VERSION ""

NS_ :

BS_:

BU_: Turbocharger OnBoardDataLogger OffBoardDiagnosticTool2 OffBoardDiagnosticTool1 FileServer ParkingBrakeController SeatControl2 FanDriveController SteeringColumnUnit CommunicationUnitRadio CommunicationUnitSatellite CommunicationUnitCellular PropulsionBatteryCharger ChassisController2 ChassisController1 EngineValveControl AuxiliaryHeater2 AuxiliaryHeater1 ClutchUnit RampControl InformationSystem1 SuspensionSystemController2 OilSensor VehicleDynamicStability ExhaustEmissionController TransmissionDisplay2 TransmissionDisplay1 ClimateControl2 WaterPumpController RearAxleSteeringController LightingOperatorControl SeatController1 IgnitionController2 IgnitionController1 TirePressureController CabController2 CabController1 PneumaticSystemController SuspensionSystemController1 HydraulicPumpController EnduranceBrakingSystem RetarderExhaustEngine2 OnBoardDiagnosticUnit HeadwayController RetarderExhaustEngine1 CabDisplay1 ManagementComputer VirtualTerminal OffVehicleGateway PowerTakeOffFront HitchControl AuxiliaryValveControl BodyController TractorTrailerBridge1 StarterSystem ElectricalSystem VehicleSecurity VehicleNavigation AerodynamicControl ElectricalChargingSystem ClimateControl1 TripRecorder InstrumentCluster SuspensionDriveAxle2 SuspensionDriveAxle1 SuspensionSteerAxle SteeringController FuelSystem CruiseControl RetarderDriveline RetarderEngine BrakesDriveAxle2 BrakesDriveAxle1 BrakesSystemController BrakesSteerAxle AxleDrive2 AxleDrive1 AxleSteering PowerTakeOff ShiftConsoleSecondary ShiftConsolePrimary Transmission2 Transmission1 Engine2 Engine1

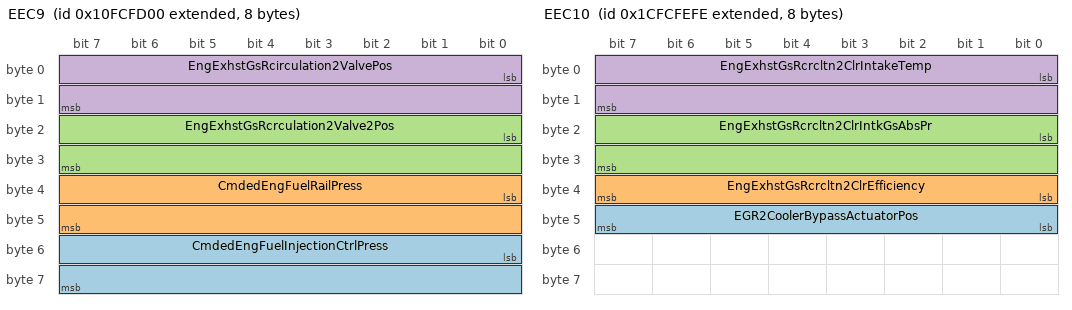
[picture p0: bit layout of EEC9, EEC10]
BO_ 2432498944 EEC9: 8 Vector__XXX
 SG_ CmdedEngFuelInjectionCtrlPress : 48|16@1+ (0.00390625,0) [0|251] "MPa" Vector__XXX
 SG_ CmdedEngFuelRailPress : 32|16@1+ (0.00390625,0) [0|251] "MPa" Vector__XXX
 SG_ EngExhstGsRcrculation2Valve2Pos : 16|16@1+ (0.0025,0) [0|160.6375] "%" Vector__XXX
 SG_ EngExhstGsRcirculation2ValvePos : 0|16@1+ (0.0025,0) [0|160.6375] "%" Vector__XXX

BO_ 2633825022 EEC11: 8 Vector__XXX
 SG_ EngExhstGsRcrclation2Valve2Ctrl : 16|16@1+ (0.0025,0) [0|160.6375] "%" Vector__XXX
 SG_ EngExhstGsRcrculation2ValveCtrl : 0|16@1+ (0.0025,0) [0|160.6375] "%" Vector__XXX

BO_ 2633826046 EEC10: 8 Vector__XXX
 SG_ EGR2CoolerBypassActuatorPos : 40|8@1+ (0.4,0) [0|100] "%" Vector__XXX
 SG_ EngExhstGsRcrcltn2ClrEfficiency : 32|8@1+ (0.4,0) [0|100] "%" Vector__XXX
 SG_ EngExhstGsRcrcltn2ClrIntkGsAbsPr : 16|16@1+ (0.5,0) [0|32127.5] "kPa" Vector__XXX
 SG_ EngExhstGsRcrcltn2ClrIntakeTemp : 0|16@1+ (0.03125,-273) [-273|1734.96875] "deg C" Vector__XXX

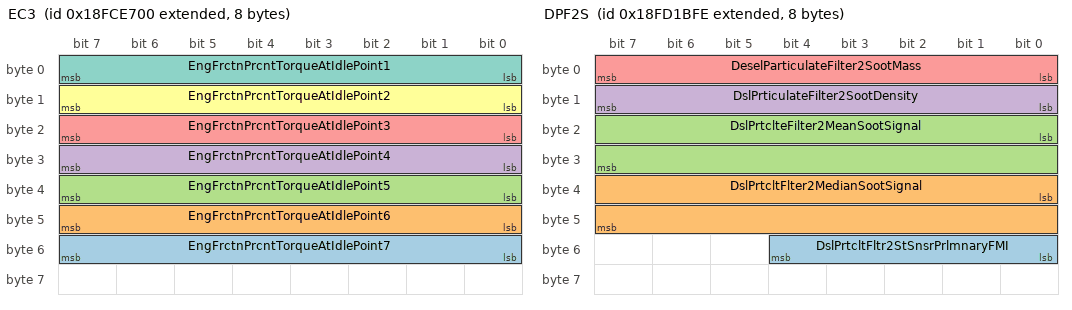
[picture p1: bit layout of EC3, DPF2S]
BO_ 2566711040 EC3: 8 Vector__XXX
 SG_ EngFrctnPrcntTorqueAtIdlePoint7 : 48|8@1+ (1,-125) [-125|125] "%" Vector__XXX
 SG_ EngFrctnPrcntTorqueAtIdlePoint6 : 40|8@1+ (1,-125) [-125|125] "%" Vector__XXX
 SG_ EngFrctnPrcntTorqueAtIdlePoint5 : 32|8@1+ (1,-125) [-125|125] "%" Vector__XXX
 SG_ EngFrctnPrcntTorqueAtIdlePoint4 : 24|8@1+ (1,-125) [-125|125] "%" Vector__XXX
 SG_ EngFrctnPrcntTorqueAtIdlePoint3 : 16|8@1+ (1,-125) [-125|125] "%" Vector__XXX
 SG_ EngFrctnPrcntTorqueAtIdlePoint2 : 8|8@1+ (1,-125) [-125|125] "%" Vector__XXX
 SG_ EngFrctnPrcntTorqueAtIdlePoint1 : 0|8@1+ (1,-125) [-125|125] "%" Vector__XXX

BO_ 2566749184 DPFC1: 8 Vector__XXX
 SG_ DslPrtcltFltrActvRgnrtnFrcdStts : 53|3@1+ (1,0) [0|7] "" Vector__XXX
 SG_ ExhaustSystemHighTempLampCmd : 50|3@1+ (1,0) [0|7] "" Vector__XXX
 SG_ DslPrtcltFltrAtmtcActvRgnrtnIntt : 48|2@1+ (1,0) [0|3] "" Vector__XXX
 SG_ DslPrtcltFltrActvRgnrtnInhbtdDTV : 46|2@1+ (1,0) [0|3] "" Vector__XXX
 SG_ DslPrtcltFltrActvRgnrtnInhbtdDTE : 44|2@1+ (1,0) [0|3] "" Vector__XXX
 SG_ DslPrtcltFltrActvRgnrtnInhbtdDTP : 42|2@1+ (1,0) [0|3] "" Vector__XXX
 SG_ DslPrtcltFltrActvRgnrtnInhbtdDTT : 40|2@1+ (1,0) [0|3] "" Vector__XXX
 SG_ DslPrtcltFltrActvRgnrtnInhbtdDTS : 38|2@1+ (1,0) [0|3] "" Vector__XXX
 SG_ DslPrtcltFltrActvRgnrtnInhb_0000 : 36|2@1+ (1,0) [0|3] "" Vector__XXX
 SG_ DslPrtcltFltrActvRgnrtnInhbtdDTL : 34|2@1+ (1,0) [0|3] "" Vector__XXX
 SG_ DslPrtcltFltrActvRgnrtnInhb_0001 : 32|2@1+ (1,0) [0|3] "" Vector__XXX
 SG_ DslPrtcltFltrActvRgnrtnInhb_0002 : 30|2@1+ (1,0) [0|3] "" Vector__XXX
 SG_ DslPrtcltFltrActvRgnrtnInhbtdDTO : 28|2@1+ (1,0) [0|3] "" Vector__XXX
 SG_ DslPrtcltFltrActvRgnrtnInhbtdDTA : 26|2@1+ (1,0) [0|3] "" Vector__XXX
 SG_ DslPrtcltFltrActvRgnrtnInhb_0003 : 24|2@1+ (1,0) [0|3] "" Vector__XXX
 SG_ DslPrtcltFltrActvRgnrtnInhb_0004 : 22|2@1+ (1,0) [0|3] "" Vector__XXX
 SG_ DslPrtcltFltrActvRgnrtnInhbtdDTC : 20|2@1+ (1,0) [0|3] "" Vector__XXX
 SG_ DslPrtcltFltrActvRgnrtnInhbtdDTI : 18|2@1+ (1,0) [0|3] "" Vector__XXX
 SG_ DslPrtcltFltrActvRgnrtnInhbtdStt : 16|2@1+ (1,0) [0|3] "" Vector__XXX
 SG_ DieselParticulateFilterStatus : 12|3@1+ (1,0) [0|7] "" Vector__XXX
 SG_ DslPrtcltFltrActvRgnrtionStatus : 10|2@1+ (1,0) [0|3] "" Vector__XXX
 SG_ DslPrtcltFltrPssvRgnrtionStatus : 8|2@1+ (1,0) [0|3] "" Vector__XXX
 SG_ DieselParticulateFilterLampCmd : 0|3@1+ (1,0) [0|7] "" Vector__XXX

BO_ 2566715646 DPF2S2: 8 Vector__XXX
 SG_ DslPrtclateFilter2SootSignalMin : 32|16@1+ (0.0025,0) [0|160.6375] "%" Vector__XXX
 SG_ DslPrtclateFilter2SootSignalMax : 16|16@1+ (0.0025,0) [0|160.6375] "%" Vector__XXX
 SG_ DslPrtcltFltr2StSgnlStndrdDvton : 0|16@1+ (0.0025,0) [0|160.6375] "%" Vector__XXX

BO_ 2566724606 DPF2S: 8 Vector__XXX
 SG_ DslPrtcltFltr2StSnsrPrlmnaryFMI : 48|5@1+ (1,0) [0|31] "" Vector__XXX
 SG_ DslPrtcltFlter2MedianSootSignal : 32|16@1+ (0.0025,0) [0|160.6375] "%" Vector__XXX
 SG_ DslPrtclteFilter2MeanSootSignal : 16|16@1+ (0.0025,0) [0|160.6375] "%" Vector__XXX
 SG_ DslPrticulateFilter2SootDensity : 8|8@1+ (0.08,0) [0|20] "g/L" Vector__XXX
 SG_ DeselParticulateFilter2SootMass : 0|8@1+ (4,0) [0|1000] "g" Vector__XXX

BO_ 2566715902 DPF1S2: 8 Vector__XXX
 SG_ DslPrtclateFilter1SootSignalMin : 32|16@1+ (0.0025,0) [0|160.6375] "%" Vector__XXX
 SG_ DslPrtclateFilter1SootSignalMax : 16|16@1+ (0.0025,0) [0|160.6375] "%" Vector__XXX
 SG_ DslPrtcltFltr1StSgnlStndrdDvton : 0|16@1+ (0.0025,0) [0|160.6375] "%" Vector__XXX

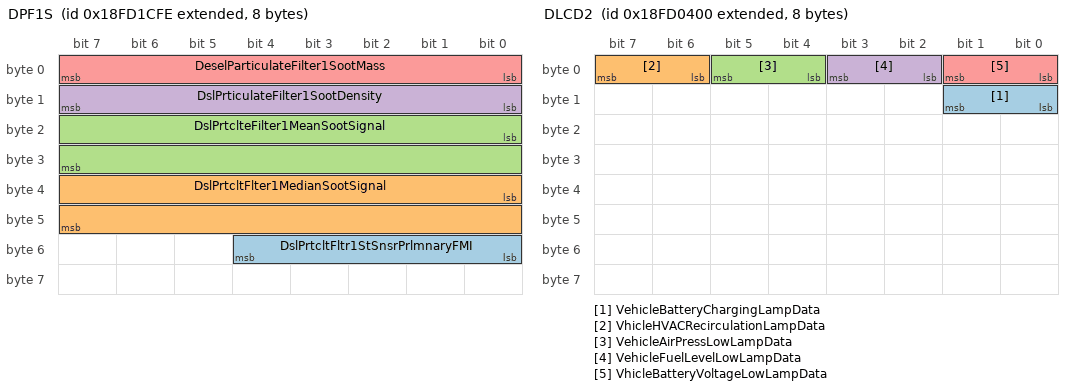
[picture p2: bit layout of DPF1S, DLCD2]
BO_ 2566724862 DPF1S: 8 Vector__XXX
 SG_ DslPrtcltFltr1StSnsrPrlmnaryFMI : 48|5@1+ (1,0) [0|31] "" Vector__XXX
 SG_ DslPrtcltFlter1MedianSootSignal : 32|16@1+ (0.0025,0) [0|160.6375] "%" Vector__XXX
 SG_ DslPrtclteFilter1MeanSootSignal : 16|16@1+ (0.0025,0) [0|160.6375] "%" Vector__XXX
 SG_ DslPrticulateFilter1SootDensity : 8|8@1+ (0.08,0) [0|20] "g/L" Vector__XXX
 SG_ DeselParticulateFilter1SootMass : 0|8@1+ (4,0) [0|1000] "g" Vector__XXX

BO_ 2566718464 DLCD2: 8 Vector__XXX
 SG_ VehicleBatteryChargingLampData : 8|2@1+ (1,0) [0|3] "" Vector__XXX
 SG_ VhicleHVACRecirculationLampData : 6|2@1+ (1,0) [0|3] "" Vector__XXX
 SG_ VehicleAirPressLowLampData : 4|2@1+ (1,0) [0|3] "" Vector__XXX
 SG_ VehicleFuelLevelLowLampData : 2|2@1+ (1,0) [0|3] "" Vector__XXX
 SG_ VhicleBatteryVoltageLowLampData : 0|2@1+ (1,0) [0|3] "" Vector__XXX

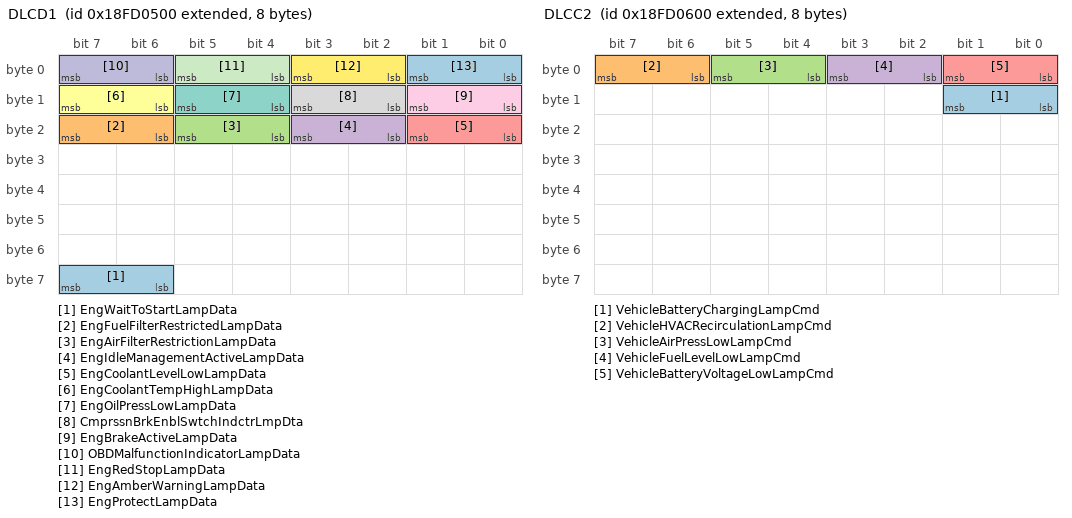
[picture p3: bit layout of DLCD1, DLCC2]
BO_ 2566718720 DLCD1: 8 Vector__XXX
 SG_ EngWaitToStartLampData : 62|2@1+ (1,0) [0|3] "" Vector__XXX
 SG_ EngFuelFilterRestrictedLampData : 22|2@1+ (1,0) [0|3] "" Vector__XXX
 SG_ EngAirFilterRestrictionLampData : 20|2@1+ (1,0) [0|3] "" Vector__XXX
 SG_ EngIdleManagementActiveLampData : 18|2@1+ (1,0) [0|3] "" Vector__XXX
 SG_ EngCoolantLevelLowLampData : 16|2@1+ (1,0) [0|3] "" Vector__XXX
 SG_ EngCoolantTempHighLampData : 14|2@1+ (1,0) [0|3] "" Vector__XXX
 SG_ EngOilPressLowLampData : 12|2@1+ (1,0) [0|3] "" Vector__XXX
 SG_ CmprssnBrkEnblSwtchIndctrLmpDta : 10|2@1+ (1,0) [0|3] "" Vector__XXX
 SG_ EngBrakeActiveLampData : 8|2@1+ (1,0) [0|3] "" Vector__XXX
 SG_ OBDMalfunctionIndicatorLampData : 6|2@1+ (1,0) [0|3] "" Vector__XXX
 SG_ EngRedStopLampData : 4|2@1+ (1,0) [0|3] "" Vector__XXX
 SG_ EngAmberWarningLampData : 2|2@1+ (1,0) [0|3] "" Vector__XXX
 SG_ EngProtectLampData : 0|2@1+ (1,0) [0|3] "" Vector__XXX

BO_ 2566718976 DLCC2: 8 Vector__XXX
 SG_ VehicleBatteryChargingLampCmd : 8|2@1+ (1,0) [0|3] "" Vector__XXX
 SG_ VehicleHVACRecirculationLampCmd : 6|2@1+ (1,0) [0|3] "" Vector__XXX
 SG_ VehicleAirPressLowLampCmd : 4|2@1+ (1,0) [0|3] "" Vector__XXX
 SG_ VehicleFuelLevelLowLampCmd : 2|2@1+ (1,0) [0|3] "" Vector__XXX
 SG_ VehicleBatteryVoltageLowLampCmd : 0|2@1+ (1,0) [0|3] "" Vector__XXX

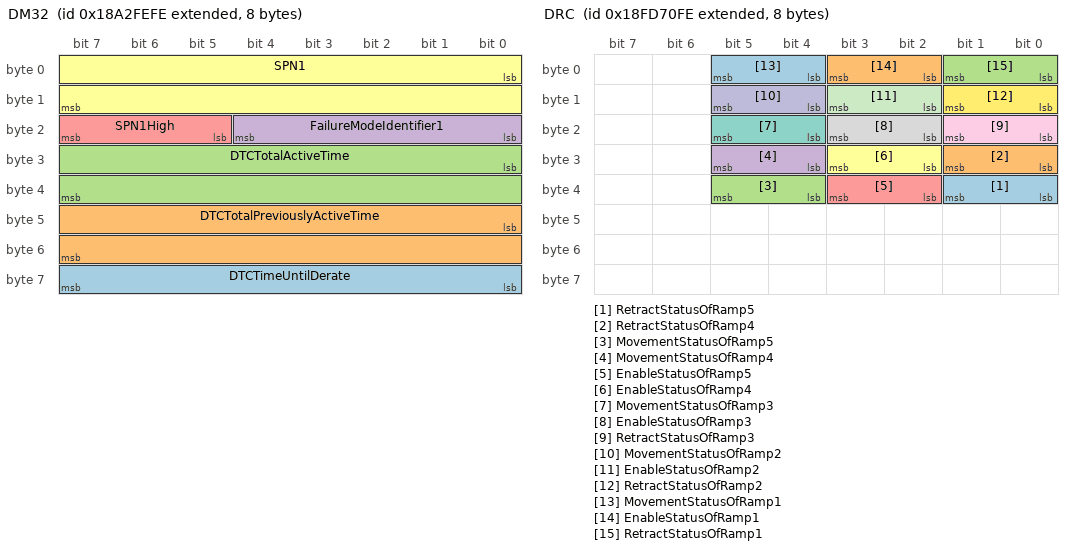
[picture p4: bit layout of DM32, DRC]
BO_ 2560818942 DM32: 8 Vector__XXX
 SG_ DTCTimeUntilDerate : 56|8@1+ (0.25,0) [0|62.5] "hr" Vector__XXX
 SG_ DTCTotalPreviouslyActiveTime : 40|16@1+ (0.2,0) [0|12851] "hr" Vector__XXX
 SG_ DTCTotalActiveTime : 24|16@1+ (0.2,0) [0|12851] "hr" Vector__XXX
 SG_ FailureModeIdentifier1 : 16|5@1+ (1,0) [0|0] "" Vector__XXX
 SG_ SPN1High : 21|3@1+ (1,0) [0|7] "" Vector__XXX
 SG_ SPN1 : 0|16@1+ (1,0) [0|65536] "" Vector__XXX

BO_ 2561212158 DISP1: 8 Vector__XXX
 SG_ TextDisplayIndex : 16|8@1+ (1,0) [0|250] "" Vector__XXX
 SG_ TextDisplayInstructions : 0|4@1+ (1,0) [0|15] "" Vector__XXX

BO_ 2566746366 DRC: 8 Vector__XXX
 SG_ RetractStatusOfRamp5 : 32|2@1+ (1,0) [0|3] "" Vector__XXX
 SG_ RetractStatusOfRamp4 : 24|2@1+ (1,0) [0|3] "" Vector__XXX
 SG_ MovementStatusOfRamp5 : 36|2@1+ (1,0) [0|3] "" Vector__XXX
 SG_ MovementStatusOfRamp4 : 28|2@1+ (1,0) [0|3] "" Vector__XXX
 SG_ EnableStatusOfRamp5 : 34|2@1+ (1,0) [0|3] "" Vector__XXX
 SG_ EnableStatusOfRamp4 : 26|2@1+ (1,0) [0|3] "" Vector__XXX
 SG_ MovementStatusOfRamp3 : 20|2@1+ (1,0) [0|3] "" Vector__XXX
 SG_ EnableStatusOfRamp3 : 18|2@1+ (1,0) [0|3] "" Vector__XXX
 SG_ RetractStatusOfRamp3 : 16|2@1+ (1,0) [0|3] "" Vector__XXX
 SG_ MovementStatusOfRamp2 : 12|2@1+ (1,0) [0|3] "" Vector__XXX
 SG_ EnableStatusOfRamp2 : 10|2@1+ (1,0) [0|3] "" Vector__XXX
 SG_ RetractStatusOfRamp2 : 8|2@1+ (1,0) [0|3] "" Vector__XXX
 SG_ MovementStatusOfRamp1 : 4|2@1+ (1,0) [0|3] "" Vector__XXX
 SG_ EnableStatusOfRamp1 : 2|2@1+ (1,0) [0|3] "" Vector__XXX
 SG_ RetractStatusOfRamp1 : 0|2@1+ (1,0) [0|3] "" Vector__XXX

BO_ 2566749952 EC2: 8 Vector__XXX
 SG_ MaxCrankAttemptsPerStartAttempt : 0|8@1+ (1,0) [0|250] "" Vector__XXX

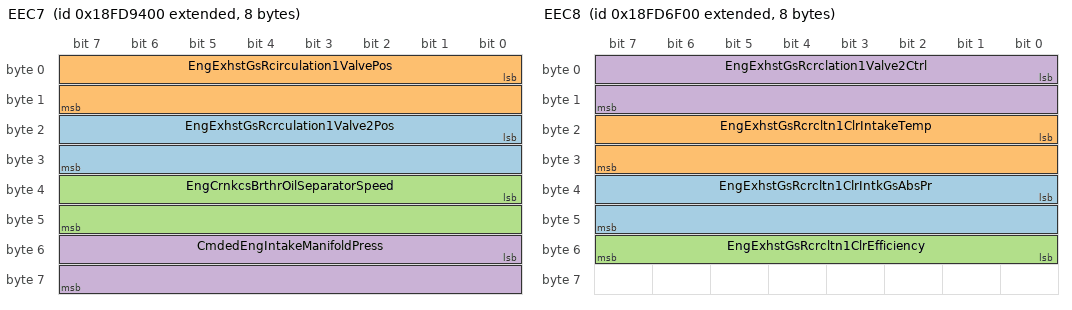
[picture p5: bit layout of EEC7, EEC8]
BO_ 2566755328 EEC7: 8 Vector__XXX
 SG_ EngExhstGsRcrculation1Valve2Pos : 16|16@1+ (0.0025,0) [0|160.6375] "%" Vector__XXX
 SG_ EngExhstGsRcirculation1ValvePos : 0|16@1+ (0.0025,0) [0|160.6375] "%" Vector__XXX
 SG_ EngCrnkcsBrthrOilSeparatorSpeed : 32|16@1+ (1,0) [0|64255] "rpm" Vector__XXX
 SG_ CmdedEngIntakeManifoldPress : 48|16@1+ (0.125,0) [0|8031.875] "kPa" Vector__XXX

BO_ 2566745856 EEC8: 8 Vector__XXX
 SG_ EngExhstGsRcrcltn1ClrIntkGsAbsPr : 32|16@1+ (0.5,0) [0|32127.5] "kPa" Vector__XXX
 SG_ EngExhstGsRcrcltn1ClrIntakeTemp : 16|16@1+ (0.03125,-273) [-273|1734.96875] "deg C" Vector__XXX
 SG_ EngExhstGsRcrcltn1ClrEfficiency : 48|8@1+ (0.4,0) [0|100] "%" Vector__XXX
 SG_ EngExhstGsRcrclation1Valve2Ctrl : 0|16@1+ (0.0025,0) [0|160.6375] "%" Vector__XXX

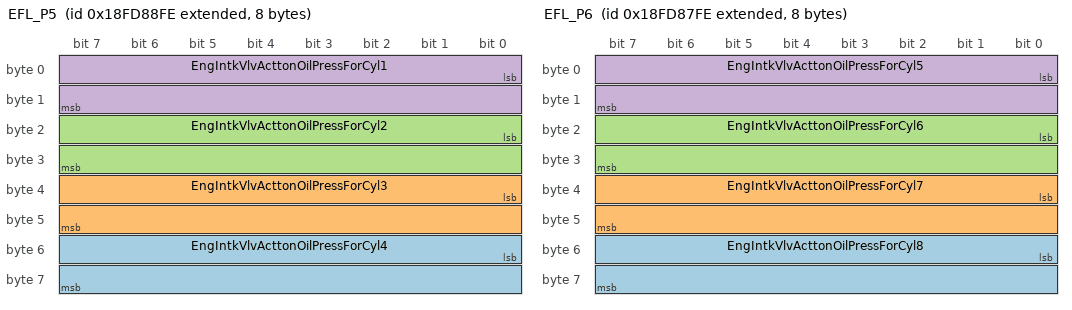
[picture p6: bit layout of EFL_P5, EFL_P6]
BO_ 2566752510 EFL_P5: 8 Vector__XXX
 SG_ EngIntkVlvActtonOilPressForCyl4 : 48|16@1+ (0.1,0) [0|6425.5] "kPa" Vector__XXX
 SG_ EngIntkVlvActtonOilPressForCyl3 : 32|16@1+ (0.1,0) [0|6425.5] "kPa" Vector__XXX
 SG_ EngIntkVlvActtonOilPressForCyl2 : 16|16@1+ (0.1,0) [0|6425.5] "kPa" Vector__XXX
 SG_ EngIntkVlvActtonOilPressForCyl1 : 0|16@1+ (0.1,0) [0|6425.5] "kPa" Vector__XXX

BO_ 2566752254 EFL_P6: 8 Vector__XXX
 SG_ EngIntkVlvActtonOilPressForCyl8 : 48|16@1+ (0.1,0) [0|6425.5] "kPa" Vector__XXX
 SG_ EngIntkVlvActtonOilPressForCyl7 : 32|16@1+ (0.1,0) [0|6425.5] "kPa" Vector__XXX
 SG_ EngIntkVlvActtonOilPressForCyl6 : 16|16@1+ (0.1,0) [0|6425.5] "kPa" Vector__XXX
 SG_ EngIntkVlvActtonOilPressForCyl5 : 0|16@1+ (0.1,0) [0|6425.5] "kPa" Vector__XXX

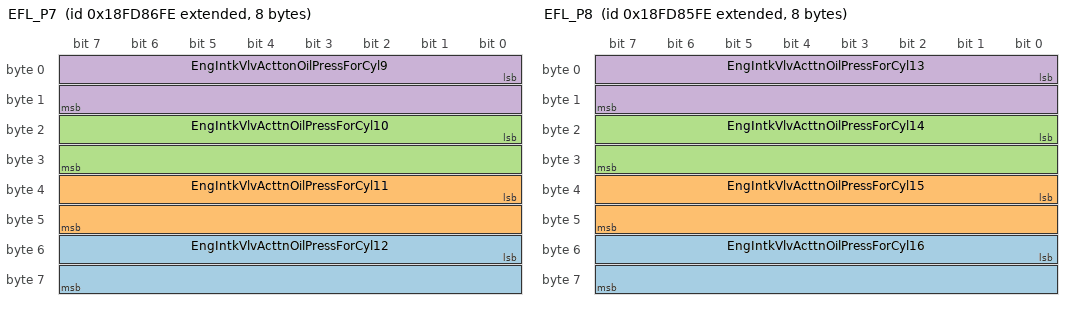
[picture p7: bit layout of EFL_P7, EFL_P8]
BO_ 2566751998 EFL_P7: 8 Vector__XXX
 SG_ EngIntkVlvActtnOilPressForCyl12 : 48|16@1+ (0.1,0) [0|6425.5] "kPa" Vector__XXX
 SG_ EngIntkVlvActtnOilPressForCyl11 : 32|16@1+ (0.1,0) [0|6425.5] "kPa" Vector__XXX
 SG_ EngIntkVlvActtnOilPressForCyl10 : 16|16@1+ (0.1,0) [0|6425.5] "kPa" Vector__XXX
 SG_ EngIntkVlvActtonOilPressForCyl9 : 0|16@1+ (0.1,0) [0|6425.5] "kPa" Vector__XXX

BO_ 2566751742 EFL_P8: 8 Vector__XXX
 SG_ EngIntkVlvActtnOilPressForCyl16 : 48|16@1+ (0.1,0) [0|6425.5] "kPa" Vector__XXX
 SG_ EngIntkVlvActtnOilPressForCyl15 : 32|16@1+ (0.1,0) [0|6425.5] "kPa" Vector__XXX
 SG_ EngIntkVlvActtnOilPressForCyl14 : 16|16@1+ (0.1,0) [0|6425.5] "kPa" Vector__XXX
 SG_ EngIntkVlvActtnOilPressForCyl13 : 0|16@1+ (0.1,0) [0|6425.5] "kPa" Vector__XXX

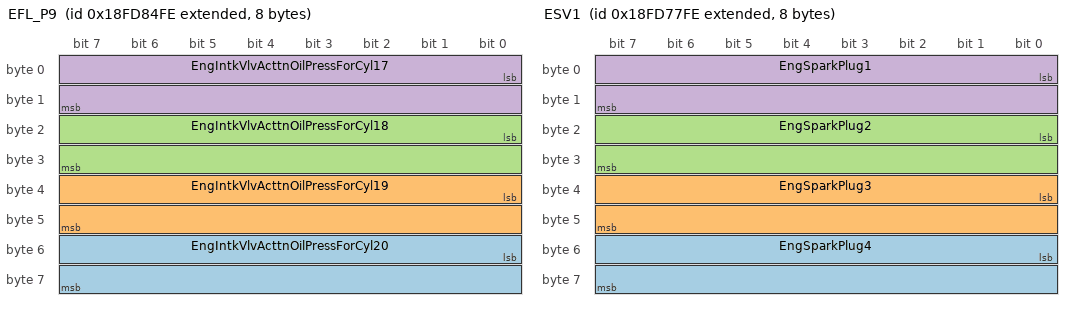
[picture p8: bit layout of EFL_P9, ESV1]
BO_ 2566751486 EFL_P9: 8 Vector__XXX
 SG_ EngIntkVlvActtnOilPressForCyl20 : 48|16@1+ (0.1,0) [0|6425.5] "kPa" Vector__XXX
 SG_ EngIntkVlvActtnOilPressForCyl19 : 32|16@1+ (0.1,0) [0|6425.5] "kPa" Vector__XXX
 SG_ EngIntkVlvActtnOilPressForCyl18 : 16|16@1+ (0.1,0) [0|6425.5] "kPa" Vector__XXX
 SG_ EngIntkVlvActtnOilPressForCyl17 : 0|16@1+ (0.1,0) [0|6425.5] "kPa" Vector__XXX

BO_ 2499641854 EGRBV: 8 Vector__XXX
 SG_ EGR1CoolerBypassActuatorPostion : 0|8@1+ (0.4,0) [0|100] "%" Vector__XXX

BO_ 2566748158 ESV1: 8 Vector__XXX
 SG_ EngSparkPlug4 : 48|16@1+ (1,0) [0|64255] "Volts" Vector__XXX
 SG_ EngSparkPlug3 : 32|16@1+ (1,0) [0|64255] "Volts" Vector__XXX
 SG_ EngSparkPlug2 : 16|16@1+ (1,0) [0|64255] "Volts" Vector__XXX
 SG_ EngSparkPlug1 : 0|16@1+ (1,0) [0|64255] "Volts" Vector__XXX

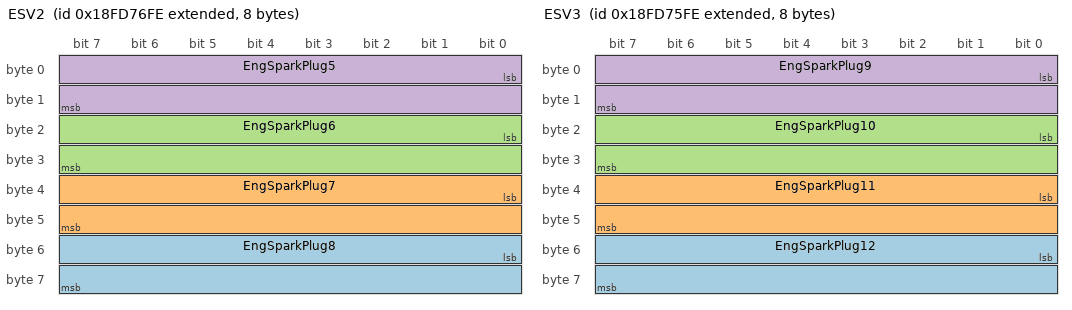
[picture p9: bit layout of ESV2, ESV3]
BO_ 2566747902 ESV2: 8 Vector__XXX
 SG_ EngSparkPlug8 : 48|16@1+ (1,0) [0|64255] "Volts" Vector__XXX
 SG_ EngSparkPlug7 : 32|16@1+ (1,0) [0|64255] "Volts" Vector__XXX
 SG_ EngSparkPlug6 : 16|16@1+ (1,0) [0|64255] "Volts" Vector__XXX
 SG_ EngSparkPlug5 : 0|16@1+ (1,0) [0|64255] "Volts" Vector__XXX

BO_ 2566747646 ESV3: 8 Vector__XXX
 SG_ EngSparkPlug12 : 48|16@1+ (1,0) [0|64255] "Volts" Vector__XXX
 SG_ EngSparkPlug11 : 32|16@1+ (1,0) [0|64255] "Volts" Vector__XXX
 SG_ EngSparkPlug10 : 16|16@1+ (1,0) [0|64255] "Volts" Vector__XXX
 SG_ EngSparkPlug9 : 0|16@1+ (1,0) [0|64255] "Volts" Vector__XXX

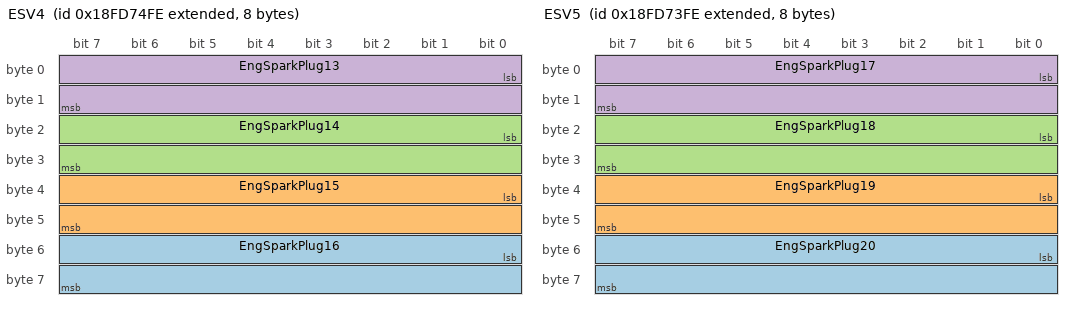
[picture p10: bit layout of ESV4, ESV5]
BO_ 2566747390 ESV4: 8 Vector__XXX
 SG_ EngSparkPlug16 : 48|16@1+ (1,0) [0|64255] "Volts" Vector__XXX
 SG_ EngSparkPlug15 : 32|16@1+ (1,0) [0|64255] "Volts" Vector__XXX
 SG_ EngSparkPlug14 : 16|16@1+ (1,0) [0|64255] "Volts" Vector__XXX
 SG_ EngSparkPlug13 : 0|16@1+ (1,0) [0|64255] "Volts" Vector__XXX

BO_ 2566747134 ESV5: 8 Vector__XXX
 SG_ EngSparkPlug20 : 48|16@1+ (1,0) [0|64255] "Volts" Vector__XXX
 SG_ EngSparkPlug19 : 32|16@1+ (1,0) [0|64255] "Volts" Vector__XXX
 SG_ EngSparkPlug18 : 16|16@1+ (1,0) [0|64255] "Volts" Vector__XXX
 SG_ EngSparkPlug17 : 0|16@1+ (1,0) [0|64255] "Volts" Vector__XXX

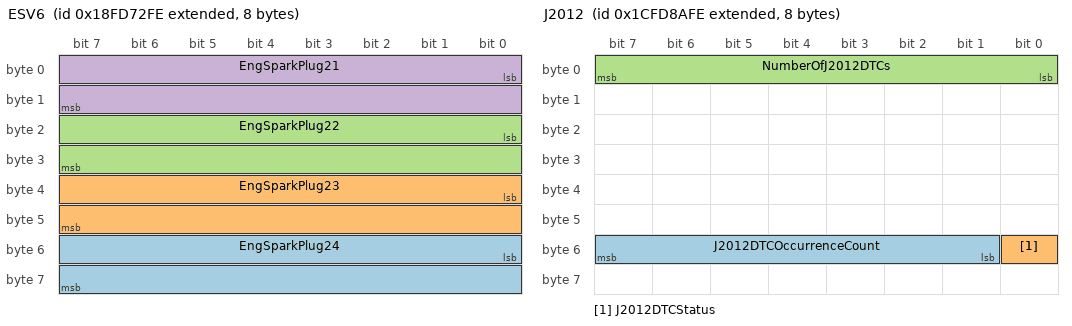
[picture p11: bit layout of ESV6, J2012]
BO_ 2566746878 ESV6: 8 Vector__XXX
 SG_ EngSparkPlug24 : 48|16@1+ (1,0) [0|64255] "Volts" Vector__XXX
 SG_ EngSparkPlug23 : 32|16@1+ (1,0) [0|64255] "Volts" Vector__XXX
 SG_ EngSparkPlug22 : 16|16@1+ (1,0) [0|64255] "Volts" Vector__XXX
 SG_ EngSparkPlug21 : 0|16@1+ (1,0) [0|64255] "Volts" Vector__XXX

BO_ 2561277694 FLIC: 8 Vector__XXX
 SG_ LaneDepartureWarningEnableCmd : 0|2@1+ (1,0) [0|3] "" Vector__XXX

BO_ 2633861886 J2012: 8 Vector__XXX
 SG_ J2012DTCOccurrenceCount : 49|7@1+ (1,0) [0|127] "" Vector__XXX
 SG_ J2012DTCStatus : 48|1@1+ (1,0) [0|1] "" Vector__XXX
 SG_ NumberOfJ2012DTCs : 0|8@1+ (1,0) [0|250] "" Vector__XXX

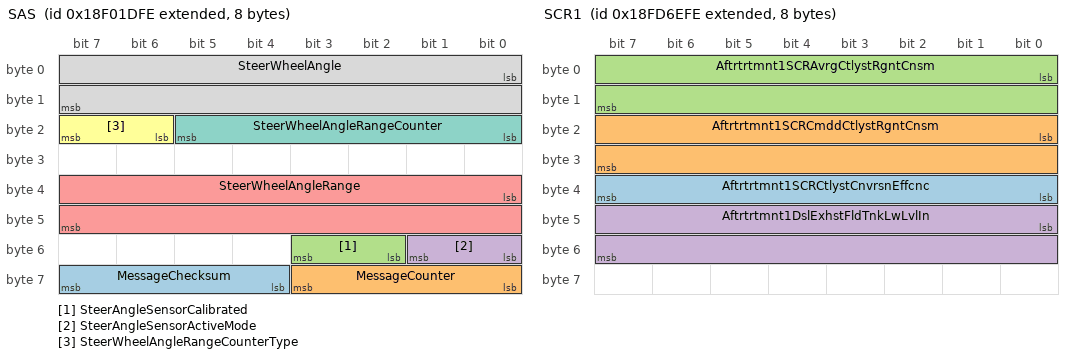
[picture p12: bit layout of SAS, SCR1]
BO_ 2565873150 SAS: 8 Vector__XXX
 SG_ MessageChecksum : 60|4@1+ (1,0) [0|15] "" Vector__XXX
 SG_ MessageCounter : 56|4@1+ (1,0) [0|15] "" Vector__XXX
 SG_ SteerAngleSensorCalibrated : 50|2@1+ (1,0) [0|3] "" Vector__XXX
 SG_ SteerAngleSensorActiveMode : 48|2@1+ (1,0) [0|3] "" Vector__XXX
 SG_ SteerWheelAngleRange : 32|16@1+ (0.0009765625,-31.374) [-31.374|31.374] "rad" Vector__XXX
 SG_ SteerWheelAngleRangeCounterType : 22|2@1+ (1,0) [0|3] "" Vector__XXX
 SG_ SteerWheelAngleRangeCounter : 16|6@1+ (1,-32) [-32|29] "ranges" Vector__XXX
 SG_ SteerWheelAngle : 0|16@1+ (0.0009765625,-31.374) [-31.374|31.374] "rad" Vector__XXX

BO_ 2566745854 SCR1: 8 Vector__XXX
 SG_ Aftrtrtmnt1SCRCtlystCnvrsnEffcnc : 32|8@1+ (0.4,0) [0|100] "%" Vector__XXX
 SG_ Aftrtrtmnt1SCRCmddCtlystRgntCnsm : 16|16@1+ (0.05,0) [0|3212.75] "L/h" Vector__XXX
 SG_ Aftrtrtmnt1SCRAvrgCtlystRgntCnsm : 0|16@1+ (0.05,0) [0|3212.75] "L/h" Vector__XXX
 SG_ Aftrtrtmnt1DslExhstFldTnkLwLvlIn : 40|16@1+ (1,0) [0|64255] "km" Vector__XXX

BO_ 2566751230 TCI: 8 Vector__XXX
 SG_ TransferCaseStatus : 0|3@1+ (1,0) [0|7] "" Vector__XXX

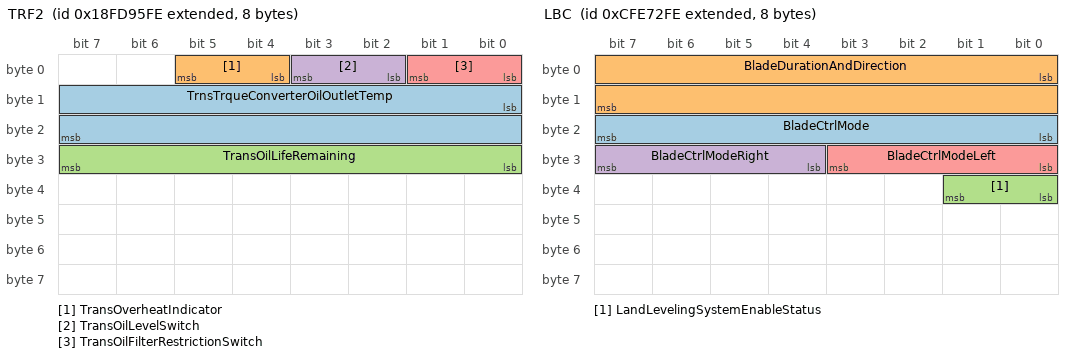
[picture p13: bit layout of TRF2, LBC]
BO_ 2566755838 TRF2: 8 Vector__XXX
 SG_ TrnsTrqueConverterOilOutletTemp : 8|16@1+ (0.03125,-273) [-273|1734.96875] "deg C" Vector__XXX
 SG_ TransOverheatIndicator : 4|2@1+ (1,0) [0|3] "" Vector__XXX
 SG_ TransOilLifeRemaining : 24|8@1+ (0.4,0) [0|100] "%" Vector__XXX
 SG_ TransOilLevelSwitch : 2|2@1+ (1,0) [0|3] "" Vector__XXX
 SG_ TransOilFilterRestrictionSwitch : 0|2@1+ (1,0) [0|3] "" Vector__XXX

BO_ 2566752766 VDS2: 8 Vector__XXX
 SG_ VehicleRoll : 0|16@1+ (0.0078125,-200) [-200|301.99] "deg" Vector__XXX

BO_ 2633938942 LF: 10 Vector__XXX
 SG_ TotalEngCruiseTime : 48|32@1+ (0.05,0) [0|210554060.75] "hr" Vector__XXX
 SG_ TotalDriveAverageLoadFactor : 40|8@1+ (0.4,0) [0|100] "%" Vector__XXX
 SG_ TripDriveAverageLoadFactor : 32|8@1+ (0.4,0) [0|100] "%" Vector__XXX
 SG_ TripAverageEngSpeed : 16|16@1+ (0.125,0) [0|8031.875] "rpm" Vector__XXX
 SG_ TripMaxEngSpeed : 0|16@1+ (0.125,0) [0|8031.875] "rpm" Vector__XXX

BO_ 2566799614 LD: 8 Vector__XXX
 SG_ ImplementRearWorkLight : 62|2@1+ (1,0) [0|3] "" Vector__XXX
 SG_ ImplementLeftForwardWorkLight : 60|2@1+ (1,0) [0|3] "" Vector__XXX
 SG_ ImplementRightForwardWorkLight : 58|2@1+ (1,0) [0|3] "" Vector__XXX
 SG_ ImplementLeftFacingWorkLight : 54|2@1+ (1,0) [0|3] "" Vector__XXX
 SG_ ImplementRightFacingWorkLight : 52|2@1+ (1,0) [0|3] "" Vector__XXX
 SG_ ImplementOEMOption1Light : 50|2@1+ (1,0) [0|3] "" Vector__XXX
 SG_ ImplementOEMOption2Light : 48|2@1+ (1,0) [0|3] "" Vector__XXX
 SG_ TrctrFrontHighMountedWorkLights : 46|2@1+ (1,0) [0|3] "" Vector__XXX
 SG_ TrctorFrontLowMountedWorkLights : 44|2@1+ (1,0) [0|3] "" Vector__XXX
 SG_ TrctorSideHighMountedWorkLights : 42|2@1+ (1,0) [0|3] "" Vector__XXX
 SG_ TractorSideLowMountedWorkLights : 40|2@1+ (1,0) [0|3] "" Vector__XXX
 SG_ TrctorRearHighMountedWorkLights : 38|2@1+ (1,0) [0|3] "" Vector__XXX
 SG_ TractorRearLowMountedWorkLights : 36|2@1+ (1,0) [0|3] "" Vector__XXX
 SG_ TrctrUndersideMountedWorkLights : 34|2@1+ (1,0) [0|3] "" Vector__XXX
 SG_ RearFogLights : 32|2@1+ (1,0) [0|3] "" Vector__XXX
 SG_ TractorMarkerLight : 30|2@1+ (1,0) [0|3] "" Vector__XXX
 SG_ ImplementMarkerLight : 28|2@1+ (1,0) [0|3] "" Vector__XXX
 SG_ TractorClearanceLight : 26|2@1+ (1,0) [0|3] "" Vector__XXX
 SG_ ImplementClearanceLight : 24|2@1+ (1,0) [0|3] "" Vector__XXX
 SG_ LeftStopLight : 22|2@1+ (1,0) [0|3] "" Vector__XXX
 SG_ RightStopLight : 20|2@1+ (1,0) [0|3] "" Vector__XXX
 SG_ CenterStopLight : 18|2@1+ (1,0) [0|3] "" Vector__XXX
 SG_ BackUpLightAndAlarmHorn : 16|2@1+ (1,0) [0|3] "" Vector__XXX
 SG_ LeftTurnSignalLights : 14|2@1+ (1,0) [0|3] "" Vector__XXX
 SG_ RightTurnSignalLights : 12|2@1+ (1,0) [0|3] "" Vector__XXX
 SG_ RotatingBeaconLight : 10|2@1+ (1,0) [0|3] "" Vector__XXX
 SG_ TractorFrontFogLights : 8|2@1+ (1,0) [0|3] "" Vector__XXX
 SG_ HighBeamHeadLightData : 6|2@1+ (1,0) [0|3] "" Vector__XXX
 SG_ LowBeamHeadLightData : 4|2@1+ (1,0) [0|3] "" Vector__XXX
 SG_ AltBeamHeadLightData : 2|2@1+ (1,0) [0|3] "" Vector__XXX
 SG_ RunningLight : 0|2@1+ (1,0) [0|3] "" Vector__XXX

BO_ 2365473278 LC: 8 Vector__XXX
 SG_ ImplementRearWorkLightCmd : 62|2@1+ (1,0) [0|3] "" Vector__XXX
 SG_ ImplmentLeftForwardWorkLightCmd : 60|2@1+ (1,0) [0|3] "" Vector__XXX
 SG_ ImplmntRightForwardWorkLightCmd : 58|2@1+ (1,0) [0|3] "" Vector__XXX
 SG_ LightingDataRqCmd : 56|2@1+ (1,0) [0|3] "" Vector__XXX
 SG_ ImplementLeftFacingWorkLightCmd : 54|2@1+ (1,0) [0|3] "" Vector__XXX
 SG_ ImplmentRightFacingWorkLightCmd : 52|2@1+ (1,0) [0|3] "" Vector__XXX
 SG_ ImplementOEMOption1LightCmd : 50|2@1+ (1,0) [0|3] "" Vector__XXX
 SG_ ImplementOEMOption2LightCmd : 48|2@1+ (1,0) [0|3] "" Vector__XXX
 SG_ TrctrFrntHghMuntedWorkLightsCmd : 46|2@1+ (1,0) [0|3] "" Vector__XXX
 SG_ TrctrFrntLwMountedWorkLightsCmd : 44|2@1+ (1,0) [0|3] "" Vector__XXX
 SG_ TrctrSdHighMountedWorkLightsCmd : 42|2@1+ (1,0) [0|3] "" Vector__XXX
 SG_ TrctrSdeLowMountedWorkLightsCmd : 40|2@1+ (1,0) [0|3] "" Vector__XXX
 SG_ TrctrRrHighMountedWorkLightsCmd : 38|2@1+ (1,0) [0|3] "" Vector__XXX
 SG_ TrctrRarLowMountedWorkLightsCmd : 36|2@1+ (1,0) [0|3] "" Vector__XXX
 SG_ TrctrUndrsdMountedWorkLightsCmd : 34|2@1+ (1,0) [0|3] "" Vector__XXX
 SG_ RearFogLightCmd : 32|2@1+ (1,0) [0|3] "" Vector__XXX
 SG_ TractorMarkerLightCmd : 30|2@1+ (1,0) [0|3] "" Vector__XXX
 SG_ ImplementMarkerLightCmd : 28|2@1+ (1,0) [0|3] "" Vector__XXX
 SG_ TractorClearanceLightCmd : 26|2@1+ (1,0) [0|3] "" Vector__XXX
 SG_ ImplementClearanceLightCmd : 24|2@1+ (1,0) [0|3] "" Vector__XXX
 SG_ LeftStopLightCmd : 22|2@1+ (1,0) [0|3] "" Vector__XXX
 SG_ RightStopLightCmd : 20|2@1+ (1,0) [0|3] "" Vector__XXX
 SG_ CenterStopLightCmd : 18|2@1+ (1,0) [0|3] "" Vector__XXX
 SG_ BackUpLightAndAlarmHornCmd : 16|2@1+ (1,0) [0|3] "" Vector__XXX
 SG_ LeftTurnSignalLightsCmd : 14|2@1+ (1,0) [0|3] "" Vector__XXX
 SG_ RightTurnSignalLightsCmd : 12|2@1+ (1,0) [0|3] "" Vector__XXX
 SG_ RotatingBeaconLightCmd : 10|2@1+ (1,0) [0|3] "" Vector__XXX
 SG_ TractorFrontFogLightsCmd : 8|2@1+ (1,0) [0|3] "" Vector__XXX
 SG_ HighBeamHeadLightCmd : 6|2@1+ (1,0) [0|3] "" Vector__XXX
 SG_ LowBeamHeadLightCmd : 4|2@1+ (1,0) [0|3] "" Vector__XXX
 SG_ AltBeamHeadLightCmd : 2|2@1+ (1,0) [0|3] "" Vector__XXX
 SG_ RunningLightCmd : 0|2@1+ (1,0) [0|3] "" Vector__XXX

BO_ 2365485822 LBC: 8 Vector__XXX
 SG_ BladeCtrlMode : 16|8@1+ (1,0) [0|255] "" Vector__XXX
 SG_ BladeDurationAndDirection : 0|16@1+ (0.1,-3276.8) [-3276.8|3148.7] "sec" Vector__XXX
 SG_ LandLevelingSystemEnableStatus : 32|2@1+ (1,0) [0|3] "" Vector__XXX
 SG_ BladeCtrlModeRight : 28|4@1+ (1,0) [0|15] "" Vector__XXX
 SG_ BladeCtrlModeLeft : 24|4@1+ (1,0) [0|15] "" Vector__XXX

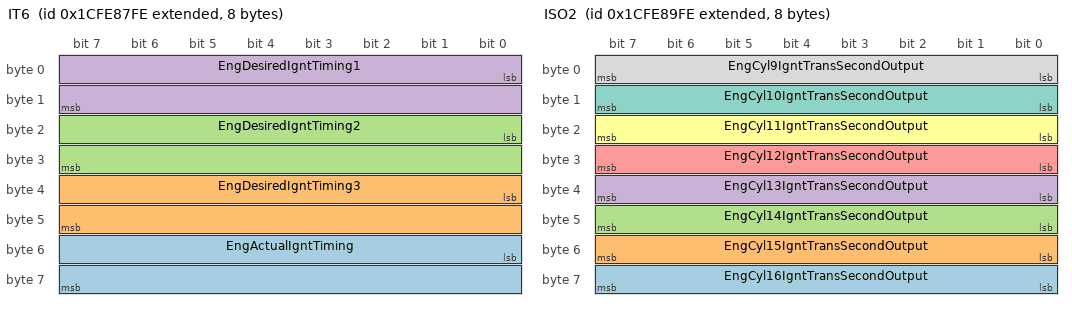
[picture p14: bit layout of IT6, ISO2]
BO_ 2633926654 IT6: 8 Vector__XXX
 SG_ EngActualIgntTiming : 48|16@1+ (0.0078125,-200) [-200|301.99] "deg" Vector__XXX
 SG_ EngDesiredIgntTiming3 : 32|16@1+ (0.0078125,-200) [-200|301.99] "deg" Vector__XXX
 SG_ EngDesiredIgntTiming2 : 16|16@1+ (0.0078125,-200) [-200|301.99] "deg" Vector__XXX
 SG_ EngDesiredIgntTiming1 : 0|16@1+ (0.0078125,-200) [-200|301.99] "deg" Vector__XXX

BO_ 2633926398 IT5: 8 Vector__XXX
 SG_ EngCyl20IgntTiming : 48|16@1+ (0.0078125,-200) [-200|301.99] "deg" Vector__XXX
 SG_ EngCyl19IgntTiming : 32|16@1+ (0.0078125,-200) [-200|301.99] "deg" Vector__XXX
 SG_ EngCyl18IgntTiming : 16|16@1+ (0.0078125,-200) [-200|301.99] "deg" Vector__XXX
 SG_ EngCyl17IgntTiming : 0|16@1+ (0.0078125,-200) [-200|301.99] "deg" Vector__XXX

BO_ 2633926142 IT4: 8 Vector__XXX
 SG_ EngCyl16IgntTiming : 48|16@1+ (0.0078125,-200) [-200|301.99] "deg" Vector__XXX
 SG_ EngCyl15IgntTiming : 32|16@1+ (0.0078125,-200) [-200|301.99] "deg" Vector__XXX
 SG_ EngCyl14IgntTiming : 16|16@1+ (0.0078125,-200) [-200|301.99] "deg" Vector__XXX
 SG_ EngCyl13IgntTiming : 0|16@1+ (0.0078125,-200) [-200|301.99] "deg" Vector__XXX

BO_ 2633925886 IT3: 8 Vector__XXX
 SG_ EngCyl12IgntTiming : 48|16@1+ (0.0078125,-200) [-200|301.99] "deg" Vector__XXX
 SG_ EngCyl11IgntTiming : 32|16@1+ (0.0078125,-200) [-200|301.99] "deg" Vector__XXX
 SG_ EngCyl10IgntTiming : 16|16@1+ (0.0078125,-200) [-200|301.99] "deg" Vector__XXX
 SG_ EngCyl9IgntTiming : 0|16@1+ (0.0078125,-200) [-200|301.99] "deg" Vector__XXX

BO_ 2633925630 IT2: 8 Vector__XXX
 SG_ EngCyl8IgntTiming : 48|16@1+ (0.0078125,-200) [-200|301.99] "deg" Vector__XXX
 SG_ EngCyl7IgntTiming : 32|16@1+ (0.0078125,-200) [-200|301.99] "deg" Vector__XXX
 SG_ EngCyl6IgntTiming : 16|16@1+ (0.0078125,-200) [-200|301.99] "deg" Vector__XXX
 SG_ EngCyl5IgntTiming : 0|16@1+ (0.0078125,-200) [-200|301.99] "deg" Vector__XXX

BO_ 2633925374 IT1: 8 Vector__XXX
 SG_ EngCyl4IgntTiming : 48|16@1+ (0.0078125,-200) [-200|301.99] "deg" Vector__XXX
 SG_ EngCyl3IgntTiming : 32|16@1+ (0.0078125,-200) [-200|301.99] "deg" Vector__XXX
 SG_ EngCyl2IgntTiming : 16|16@1+ (0.0078125,-200) [-200|301.99] "deg" Vector__XXX
 SG_ EngCyl1IgntTiming : 0|16@1+ (0.0078125,-200) [-200|301.99] "deg" Vector__XXX

BO_ 2633927422 ISO3: 8 Vector__XXX
 SG_ EngCyl20IgntTransSecondOutput : 24|8@1+ (1,-125) [-125|125] "%" Vector__XXX
 SG_ EngCyl19IgntTransSecondOutput : 16|8@1+ (1,-125) [-125|125] "%" Vector__XXX
 SG_ EngCyl18IgntTransSecondOutput : 8|8@1+ (1,-125) [-125|125] "%" Vector__XXX
 SG_ EngCyl17IgntTransSecondOutput : 0|8@1+ (1,-125) [-125|125] "%" Vector__XXX

BO_ 2633927166 ISO2: 8 Vector__XXX
 SG_ EngCyl16IgntTransSecondOutput : 56|8@1+ (1,-125) [-125|125] "%" Vector__XXX
 SG_ EngCyl15IgntTransSecondOutput : 48|8@1+ (1,-125) [-125|125] "%" Vector__XXX
 SG_ EngCyl14IgntTransSecondOutput : 40|8@1+ (1,-125) [-125|125] "%" Vector__XXX
 SG_ EngCyl13IgntTransSecondOutput : 32|8@1+ (1,-125) [-125|125] "%" Vector__XXX
 SG_ EngCyl12IgntTransSecondOutput : 24|8@1+ (1,-125) [-125|125] "%" Vector__XXX
 SG_ EngCyl11IgntTransSecondOutput : 16|8@1+ (1,-125) [-125|125] "%" Vector__XXX
 SG_ EngCyl10IgntTransSecondOutput : 8|8@1+ (1,-125) [-125|125] "%" Vector__XXX
 SG_ EngCyl9IgntTransSecondOutput : 0|8@1+ (1,-125) [-125|125] "%" Vector__XXX

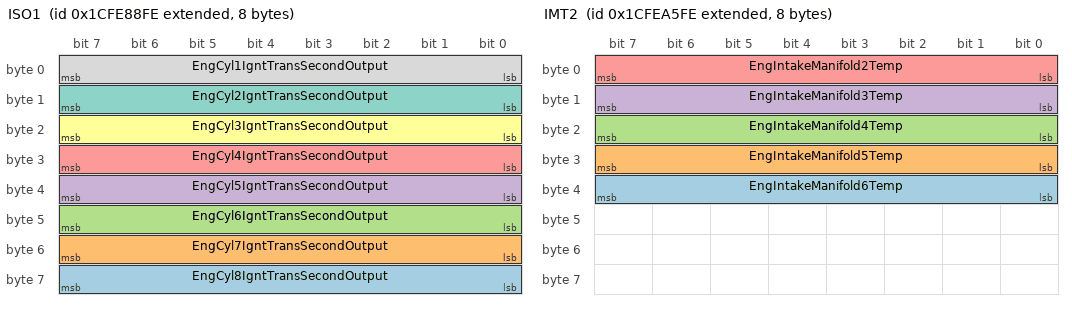
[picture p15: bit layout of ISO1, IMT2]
BO_ 2633926910 ISO1: 8 Vector__XXX
 SG_ EngCyl8IgntTransSecondOutput : 56|8@1+ (1,-125) [-125|125] "%" Vector__XXX
 SG_ EngCyl7IgntTransSecondOutput : 48|8@1+ (1,-125) [-125|125] "%" Vector__XXX
 SG_ EngCyl6IgntTransSecondOutput : 40|8@1+ (1,-125) [-125|125] "%" Vector__XXX
 SG_ EngCyl5IgntTransSecondOutput : 32|8@1+ (1,-125) [-125|125] "%" Vector__XXX
 SG_ EngCyl4IgntTransSecondOutput : 24|8@1+ (1,-125) [-125|125] "%" Vector__XXX
 SG_ EngCyl3IgntTransSecondOutput : 16|8@1+ (1,-125) [-125|125] "%" Vector__XXX
 SG_ EngCyl2IgntTransSecondOutput : 8|8@1+ (1,-125) [-125|125] "%" Vector__XXX
 SG_ EngCyl1IgntTransSecondOutput : 0|8@1+ (1,-125) [-125|125] "%" Vector__XXX

BO_ 2566768894 ISCS: 8 Vector__XXX
 SG_ EngOprtrPrmryIntrmdtSpdSlctStte : 0|4@1+ (1,0) [0|15] "" Vector__XXX

BO_ 2566769406 ISC: 8 Vector__XXX
 SG_ EngOprtrPrmryIntrmdtSpeedSelect : 0|4@1+ (1,0) [0|15] "" Vector__XXX

BO_ 2566839550 IO: 8 Vector__XXX
 SG_ EngTotalIdleHours : 32|32@1+ (0.05,0) [0|210554060.75] "hr" Vector__XXX
 SG_ EngTotalIdleFuelUsed : 0|32@1+ (0.5,0) [0|2105540607.5] "L" Vector__XXX

BO_ 2633934334 IMT2: 8 Vector__XXX
 SG_ EngIntakeManifold6Temp : 32|8@1+ (1,-40) [-40|210] "deg C" Vector__XXX
 SG_ EngIntakeManifold5Temp : 24|8@1+ (1,-40) [-40|210] "deg C" Vector__XXX
 SG_ EngIntakeManifold4Temp : 16|8@1+ (1,-40) [-40|210] "deg C" Vector__XXX
 SG_ EngIntakeManifold3Temp : 8|8@1+ (1,-40) [-40|210] "deg C" Vector__XXX
 SG_ EngIntakeManifold2Temp : 0|8@1+ (1,-40) [-40|210] "deg C" Vector__XXX

BO_ 2566825726 IMT1: 8 Vector__XXX
 SG_ EngTurbo4BoostPress : 48|16@1+ (0.125,0) [0|8031.875] "kPa" Vector__XXX
 SG_ EngTurbo3BoostPress : 32|16@1+ (0.125,0) [0|8031.875] "kPa" Vector__XXX
 SG_ EngTurbo2BoostPress : 16|16@1+ (0.125,0) [0|8031.875] "kPa" Vector__XXX
 SG_ EngTurbo1BoostPress : 0|16@1+ (0.125,0) [0|8031.875] "kPa" Vector__XXX

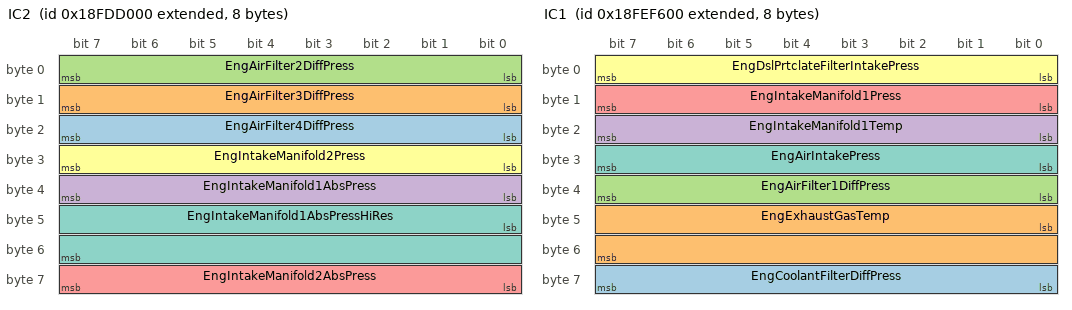
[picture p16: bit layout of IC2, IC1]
BO_ 2566770688 IC2: 8 Vector__XXX
 SG_ EngAirFilter4DiffPress : 16|8@1+ (0.05,0) [0|12.5] "kPa" Vector__XXX
 SG_ EngAirFilter3DiffPress : 8|8@1+ (0.05,0) [0|12.5] "kPa" Vector__XXX
 SG_ EngAirFilter2DiffPress : 0|8@1+ (0.05,0) [0|12.5] "kPa" Vector__XXX
 SG_ EngIntakeManifold1AbsPress : 32|8@1+ (0.1,0) [0|25.5] "kPa" Vector__XXX
 SG_ EngIntakeManifold2AbsPress : 56|8@1+ (2,0) [0|500] "kPa" Vector__XXX
 SG_ EngIntakeManifold2Press : 24|8@1+ (2,0) [0|500] "kPa" Vector__XXX
 SG_ EngIntakeManifold1AbsPressHiRes : 40|16@1+ (0.1,0) [0|6425.5] "kPa" Vector__XXX

BO_ 2566845952 IC1: 8 Vector__XXX
 SG_ EngCoolantFilterDiffPress : 56|8@1+ (0.5,0) [0|125] "kPa" Vector__XXX
 SG_ EngExhaustGasTemp : 40|16@1+ (0.03125,-273) [-273|1734.96875] "deg C" Vector__XXX
 SG_ EngAirFilter1DiffPress : 32|8@1+ (0.05,0) [0|12.5] "kPa" Vector__XXX
 SG_ EngIntakeManifold1Temp : 16|8@1+ (1,-40) [-40|210] "deg C" Vector__XXX
 SG_ EngIntakeManifold1Press : 8|8@1+ (2,0) [0|500] "kPa" Vector__XXX
 SG_ EngDslPrtclateFilterIntakePress : 0|8@1+ (0.5,0) [0|125] "kPa" Vector__XXX
 SG_ EngAirIntakePress : 24|8@1+ (2,0) [0|500] "kPa" Vector__XXX

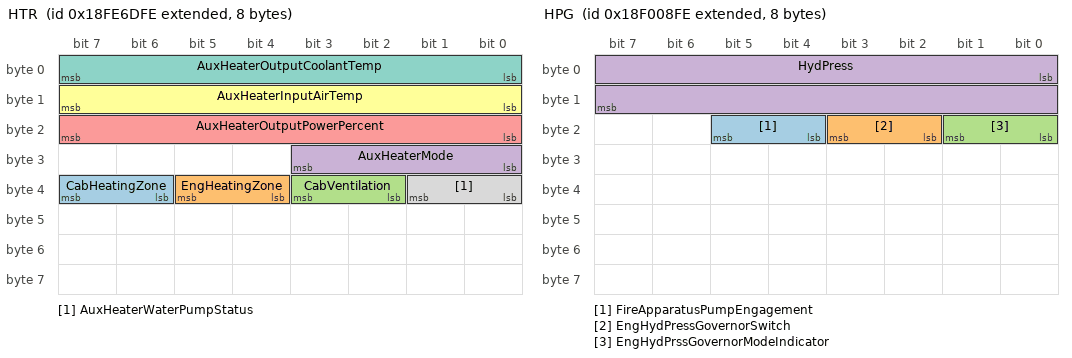
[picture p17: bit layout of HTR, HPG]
BO_ 2566811134 HTR: 8 Vector__XXX
 SG_ CabHeatingZone : 38|2@1+ (1,0) [0|3] "" Vector__XXX
 SG_ EngHeatingZone : 36|2@1+ (1,0) [0|3] "" Vector__XXX
 SG_ CabVentilation : 34|2@1+ (1,0) [0|3] "" Vector__XXX
 SG_ AuxHeaterMode : 24|4@1+ (1,0) [0|15] "" Vector__XXX
 SG_ AuxHeaterOutputPowerPercent : 16|8@1+ (0.4,0) [0|100] "%" Vector__XXX
 SG_ AuxHeaterInputAirTemp : 8|8@1+ (1,-40) [-40|210] "deg C" Vector__XXX
 SG_ AuxHeaterOutputCoolantTemp : 0|8@1+ (1,-40) [-40|210] "deg C" Vector__XXX
 SG_ AuxHeaterWaterPumpStatus : 32|2@1+ (1,0) [0|3] "" Vector__XXX

BO_ 2298375934 HRW: 8 Vector__XXX
 SG_ RearAxleRightWheelSpeed : 48|16@1+ (0.00390625,0) [0|250.996] "km/h" Vector__XXX
 SG_ RearAxleLeftWheelSpeed : 32|16@1+ (0.00390625,0) [0|250.996] "km/h" Vector__XXX
 SG_ FrontAxleRightWheelSpeed : 16|16@1+ (0.00390625,0) [0|250.996] "km/h" Vector__XXX
 SG_ FrontAxleLeftWheelSpeed : 0|16@1+ (0.00390625,0) [0|250.996] "km/h" Vector__XXX

BO_ 2565867774 HPG: 8 Vector__XXX
 SG_ FireApparatusPumpEngagement : 20|2@1+ (1,0) [0|3] "" Vector__XXX
 SG_ EngHydPressGovernorSwitch : 18|2@1+ (1,0) [0|3] "" Vector__XXX
 SG_ EngHydPrssGovernorModeIndicator : 16|2@1+ (1,0) [0|3] "" Vector__XXX
 SG_ HydPress : 0|16@1+ (2,0) [0|128510] "kPa" Vector__XXX

BO_ 2566841854 HOURS: 8 Vector__XXX
 SG_ EngTotalRevolutions : 32|32@1+ (1000,0) [0|2013264920] "r" Vector__XXX
 SG_ EngTotalHoursOfOperation : 0|32@1+ (0.05,0) [0|210554060.75] "hr" Vector__XXX

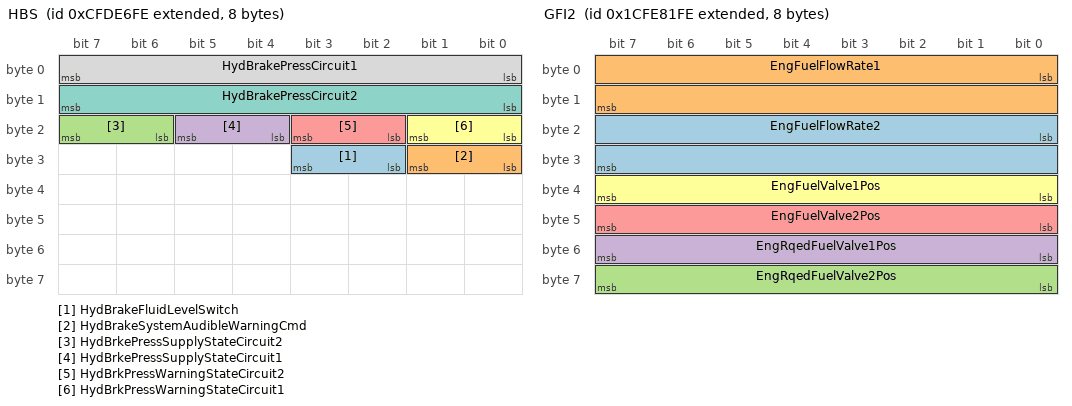
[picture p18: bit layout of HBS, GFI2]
BO_ 2365449982 HBS: 8 Vector__XXX
 SG_ HydBrakeFluidLevelSwitch : 26|2@1+ (1,0) [0|3] "" Vector__XXX
 SG_ HydBrakeSystemAudibleWarningCmd : 24|2@1+ (1,0) [0|3] "" Vector__XXX
 SG_ HydBrkePressSupplyStateCircuit2 : 22|2@1+ (1,0) [0|3] "" Vector__XXX
 SG_ HydBrkePressSupplyStateCircuit1 : 20|2@1+ (1,0) [0|3] "" Vector__XXX
 SG_ HydBrkPressWarningStateCircuit2 : 18|2@1+ (1,0) [0|3] "" Vector__XXX
 SG_ HydBrkPressWarningStateCircuit1 : 16|2@1+ (1,0) [0|3] "" Vector__XXX
 SG_ HydBrakePressCircuit2 : 8|8@1+ (100,0) [0|25] "MPa" Vector__XXX
 SG_ HydBrakePressCircuit1 : 0|8@1+ (100,0) [0|25] "MPa" Vector__XXX

BO_ 2633939198 GTFI: 22 Vector__XXX
 SG_ TripDriveFuelEconomy : 160|16@1+ (0.001953125,0) [0|125.5] "km/kg" Vector__XXX
 SG_ TrpPTOGovernorNonmovingFuelUsed : 64|32@1+ (0.5,0) [0|2105540607.5] "kg" Vector__XXX
 SG_ TripVehicleIdleFuelUsed : 96|32@1+ (0.5,0) [0|2105540607.5] "kg" Vector__XXX
 SG_ TripCruiseFuelUsed : 128|32@1+ (0.5,0) [0|2105540607.5] "kg" Vector__XXX
 SG_ TripDriveFuelUsed : 0|32@1+ (0.5,0) [0|2105540607.5] "kg" Vector__XXX
 SG_ TripPTOGovernorMovingFuelUsed : 32|32@1+ (0.5,0) [0|2105540607.5] "kg" Vector__XXX

BO_ 2633927678 GFP: 8 Vector__XXX
 SG_ EngFuelValve1OutletAbsPress : 48|16@1+ (0.1,0) [0|6425.5] "kPa" Vector__XXX
 SG_ EngAirToFuelDiffPress : 32|16@1+ (0.1,0) [0|6425.5] "kPa" Vector__XXX
 SG_ EngFuelValveDiffPress : 16|16@1+ (0.1,0) [0|6425.5] "kPa" Vector__XXX
 SG_ EngFuelValve1IntakeAbsPress : 0|16@1+ (0.1,0) [0|6425.5] "kPa" Vector__XXX

BO_ 2633925118 GFI2: 8 Vector__XXX
 SG_ EngFuelFlowRate2 : 16|16@1+ (0.1,0) [0|6425.5] "m³/h" Vector__XXX
 SG_ EngFuelFlowRate1 : 0|16@1+ (0.1,0) [0|6425.5] "m³/h" Vector__XXX
 SG_ EngRqedFuelValve2Pos : 56|8@1+ (0.4,0) [0|100] "%" Vector__XXX
 SG_ EngRqedFuelValve1Pos : 48|8@1+ (0.4,0) [0|100] "%" Vector__XXX
 SG_ EngFuelValve2Pos : 40|8@1+ (0.4,0) [0|100] "%" Vector__XXX
 SG_ EngFuelValve1Pos : 32|8@1+ (0.4,0) [0|100] "%" Vector__XXX

BO_ 2633937662 GFI1: 8 Vector__XXX
 SG_ TotalEngPTOGovernorFuelUsed : 0|32@1+ (0.5,0) [0|2105540607.5] "kg" Vector__XXX
 SG_ TripAverageFuelRate : 32|16@1+ (0.05,0) [0|3212.75] "kg/h" Vector__XXX
 SG_ EngFuelSpecificGravity : 48|16@1+ (0.0001,0) [0|6.4255] "" Vector__XXX

BO_ 2566804990 GFD: 8 Vector__XXX
 SG_ SpecificHeatRatio : 0|16@1+ (0.001,0) [0|64.255] "" Vector__XXX

BO_ 2633936894 GFC: 8 Vector__XXX
 SG_ TotalFuelUsed : 32|32@1+ (0.5,0) [0|2105540607.5] "kg" Vector__XXX
 SG_ TripFuel : 0|32@1+ (0.5,0) [0|2105540607.5] "kg" Vector__XXX

BO_ 2566757630 SEP2: 8 Vector__XXX
 SG_ SensorSupplyVoltage6 : 16|16@1+ (0.05,0) [0|3212.75] "V" Vector__XXX
 SG_ SensorSupplyVoltage5 : 0|16@1+ (0.05,0) [0|3212.75] "V" Vector__XXX
 SG_ SensorSupplyVoltage8 : 48|16@1+ (0.05,0) [0|3212.75] "V" Vector__XXX
 SG_ SensorSupplyVoltage7 : 32|16@1+ (0.05,0) [0|3212.75] "V" Vector__XXX

BO_ 2566757886 SEP1: 8 Vector__XXX
 SG_ SensorSupplyVoltage4 : 48|16@1+ (0.05,0) [0|3212.75] "V" Vector__XXX
 SG_ SensorSupplyVoltage3 : 32|16@1+ (0.05,0) [0|3212.75] "V" Vector__XXX
 SG_ SensorSupplyVoltage2 : 16|16@1+ (0.05,0) [0|3212.75] "V" Vector__XXX
 SG_ SensorSupplyVoltage1 : 0|16@1+ (0.05,0) [0|3212.75] "V" Vector__XXX

BO_ 2566759678 PTODE: 8 Vector__XXX
 SG_ EnggmntSttusTransInputShaftPTO1 : 38|2@1+ (1,0) [0|3] "" Vector__XXX
 SG_ EnggmntSttusTransInputShaftPTO2 : 36|2@1+ (1,0) [0|3] "" Vector__XXX
 SG_ EnggmntSttusTransOutputShaftPTO : 34|2@1+ (1,0) [0|3] "" Vector__XXX
 SG_ EnggmntSttsTrnsfrCsOtptShaftPTO : 32|2@1+ (1,0) [0|3] "" Vector__XXX
 SG_ EnggmntCnsntTransInputShaftPTO1 : 22|2@1+ (1,0) [0|3] "" Vector__XXX
 SG_ EnggmntCnsntTransInputShaftPTO2 : 20|2@1+ (1,0) [0|3] "" Vector__XXX
 SG_ EnggmntCnsntTransOutputShaftPTO : 18|2@1+ (1,0) [0|3] "" Vector__XXX
 SG_ EnggmntCnsntTrnsfrCsOtptShftPTO : 16|2@1+ (1,0) [0|3] "" Vector__XXX
 SG_ EnableSwitchTransInputShaftPTO1 : 6|2@1+ (1,0) [0|3] "" Vector__XXX
 SG_ EnableSwitchTransInputShaftPTO2 : 4|2@1+ (1,0) [0|3] "" Vector__XXX
 SG_ EnableSwitchTransOutputShaftPTO : 2|2@1+ (1,0) [0|3] "" Vector__XXX
 SG_ EnblSwtchTrnsfrCsOutputShaftPTO : 0|2@1+ (1,0) [0|3] "" Vector__XXX
 SG_ EnggmntSttsPTOEngAccssoryDrive2 : 44|2@1+ (1,0) [0|3] "" Vector__XXX
 SG_ EnggmntSttsPTOEngAccssoryDrive1 : 42|2@1+ (1,0) [0|3] "" Vector__XXX
 SG_ EnggmntCnsntPTOEngAccssryDrive2 : 28|2@1+ (1,0) [0|3] "" Vector__XXX
 SG_ EnggmntCnsntPTOEngAccssryDrive1 : 26|2@1+ (1,0) [0|3] "" Vector__XXX
 SG_ EngagementStatusPTOEngFlywheel : 40|2@1+ (1,0) [0|3] "" Vector__XXX
 SG_ EngagementConsentPTOEngFlywheel : 24|2@1+ (1,0) [0|3] "" Vector__XXX
 SG_ EnblSwitchPTOEngAccessoryDrive2 : 12|2@1+ (1,0) [0|3] "" Vector__XXX
 SG_ EnblSwitchPTOEngAccessoryDrive1 : 10|2@1+ (1,0) [0|3] "" Vector__XXX
 SG_ EnableSwitchPTOEngFlywheel : 8|2@1+ (1,0) [0|3] "" Vector__XXX
 SG_ AtLeastOnePTOEngaged : 48|2@1+ (1,0) [0|3] "" Vector__XXX

BO_ 2432541438 GFI3: 8 Vector__XXX
 SG_ EngFuelValve2OutletAbsPress : 48|16@1+ (0.1,0) [0|6425.5] "kPa" Vector__XXX
 SG_ EngFuelTemp2 : 32|8@1+ (1,-40) [-40|210] "deg C" Vector__XXX
 SG_ EngGas2MassFlowRate : 16|16@1+ (0.05,0) [0|3212.75] "kg/h" Vector__XXX
 SG_ EngFuelValve2IntakeAbsPress : 0|16@1+ (0.1,0) [0|6425.5] "kPa" Vector__XXX

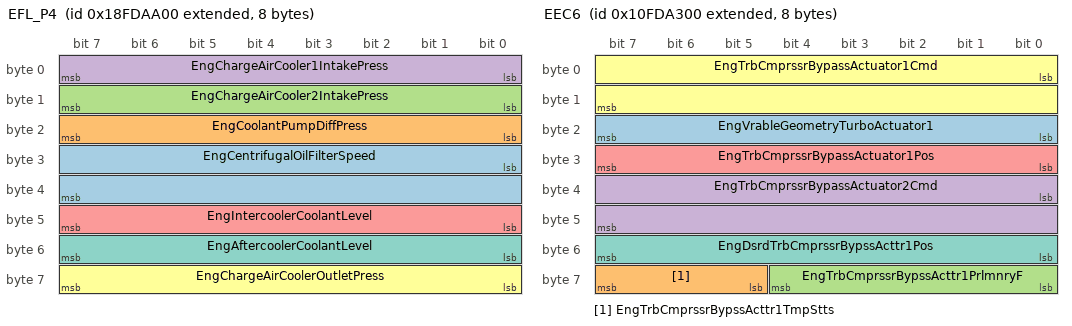
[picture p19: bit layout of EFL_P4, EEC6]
BO_ 2566760960 EFL_P4: 8 Vector__XXX
 SG_ EngCentrifugalOilFilterSpeed : 24|16@1+ (4,0) [0|257020] "rpm" Vector__XXX
 SG_ EngCoolantPumpDiffPress : 16|8@1+ (1.64,-7) [-7|403] "kPa" Vector__XXX
 SG_ EngChargeAirCooler2IntakePress : 8|8@1+ (2,0) [0|500] "kPa" Vector__XXX
 SG_ EngChargeAirCooler1IntakePress : 0|8@1+ (2,0) [0|500] "kPa" Vector__XXX
 SG_ EngIntercoolerCoolantLevel : 40|8@1+ (0.4,0) [0|100] "%" Vector__XXX
 SG_ EngChargeAirCoolerOutletPress : 56|8@1+ (2,0) [0|500] "kPa" Vector__XXX
 SG_ EngAftercoolerCoolantLevel : 48|8@1+ (0.4,0) [0|100] "%" Vector__XXX

BO_ 2432541440 EEC6: 8 Vector__XXX
 SG_ EngVrableGeometryTurboActuator1 : 16|8@1+ (0.4,0) [0|100] "%" Vector__XXX
 SG_ EngTrbCmprssrBypssActtr1TmpStts : 61|3@1+ (1,0) [0|7] "" Vector__XXX
 SG_ EngTrbCmprssrBypssActtr1PrlmnryF : 56|5@1+ (1,0) [0|31] "" Vector__XXX
 SG_ EngTrbCmprssrBypassActuator2Cmd : 32|16@1+ (0.0025,0) [0|160.6375] "%" Vector__XXX
 SG_ EngTrbCmprssrBypassActuator1Pos : 24|8@1+ (0.4,0) [0|100] "%" Vector__XXX
 SG_ EngTrbCmprssrBypassActuator1Cmd : 0|16@1+ (0.0025,0) [0|160.6375] "%" Vector__XXX
 SG_ EngDsrdTrbCmprssrBypssActtr1Pos : 48|8@1+ (0.4,0) [0|100] "%" Vector__XXX

CM_ BO_ 2432498944 "Electronic Engine Controller 9";
CM_ SG_ 2432498944 CmdedEngFuelInjectionCtrlPress "Provides the commanded set point value for the engine fuel injection control pressure.";
CM_ SG_ 2432498944 CmdedEngFuelRailPress "Provides the commanded set point value for the engine fuel rail pressure";
CM_ SG_ 2432498944 EngExhstGsRcrculation2Valve2Pos "The position of the second exhaust gas recirculation valve of EGR 2 expressed as a percentage of full travel.";
CM_ SG_ 2432498944 EngExhstGsRcirculation2ValvePos "Position of EGR2 valve expressed as a percentage of full travel.";
CM_ BO_ 2633825022 "Electronic Engine Controller 11";
CM_ SG_ 2633825022 EngExhstGsRcrclation2Valve2Ctrl "Desired percentage of maximum Exhaust Gas Recirculation 2 (EGR2) valve 2 opening.";
CM_ SG_ 2633825022 EngExhstGsRcrculation2ValveCtrl "Desired percentage of maximum Exhaust Gas Recirculation 2 (EGR2) valve opening.";
CM_ BO_ 2633826046 "Electronic Engine Controller 10";
CM_ SG_ 2633826046 EGR2CoolerBypassActuatorPos "EGR2 Cooler Bypass Actuator position, where 0% = Fully Closed (no gas flowing through the bypass), and 100% = Fully";
CM_ SG_ 2633826046 EngExhstGsRcrcltn2ClrEfficiency "Exhaust Gas Recirculation 2 cooler efficiency is an indication of the cooler’s ability to reduce the temperature of the";
CM_ SG_ 2633826046 EngExhstGsRcrcltn2ClrIntkGsAbsPr "Exhaust Gas Recirculation 2 gas absolute pressure is measured at EGR2 cooler intake.";
CM_ SG_ 2633826046 EngExhstGsRcrcltn2ClrIntakeTemp "Exhaust Gas Recirculation 2 (EGR2) Temperature measured at EGR2 cooler intake.";
CM_ BO_ 2566711040 "Engine Configuration 3";
CM_ SG_ 2566711040 EngFrctnPrcntTorqueAtIdlePoint7 "The static portion of the friction torque at speed point 7 (SPN 533) of the engine torque map in the engine configuration";
CM_ SG_ 2566711040 EngFrctnPrcntTorqueAtIdlePoint6 "For engine configuration map modes 1 and 2, this is the static portion of the friction torque at speed point 6 (SPN 532) of";
CM_ SG_ 2566711040 EngFrctnPrcntTorqueAtIdlePoint5 "The static portion of the friction torque at speed point 5 (SPN 531) of the engine torque map in the engine configuration";
CM_ SG_ 2566711040 EngFrctnPrcntTorqueAtIdlePoint4 "The static portion of the friction torque at speed point 4 (SPN 530) of the engine torque map in the engine configuration";
CM_ SG_ 2566711040 EngFrctnPrcntTorqueAtIdlePoint3 "The static portion of the friction torque at speed point 3 (SPN 529) of the engine torque map in the engine configuration";
CM_ SG_ 2566711040 EngFrctnPrcntTorqueAtIdlePoint2 "The static portion of the friction torque at speed point 2 (SPN 528) of the engine torque map in the engine configuration";
CM_ SG_ 2566711040 EngFrctnPrcntTorqueAtIdlePoint1 "The static portion of the friction torque at speed point 1 (SPN 188) of the engine torque map in the engine configuration";
CM_ BO_ 2566749184 "Diesel Particulate Filter Control 1";
CM_ SG_ 2566749184 DslPrtcltFltrActvRgnrtnFrcdStts "Indicates the forced execution status of diesel particulate filter regeneration.";
CM_ SG_ 2566749184 ExhaustSystemHighTempLampCmd "Command to control the exhaust system high temperature lamp.";
CM_ SG_ 2566749184 DslPrtcltFltrAtmtcActvRgnrtnIntt "Indicates the configuration of diesel particulate filter active regeneration automatic initiation.";
CM_ SG_ 2566749184 DslPrtcltFltrActvRgnrtnInhbtdDTV "Speed";
CM_ SG_ 2566749184 DslPrtcltFltrActvRgnrtnInhbtdDTE "Indicates the state of diesel particulate filter active regeneration inhibition due to the engine not being warmed up.";
CM_ SG_ 2566749184 DslPrtcltFltrActvRgnrtnInhbtdDTP "Indicates the state of diesel particulate filter active regeneration inhibition due to a permanent system lockout.";
CM_ SG_ 2566749184 DslPrtcltFltrActvRgnrtnInhbtdDTT "Indicates the state of diesel particulate filter active regeneration inhibition due to a temporary system lockout.";
CM_ SG_ 2566749184 DslPrtcltFltrActvRgnrtnInhbtdDTS "Indicates the state of diesel particulate filter active regeneration inhibition due to a system timeout.";
CM_ SG_ 2566749184 DslPrtcltFltrActvRgnrtnInhb_0000 "Indicates the state of diesel particulate filter active regeneration inhibition due to a system fault being active.";
CM_ SG_ 2566749184 DslPrtcltFltrActvRgnrtnInhbtdDTL "Indicates the state of diesel particulate filter active regeneration inhibition due to the exhaust gas temperature being too";
CM_ SG_ 2566749184 DslPrtcltFltrActvRgnrtnInhb_0001 "Indicates the state of diesel particulate filter active regeneration inhibition due to the parking brake being not set.";
CM_ SG_ 2566749184 DslPrtcltFltrActvRgnrtnInhb_0002 "Speed";
CM_ SG_ 2566749184 DslPrtcltFltrActvRgnrtnInhbtdDTO "Indicates the state of diesel particulate filter active regeneration inhibition due to the transmission being out of neutral.";
CM_ SG_ 2566749184 DslPrtcltFltrActvRgnrtnInhbtdDTA "Indicates the state of diesel particulate filter active regeneration inhibition due to the accelerator pedal being off idle.";
CM_ SG_ 2566749184 DslPrtcltFltrActvRgnrtnInhb_0003 "Indicates the state of diesel particulate filter active regeneration inhibition due to the PTO being active.";
CM_ SG_ 2566749184 DslPrtcltFltrActvRgnrtnInhb_0004 "Indicates the state of diesel particulate filter active regeneration inhibition due to the service brake being active.";
CM_ SG_ 2566749184 DslPrtcltFltrActvRgnrtnInhbtdDTC "Indicates the state of diesel particulate filter active regeneration inhibition due to the clutch being disengaged.";
CM_ SG_ 2566749184 DslPrtcltFltrActvRgnrtnInhbtdDTI "Indicates the state of diesel particulate filter active regeneration inhibition due to the Diesel Particulate Filter Regeneration";
CM_ SG_ 2566749184 DslPrtcltFltrActvRgnrtnInhbtdStt "Indicates the state of diesel particulate filter active regeneration inhibition.";
CM_ SG_ 2566749184 DieselParticulateFilterStatus "Indicates the state of the diesel particulate filter regeneration need and urgency.";
CM_ SG_ 2566749184 DslPrtcltFltrActvRgnrtionStatus "Indicates the state of diesel particulate filter active regeneration.";
CM_ SG_ 2566749184 DslPrtcltFltrPssvRgnrtionStatus "Indicates the state of diesel particulate filter passive regeneration.";
CM_ SG_ 2566749184 DieselParticulateFilterLampCmd "Command to control the diesel particulate filter lamp.";
CM_ BO_ 2566715646 "Diesel Particulate Filter 2 Soot 2";
CM_ SG_ 2566715646 DslPrtclateFilter2SootSignalMin "Minimum output signal level of the current soot measurement from diesel particulate filter 2 soot sensor.";
CM_ SG_ 2566715646 DslPrtclateFilter2SootSignalMax "Maximum output signal level of the current soot measurement from diesel particulate filter 2 soot sensor.";
CM_ SG_ 2566715646 DslPrtcltFltr2StSgnlStndrdDvton "Standard deviation of the soot measurement from diesel particulate filter 2 soot sensor.";
CM_ BO_ 2566724606 "Diesel Particulate Filter 2 Soot";
CM_ SG_ 2566724606 DslPrtcltFltr2StSnsrPrlmnaryFMI "Used to identify the applicable J1939-73 FMI detected in the soot sensor signal by the manufacturer’s sensor control";
CM_ SG_ 2566724606 DslPrtcltFlter2MedianSootSignal "Median output signal level from diesel particulate filter 2 soot sensor.";
CM_ SG_ 2566724606 DslPrtclteFilter2MeanSootSignal "Mean output signal level from diesel particulate filter 2 soot sensor.";
CM_ SG_ 2566724606 DslPrticulateFilter2SootDensity "Soot density in diesel particulate filter 2.";
CM_ SG_ 2566724606 DeselParticulateFilter2SootMass "Soot mass in diesel particulate filter 2.";
CM_ BO_ 2566715902 "Diesel Particulate Filter 1 Soot 2";
CM_ SG_ 2566715902 DslPrtclateFilter1SootSignalMin "Minimum output signal level of the current soot measurement from diesel particulate filter 1 soot sensor.";
CM_ SG_ 2566715902 DslPrtclateFilter1SootSignalMax "Maximum output signal level of the current soot measurement from diesel particulate filter 1 soot sensor.";
CM_ SG_ 2566715902 DslPrtcltFltr1StSgnlStndrdDvton "Standard deviation of the soot measurement from diesel particulate filter 1 soot sensor.";
CM_ BO_ 2566724862 "Diesel Particulate Filter 1 Soot";
CM_ SG_ 2566724862 DslPrtcltFltr1StSnsrPrlmnaryFMI "Used to identify the applicable J1939-73 FMI detected in the soot sensor signal by the manufacturer’s sensor control";
CM_ SG_ 2566724862 DslPrtcltFlter1MedianSootSignal "Median output signal level from diesel particulate filter 1 soot sensor.";
CM_ SG_ 2566724862 DslPrtclteFilter1MeanSootSignal "Mean output signal level from diesel particulate filter 1 soot sensor.";
CM_ SG_ 2566724862 DslPrticulateFilter1SootDensity "Soot density in diesel particulate filter 1.";
CM_ SG_ 2566724862 DeselParticulateFilter1SootMass "Soot mass in diesel particulate filter 1.";
CM_ BO_ 2566718464 "Direct Lamp Control Data 2";
CM_ SG_ 2566718464 VehicleBatteryChargingLampData "This parameter provides measured data from the Vehicle Battery Charging Lamp.";
CM_ SG_ 2566718464 VhicleHVACRecirculationLampData "This parameter provides measured data from the Vehicle HVAC Recirculation Lamp.";
CM_ SG_ 2566718464 VehicleAirPressLowLampData "This parameter provides measured data from the Vehicle Air Pressure Low Lamp.";
CM_ SG_ 2566718464 VehicleFuelLevelLowLampData "This parameter provides measured data from theVehicle Fuel Level Low Lamp.";
CM_ SG_ 2566718464 VhicleBatteryVoltageLowLampData "This parameter provides measured data from the Vehicle Battery Voltage Low Lamp.";
CM_ BO_ 2566718720 "Direct Lamp Control Data 1";
CM_ SG_ 2566718720 EngWaitToStartLampData "This parameter provides measured data from the Engine Wait To Start Lamp.";
CM_ SG_ 2566718720 EngFuelFilterRestrictedLampData "Command signal directly controlling the Vehicle Fuel Filter Restricted Lamp.";
CM_ SG_ 2566718720 EngAirFilterRestrictionLampData "This parameter provides measured data from the Engine Air Filter Restriction Lamp.";
CM_ SG_ 2566718720 EngIdleManagementActiveLampData "This parameter provides measured data from the Engine Idle Management Active Lamp.";
CM_ SG_ 2566718720 EngCoolantLevelLowLampData "This parameter provides measured data from the Engine Coolant Level Low Lamp.";
CM_ SG_ 2566718720 EngCoolantTempHighLampData "This parameter provides measured data from the Engine Coolant Temperature High Lamp.";
CM_ SG_ 2566718720 EngOilPressLowLampData "This parameter provides measured data from the Engine Oil Pressure Low Lamp.";
CM_ SG_ 2566718720 CmprssnBrkEnblSwtchIndctrLmpDta "This parameter provides measured data from the Compression Brake Enable Switch Indicator Lamp.";
CM_ SG_ 2566718720 EngBrakeActiveLampData "This parameter provides measured data from the Engine Brake Active Lamp.";
CM_ SG_ 2566718720 OBDMalfunctionIndicatorLampData "This parameter provides measured data from the OBD Malfunction Indicator Lamp.";
CM_ SG_ 2566718720 EngRedStopLampData "This parameter provides measured data from the Engine Red Stop Lamp.";
CM_ SG_ 2566718720 EngAmberWarningLampData "This parameter provides measured data from the Engine Amber Warning Lamp.";
CM_ SG_ 2566718720 EngProtectLampData "This parameter provides measured data from the Engine Protect Lamp.";
CM_ BO_ 2566718976 "Direct Lamp Control Command 2";
CM_ SG_ 2566718976 VehicleBatteryChargingLampCmd "Command signal directly controlling the Vehicle Battery Charging Lamp.";
CM_ SG_ 2566718976 VehicleHVACRecirculationLampCmd "Command signal directly controlling the Vehicle HVAC Recirculation Lamp.";
CM_ SG_ 2566718976 VehicleAirPressLowLampCmd "Command signal directly controlling the Vehicle Air Pressure Low Lamp.";
CM_ SG_ 2566718976 VehicleFuelLevelLowLampCmd "Command signal directly controlling the Vehicle Fuel Level Low Lamp.";
CM_ SG_ 2566718976 VehicleBatteryVoltageLowLampCmd "Command signal directly controlling the Vehicle Battery Voltage Low Lamp.";
CM_ BO_ 2560818942 "DM32 provides the DTCs and associated timers";
CM_ SG_ 2560818942 DTCTimeUntilDerate "This timer provides the number of hours the malfunction has until the OBD required derate will occur";
CM_ SG_ 2560818942 DTCTotalPreviouslyActiveTime "This timer provides the number of hours the NOx malfunction has been confirmed and previously active";
CM_ SG_ 2560818942 DTCTotalActiveTime "This timer provides the total number of hours the DTC has been confirmed and active";
CM_ SG_ 2560818942 FailureModeIdentifier1 "The FMI defines the type of failure detected in the subsystem identified by an SPN.";
CM_ SG_ 2560818942 SPN1High "SPN #1 (Conversion Version 4)";
CM_ SG_ 2560818942 SPN1 "SPN #1 (Conversion Version 4)";
CM_ BO_ 2561212158 "Text Display";
CM_ SG_ 2561212158 TextDisplayInstructions "This parameter describes the status for the display how to show the information.";
CM_ BO_ 2566746366 "Door ramp control";
CM_ SG_ 2566746366 RetractStatusOfRamp5 "Retract status of ramp at doorway 5, counting from front to back on the vehicle.";
CM_ SG_ 2566746366 RetractStatusOfRamp4 "Retract status of ramp at doorway 4, counting from front to back on the vehicle.";
CM_ SG_ 2566746366 MovementStatusOfRamp5 "Movement status of ramp at doorway 5, counting from front to back on the vehicle.";
CM_ SG_ 2566746366 MovementStatusOfRamp4 "Movement status of ramp at doorway 4, counting from front to back on the vehicle.";
CM_ SG_ 2566746366 EnableStatusOfRamp5 "Enable status of ramp at doorway 5, counting from front to back on the vehicle.";
CM_ SG_ 2566746366 EnableStatusOfRamp4 "Enable status of ramp at doorway 4, counting from front to back on the vehicle.";
CM_ SG_ 2566746366 MovementStatusOfRamp3 "Movement status of ramp at doorway 3, counting from front to back on the vehicle.";
CM_ SG_ 2566746366 EnableStatusOfRamp3 "Enable status of ramp at doorway 3, counting from front to back on the vehicle.";
CM_ SG_ 2566746366 RetractStatusOfRamp3 "Retract status of ramp at doorway 3, counting from front to back on the vehicle.";
CM_ SG_ 2566746366 MovementStatusOfRamp2 "Movement status of ramp at doorway 2, counting from front to back on the vehicle.";
CM_ SG_ 2566746366 EnableStatusOfRamp2 "Enable status of ramp at doorway 2, counting from front to back on the vehicle.";
CM_ SG_ 2566746366 RetractStatusOfRamp2 "Retract status of ramp at doorway 2, counting from front to back on the vehicle.";
CM_ SG_ 2566746366 MovementStatusOfRamp1 "Movement status of ramp at doorway 1, counting from front to back on the vehicle.";
CM_ SG_ 2566746366 EnableStatusOfRamp1 "Enable status of ramp at doorway 1, counting from front to back on the vehicle.";
CM_ SG_ 2566746366 RetractStatusOfRamp1 "Retract status of ramp at doorway 1, counting from front to back on the vehicle.";
CM_ BO_ 2566749952 "Engine Configuration 2";
CM_ SG_ 2566749952 MaxCrankAttemptsPerStartAttempt "The number of cranking cycles that will be performed before ending the start attempt.";
CM_ BO_ 2566755328 "Electronic Engine Controller 7";
CM_ SG_ 2566755328 EngExhstGsRcrculation1Valve2Pos "The position of the second exhaust gas recirculation valve expressed as a percentage of full travel.";
CM_ SG_ 2566755328 EngExhstGsRcirculation1ValvePos "The position of the exhaust gas recirculation valve expressed as a percentage of full travel.";
CM_ SG_ 2566755328 EngCrnkcsBrthrOilSeparatorSpeed "The speed of a rotating (centrifugal) crankcase oil separator.";
CM_ SG_ 2566755328 CmdedEngIntakeManifoldPress "Provides the commanded set point value for the engine intake manifold pressure.";
CM_ BO_ 2566745856 "Electronic Engine Controller 8";
CM_ SG_ 2566745856 EngExhstGsRcrcltn1ClrIntkGsAbsPr "Exhaust Gas Recirculation gas absolute pressure is measured at the EGR cooler intake.";
CM_ SG_ 2566745856 EngExhstGsRcrcltn1ClrIntakeTemp "Exhaust Gas Recirculation (EGR) Temperature measured at the EGR cooler intake.";
CM_ SG_ 2566745856 EngExhstGsRcrcltn1ClrEfficiency "Exhaust Gas Recirculation cooler efficiency is an indication of the cooler’s ability to reduce the temperature of the exhaust";
CM_ SG_ 2566745856 EngExhstGsRcrclation1Valve2Ctrl "Desired percentage of maximum Exhaust Gas Recirculation (EGR) valve opening for valve 2.";
CM_ BO_ 2566752510 "Engine Fluid Level/Pressure 5";
CM_ SG_ 2566752510 EngIntkVlvActtonOilPressForCyl4 "The gage pressure of the oil in the hydraulic accumulator that powers the engine intake valve for cylinder #4.";
CM_ SG_ 2566752510 EngIntkVlvActtonOilPressForCyl3 "The gage pressure of the oil in the hydraulic accumulator that powers the engine intake valve for cylinder #3.";
CM_ SG_ 2566752510 EngIntkVlvActtonOilPressForCyl2 "The gage pressure of the oil in the hydraulic accumulator that powers the engine intake valve for cylinder #2.";
CM_ SG_ 2566752510 EngIntkVlvActtonOilPressForCyl1 "The gage pressure of the oil in the hydraulic accumulator that powers the engine intake valve for cylinder #1.";
CM_ BO_ 2566752254 "Engine Fluid Level/Pressure 6";
CM_ SG_ 2566752254 EngIntkVlvActtonOilPressForCyl8 "The gage pressure of the oil in the hydraulic accumulator that powers the engine intake valve for cylinder #8.";
CM_ SG_ 2566752254 EngIntkVlvActtonOilPressForCyl7 "The gage pressure of the oil in the hydraulic accumulator that powers the engine intake valve for cylinder #7.";
CM_ SG_ 2566752254 EngIntkVlvActtonOilPressForCyl6 "The gage pressure of the oil in the hydraulic accumulator that powers the engine intake valve for cylinder #6.";
CM_ SG_ 2566752254 EngIntkVlvActtonOilPressForCyl5 "The gage pressure of the oil in the hydraulic accumulator that powers the engine intake valve for cylinder #5.";
CM_ BO_ 2566751998 "Engine Fluid Level/Pressure 7";
CM_ SG_ 2566751998 EngIntkVlvActtnOilPressForCyl12 "The gage pressure of the oil in the hydraulic accumulator that powers the engine intake valve for cylinder #12.";
CM_ SG_ 2566751998 EngIntkVlvActtnOilPressForCyl11 "The gage pressure of the oil in the hydraulic accumulator that powers the engine intake valve for cylinder #11.";
CM_ SG_ 2566751998 EngIntkVlvActtnOilPressForCyl10 "The gage pressure of the oil in the hydraulic accumulator that powers the engine intake valve for cylinder #10.";
CM_ SG_ 2566751998 EngIntkVlvActtonOilPressForCyl9 "The gage pressure of the oil in the hydraulic accumulator that powers the engine intake valve for cylinder #9.";
CM_ BO_ 2566751742 "Engine Fluid Level/Pressure 8";
CM_ SG_ 2566751742 EngIntkVlvActtnOilPressForCyl16 "The gage pressure of the oil in the hydraulic accumulator that powers the engine intake valve for cylinder #16.";
CM_ SG_ 2566751742 EngIntkVlvActtnOilPressForCyl15 "The gage pressure of the oil in the hydraulic accumulator that powers the engine intake valve for cylinder #15.";
CM_ SG_ 2566751742 EngIntkVlvActtnOilPressForCyl14 "The gage pressure of the oil in the hydraulic accumulator that powers the engine intake valve for cylinder #14.";
CM_ SG_ 2566751742 EngIntkVlvActtnOilPressForCyl13 "The gage pressure of the oil in the hydraulic accumulator that powers the engine intake valve for cylinder #13.";
CM_ BO_ 2566751486 "Engine Fluid Level/Pressure 9";
CM_ SG_ 2566751486 EngIntkVlvActtnOilPressForCyl20 "The gage pressure of the oil in the hydraulic accumulator that powers the engine intake valve for cylinder #20.";
CM_ SG_ 2566751486 EngIntkVlvActtnOilPressForCyl19 "The gage pressure of the oil in the hydraulic accumulator that powers the engine intake valve for cylinder #19.";
CM_ SG_ 2566751486 EngIntkVlvActtnOilPressForCyl18 "The gage pressure of the oil in the hydraulic accumulator that powers the engine intake valve for cylinder #18.";
CM_ SG_ 2566751486 EngIntkVlvActtnOilPressForCyl17 "The gage pressure of the oil in the hydraulic accumulator that powers the engine intake valve for cylinder #17.";
CM_ BO_ 2499641854 "EGR Cooler Bypass";
CM_ SG_ 2499641854 EGR1CoolerBypassActuatorPostion "The parameter gives the % open of the EGR Cooler Bypass Actuator, where 0% = Fully Closed (no gas flowing through";
CM_ BO_ 2566748158 "Engine Spark Voltage 1";
CM_ SG_ 2566748158 EngSparkPlug4 "The measured voltage of the spark event on Cylinder #4";
CM_ SG_ 2566748158 EngSparkPlug3 "The measured voltage of the spark event on Cylinder #3";
CM_ SG_ 2566748158 EngSparkPlug2 "The measured voltage of the spark event on Cylinder #2";
CM_ SG_ 2566748158 EngSparkPlug1 "The measured voltage of the spark event on Cylinder #1";
CM_ BO_ 2566747902 "Engine Spark Voltage 2";
CM_ SG_ 2566747902 EngSparkPlug8 "The measured voltage of the spark event on Cylinder #8";
CM_ SG_ 2566747902 EngSparkPlug7 "The measured voltage of the spark event on Cylinder #7";
CM_ SG_ 2566747902 EngSparkPlug6 "The measured voltage of the spark event on Cylinder #6";
CM_ SG_ 2566747902 EngSparkPlug5 "The measured voltage of the spark event on Cylinder #5";
CM_ BO_ 2566747646 "Engine Spark Voltage 3";
CM_ SG_ 2566747646 EngSparkPlug12 "The measured voltage of the spark event on Cylinder #12";
CM_ SG_ 2566747646 EngSparkPlug11 "The measured voltage of the spark event on Cylinder #11";
CM_ SG_ 2566747646 EngSparkPlug10 "The measured voltage of the spark event on Cylinder #10";
CM_ SG_ 2566747646 EngSparkPlug9 "The measured voltage of the spark event on Cylinder #9";
CM_ BO_ 2566747390 "Engine Spark Voltage 4";
CM_ SG_ 2566747390 EngSparkPlug16 "The measured voltage of the spark event on Cylinder #16";
CM_ SG_ 2566747390 EngSparkPlug15 "The measured voltage of the spark event on Cylinder #15";
CM_ SG_ 2566747390 EngSparkPlug14 "The measured voltage of the spark event on Cylinder #14";
CM_ SG_ 2566747390 EngSparkPlug13 "The measured voltage of the spark event on Cylinder #13";
CM_ BO_ 2566747134 "Engine Spark Voltage 5";
CM_ SG_ 2566747134 EngSparkPlug20 "The measured voltage of the spark event on Cylinder #20";
CM_ SG_ 2566747134 EngSparkPlug19 "The measured voltage of the spark event on Cylinder #19";
CM_ SG_ 2566747134 EngSparkPlug18 "The measured voltage of the spark event on Cylinder #18";
CM_ SG_ 2566747134 EngSparkPlug17 "The measured voltage of the spark event on Cylinder #17";
CM_ BO_ 2566746878 "Engine Spark Voltage 6";
CM_ SG_ 2566746878 EngSparkPlug24 "The measured voltage of the spark event on Cylinder #24";
CM_ SG_ 2566746878 EngSparkPlug23 "The measured voltage of the spark event on Cylinder #23";
CM_ SG_ 2566746878 EngSparkPlug22 "The measured voltage of the spark event on Cylinder #22";
CM_ SG_ 2566746878 EngSparkPlug21 "The measured voltage of the spark event on Cylinder #21";
CM_ BO_ 2561277694 "Forward Lane Image Command";
CM_ SG_ 2561277694 LaneDepartureWarningEnableCmd "Command to enable/disable Lane Departure Indication";
CM_ BO_ 2633861886 "SAE J2012 DTC Display";
CM_ SG_ 2633861886 J2012DTCOccurrenceCount "Number of occurrences of the respective SAE J2012 DTC being conveyed.";
CM_ SG_ 2633861886 J2012DTCStatus "Indicates if the respective SAE J2012 DTC is active or previously active.";
CM_ SG_ 2633861886 NumberOfJ2012DTCs "The number J2012 DTCs being conveyed in PGN 64906.";
CM_ BO_ 2565873150 "Steering Angle Sensor Information";
CM_ SG_ 2565873150 MessageChecksum "The message checksum is used to verify the signal path from the demanding device to the steering controller.";
CM_ SG_ 2565873150 MessageCounter "The message counter is to verify the signal path from the demanding device to the steering controller.";
CM_ SG_ 2565873150 SteerAngleSensorCalibrated "This signal indicates the calibration status of the steering angle sensor.";
CM_ SG_ 2565873150 SteerAngleSensorActiveMode "This signal indicates the operational mode of the steering angle sensor.";
CM_ SG_ 2565873150 SteerWheelAngleRange "The signal indicates the range of the steering wheel angle the sensor element is capable to measure.";
CM_ SG_ 2565873150 SteerWheelAngleRangeCounterType "The signal indicates whether the steering wheel angle sensor is capable of absolute measuring of the number of steering";
CM_ SG_ 2565873150 SteerWheelAngleRangeCounter "The signal indicates the number of steering wheel angle range overflows if the operating range of steering wheel is";
CM_ SG_ 2565873150 SteerWheelAngle "The main operator`s steering wheel angle (on the steering column, not the actual wheel angle).";
CM_ BO_ 2566745854 "Aftertreatment 1 SCR Service Information";
CM_ SG_ 2566745854 Aftrtrtmnt1SCRCtlystCnvrsnEffcnc "The SCR catalyst conversion efficiency percentage.";
CM_ SG_ 2566745854 Aftrtrtmnt1SCRCmddCtlystRgntCnsm "This parameter transmits the amount of reagent that the emissions control system has requested to be used, averaged";
CM_ SG_ 2566745854 Aftrtrtmnt1SCRAvrgCtlystRgntCnsm "Measured use of reagent by a Selective Catalytic Reduction system for exhaust emission control, averaged over the";
CM_ SG_ 2566745854 Aftrtrtmnt1DslExhstFldTnkLwLvlIn "The distance traveled while diesel exhaust fluid is low/empty or driver warning/inducement strategy is active.";
CM_ BO_ 2566751230 "Transfer Case Information";
CM_ SG_ 2566751230 TransferCaseStatus "This parameter describes the feedback from the transfer case controller .";
CM_ BO_ 2566755838 "Transmission Fluids 2";
CM_ SG_ 2566755838 TrnsTrqueConverterOilOutletTemp "Temperature of transmission torque converter outlet oil.";
CM_ SG_ 2566755838 TransOverheatIndicator "Signal from transmission indicating that its fluid temperature is above normal acceptable limits, and as a result,";
CM_ SG_ 2566755838 TransOilLifeRemaining "Signal which indicates the actual oil life remaining in percent.";
CM_ SG_ 2566755838 TransOilLevelSwitch "This switch indicates whether transmission oil level is full or empty.";
CM_ SG_ 2566755838 TransOilFilterRestrictionSwitch "This switch indicates whether the transmission oil filter is clogged.";
CM_ BO_ 2566752766 "Vehicle Direction/Speed 2";
CM_ SG_ 2566752766 VehicleRoll "This parameter indicates the roll in degrees from level.";
CM_ BO_ 2633938942 "Engine Speed/Load Factor Information";
CM_ SG_ 2633938942 TotalEngCruiseTime "Total time that the engine has operated in the cruise hold state, excluding time in accelerator override, over the life of the engine.";
CM_ SG_ 2633938942 TotalDriveAverageLoadFactor "Average engine load factor while engine speed is greater than zero, vehicle speed is greater than or equal to 2 km/h, and";
CM_ SG_ 2633938942 TripDriveAverageLoadFactor "Average engine load factor while engine speed is greater than zero, vehicle speed is greater than or equal to 2 km/h, and";
CM_ SG_ 2633938942 TripAverageEngSpeed "Average speed of the engine since the last trip reset.";
CM_ SG_ 2633938942 TripMaxEngSpeed "Maximum engine speed achieved since the last trip reset.";
CM_ BO_ 2566799614 "Lighting Data";
CM_ SG_ 2566799614 ImplementRearWorkLight "This parameter provides measured data from the implement rear work lamps.";
CM_ SG_ 2566799614 ImplementLeftForwardWorkLight "This parameter provides measured data from the forward facing work lights toward the left end of the implement.";
CM_ SG_ 2566799614 ImplementRightForwardWorkLight "This parameter provides measured data from the forward facing work lights toward the right end of the implement.";
CM_ SG_ 2566799614 ImplementLeftFacingWorkLight "This parameter provides measured data from the work lights mounted on an implement to illuminate beyond left end of";
CM_ SG_ 2566799614 ImplementRightFacingWorkLight "This parameter provides measured data from the work lights mounted on an implement to illuminate beyond right end of";
CM_ SG_ 2566799614 ImplementOEMOption1Light "This parameter provides measured data from the implement OEM option 1 light.";
CM_ SG_ 2566799614 ImplementOEMOption2Light "This parameter provides measured data from the implement OEM option 2 light.";
CM_ SG_ 2566799614 TrctrFrontHighMountedWorkLights "This parameter provides measured data from the tractor front high mounted work lights.";
CM_ SG_ 2566799614 TrctorFrontLowMountedWorkLights "This parameter provides measured data from the tractor front low mounted work lights.";
CM_ SG_ 2566799614 TrctorSideHighMountedWorkLights "This parameter provides measured data from the tractor side high mounted work lights.";
CM_ SG_ 2566799614 TractorSideLowMountedWorkLights "This parameter provides measured data from the tractor side low mounted work lights.";
CM_ SG_ 2566799614 TrctorRearHighMountedWorkLights "This parameter provides measured data from the tractor rear high mounted work lights.";
CM_ SG_ 2566799614 TractorRearLowMountedWorkLights "This parameter provides measured data from the tractor rear low mounted work lights.";
CM_ SG_ 2566799614 TrctrUndersideMountedWorkLights "This parameter provides measured data from the tractor underside mounted work lights.";
CM_ SG_ 2566799614 RearFogLights "This parameter provides measured data from the tractor and/or implement rear fog lights.";
CM_ SG_ 2566799614 TractorMarkerLight "This parameter provides measured data from the tractor and attached implement marker lights, including front position";
CM_ SG_ 2566799614 ImplementMarkerLight "This parameter provides measured data from an attached implement marker lights, including front position lights, rear tail";
CM_ SG_ 2566799614 TractorClearanceLight "This parameter provides measured data from the tractor high mounted clearance and center ID lights.";
CM_ SG_ 2566799614 ImplementClearanceLight "This parameter provides measured data from an attached implement high mounted clearance lights.";
CM_ SG_ 2566799614 LeftStopLight "This parameter provides measured data from the tractor and attached implement left stop lights.";
CM_ SG_ 2566799614 RightStopLight "This parameter provides measured data from the tractor and attached implement right stop lights.";
CM_ SG_ 2566799614 CenterStopLight "This parameter provides measured data from the tractor and attached implement center stop lights.";
CM_ SG_ 2566799614 BackUpLightAndAlarmHorn "This parameter provides measured data from the back up lights and/ or associated alarm.";
CM_ SG_ 2566799614 LeftTurnSignalLights "This parameter provides measured data from the tractor and attached implement left turn signal lights.";
CM_ SG_ 2566799614 RightTurnSignalLights "This parameter provides measured data from the tractor and attached implement right turn signal lights.";
CM_ SG_ 2566799614 RotatingBeaconLight "This parameter provides measured data from the beacon light on tractor or attached implements.";
CM_ SG_ 2566799614 TractorFrontFogLights "This parameter provides measured data from the tractor front fog lights.";
CM_ SG_ 2566799614 HighBeamHeadLightData "This parameter provides measured data from the tractor high beam head light lamps.";
CM_ SG_ 2566799614 LowBeamHeadLightData "This parameter provides measured data from the tractor low beam head light lamps.";
CM_ SG_ 2566799614 AltBeamHeadLightData "This parameter provides measured data from the tractor alternate beam head light lamps.";
CM_ SG_ 2566799614 RunningLight "This parameter provides measured data from the vehicle’s running lights.";
CM_ BO_ 2365473278 "Lighting Command";
CM_ SG_ 2365473278 ImplementRearWorkLightCmd "Command to activate or de-activate implement rear work lights.";
CM_ SG_ 2365473278 ImplmentLeftForwardWorkLightCmd "Command to activate or de-activate the forward facing work lights toward the left end of the implement.";
CM_ SG_ 2365473278 ImplmntRightForwardWorkLightCmd "Command to activate or de-activate the forward facing work lights toward the right end of the implement.";
CM_ SG_ 2365473278 LightingDataRqCmd "Command to provide a response of the light state";
CM_ SG_ 2365473278 ImplementLeftFacingWorkLightCmd "Command to activate or de-activate work lights mounted on an implement to illuminate beyond left end of the implement.";
CM_ SG_ 2365473278 ImplmentRightFacingWorkLightCmd "Command to activate or de-activate work lights mounted on an implement to illuminate beyond right end of the implement.";
CM_ SG_ 2365473278 ImplementOEMOption1LightCmd "Command to activate or de-activate an implement OEM option 1 light.";
CM_ SG_ 2365473278 ImplementOEMOption2LightCmd "Command to activate or de-activate an implement OEM option 2 light.";
CM_ SG_ 2365473278 TrctrFrntHghMuntedWorkLightsCmd "Command to activate or de-activate the tractor front high mounted work lights.";
CM_ SG_ 2365473278 TrctrFrntLwMountedWorkLightsCmd "Command to activate or de-activate the tractor front low mounted work lights.";
CM_ SG_ 2365473278 TrctrSdHighMountedWorkLightsCmd "Command to activate or de-activate the tractor side high mounted work lights.";
CM_ SG_ 2365473278 TrctrSdeLowMountedWorkLightsCmd "Command to activate or de-activate the tractor side low mounted work lights.";
CM_ SG_ 2365473278 TrctrRrHighMountedWorkLightsCmd "Command to activate or de-activate the tractor rear high mounted work lights.";
CM_ SG_ 2365473278 TrctrRarLowMountedWorkLightsCmd "Command to activate or de-activate the tractor rear low mounted work lights.";
CM_ SG_ 2365473278 TrctrUndrsdMountedWorkLightsCmd "Command to activate or de-activate the tractor underside mounted work lights.";
CM_ SG_ 2365473278 RearFogLightCmd "Command to activate or de-activate tractor or implement rear fog lights.";
CM_ SG_ 2365473278 TractorMarkerLightCmd "Command to activate or de-activate tractor and implement front position lights, rear red tail lights, side amber running";
CM_ SG_ 2365473278 ImplementMarkerLightCmd "Command to activate or de-activate implement front position lights, rear red tail lights, side amber running lights, license";
CM_ SG_ 2365473278 TractorClearanceLightCmd "Command to activate or de-activate the tractor high mounted clearance and center ID lights";
CM_ SG_ 2365473278 ImplementClearanceLightCmd "Command to activate or de-activate the implement high mounted clearance and lights.";
CM_ SG_ 2365473278 LeftStopLightCmd "Command to activate or de-activate the tractor and implement left stop lights";
CM_ SG_ 2365473278 RightStopLightCmd "Command to activate or de-activate the tractor and implement right stop light";
CM_ SG_ 2365473278 CenterStopLightCmd "Command to activate or de-activate the tractor and implement center stop light";
CM_ SG_ 2365473278 BackUpLightAndAlarmHornCmd "Command to activate or de-activate the back up lights and/ or associated alarm if required";
CM_ SG_ 2365473278 LeftTurnSignalLightsCmd "Command to activate or de-activate left turn signal lights on the tractor and all connected implements";
CM_ SG_ 2365473278 RightTurnSignalLightsCmd "Command to activate or de-activate right turn signal lights on the tractor and all connected implements";
CM_ SG_ 2365473278 RotatingBeaconLightCmd "Command to activate or de-activate slow moving vehicle indicator lights on tractor and/or implements.";
CM_ SG_ 2365473278 TractorFrontFogLightsCmd "Command to activate or de-activate tractor front fog lights.";
CM_ SG_ 2365473278 HighBeamHeadLightCmd "Command to activate or de-activate the tractor high beam head light lamps.";
CM_ SG_ 2365473278 LowBeamHeadLightCmd "Command to activate or de-activate the tractor low beam head light lamps.";
CM_ SG_ 2365473278 AltBeamHeadLightCmd "Command to activate or de-activate the tractor alternate head lights (only low beam is available on alternate head lights).";
CM_ SG_ 2365473278 RunningLightCmd "Command to activate or de-activate the tractor or powered vehicle running lights.";
CM_ BO_ 2365485822 "Laser Leveling System Blade Control";
CM_ SG_ 2365485822 BladeCtrlMode "Allows the user to select the type of blade control for the land leveling system.";
CM_ SG_ 2365485822 BladeDurationAndDirection "Used to indicate the duration and direction that the land leveling system blade moves.";
CM_ SG_ 2365485822 LandLevelingSystemEnableStatus "Communicate the enable/disable status of the Land Leveling System.";
CM_ SG_ 2365485822 BladeCtrlModeRight "Indicate if the land leveling system's automatic control is active or inactive for the elevation sensor on the right side of the";
CM_ SG_ 2365485822 BladeCtrlModeLeft "Indicate if the land leveling system's automatic control is active or inactive for the elevation sensor on the left side of the";
CM_ BO_ 2633926654 "Ignition Timing 6";
CM_ SG_ 2633926654 EngActualIgntTiming "The actual ignition timing at the current engine conditions.";
CM_ SG_ 2633926654 EngDesiredIgntTiming3 "A programmable timing value specific to the engine’s application.";
CM_ SG_ 2633926654 EngDesiredIgntTiming2 "A programmable timing value specific to the engine’s application.";
CM_ SG_ 2633926654 EngDesiredIgntTiming1 "A programmable timing value specific to the engine’s application.";
CM_ BO_ 2633926398 "Ignition Timing 5";
CM_ SG_ 2633926398 EngCyl20IgntTiming "The ignition timing of the cylinder.";
CM_ SG_ 2633926398 EngCyl19IgntTiming "The ignition timing of the cylinder.";
CM_ SG_ 2633926398 EngCyl18IgntTiming "The ignition timing of the cylinder.";
CM_ SG_ 2633926398 EngCyl17IgntTiming "The ignition timing of the cylinder.";
CM_ BO_ 2633926142 "Ignition Timing 4";
CM_ SG_ 2633926142 EngCyl16IgntTiming "The ignition timing of the cylinder.";
CM_ SG_ 2633926142 EngCyl15IgntTiming "The ignition timing of the cylinder.";
CM_ SG_ 2633926142 EngCyl14IgntTiming "The ignition timing of the cylinder.";
CM_ SG_ 2633926142 EngCyl13IgntTiming "The ignition timing of the cylinder.";
CM_ BO_ 2633925886 "Ignition Timing 3";
CM_ SG_ 2633925886 EngCyl12IgntTiming "The ignition timing of the cylinder.";
CM_ SG_ 2633925886 EngCyl11IgntTiming "The ignition timing of the cylinder.";
CM_ SG_ 2633925886 EngCyl10IgntTiming "The ignition timing of the cylinder.";
CM_ SG_ 2633925886 EngCyl9IgntTiming "The ignition timing of the cylinder.";
CM_ BO_ 2633925630 "Ignition Timing 2";
CM_ SG_ 2633925630 EngCyl8IgntTiming "The ignition timing of the cylinder.";
CM_ SG_ 2633925630 EngCyl7IgntTiming "The ignition timing of the cylinder.";
CM_ SG_ 2633925630 EngCyl6IgntTiming "The ignition timing of the cylinder.";
CM_ SG_ 2633925630 EngCyl5IgntTiming "The ignition timing of the cylinder.";
CM_ BO_ 2633925374 "Ignition Timing 1";
CM_ SG_ 2633925374 EngCyl4IgntTiming "The ignition timing of the cylinder.";
CM_ SG_ 2633925374 EngCyl3IgntTiming "The ignition timing of the cylinder.";
CM_ SG_ 2633925374 EngCyl2IgntTiming "The ignition timing of the cylinder.";
CM_ SG_ 2633925374 EngCyl1IgntTiming "The ignition timing of the cylinder.";
CM_ BO_ 2633927422 "Ignition Transformer Secondary Output 3";
CM_ SG_ 2633927422 EngCyl20IgntTransSecondOutput "This parameter indicates the relative intensity of the secondary output voltage of the ignition transformer.";
CM_ SG_ 2633927422 EngCyl19IgntTransSecondOutput "This parameter indicates the relative intensity of the secondary output voltage of the ignition transformer.";
CM_ SG_ 2633927422 EngCyl18IgntTransSecondOutput "This parameter indicates the relative intensity of the secondary output voltage of the ignition transformer.";
CM_ SG_ 2633927422 EngCyl17IgntTransSecondOutput "This parameter indicates the relative intensity of the secondary output voltage of the ignition transformer.";
CM_ BO_ 2633927166 "Ignition Transformer Secondary Output 2";
CM_ SG_ 2633927166 EngCyl16IgntTransSecondOutput "This parameter indicates the relative intensity of the secondary output voltage of the ignition transformer.";
CM_ SG_ 2633927166 EngCyl15IgntTransSecondOutput "This parameter indicates the relative intensity of the secondary output voltage of the ignition transformer.";
CM_ SG_ 2633927166 EngCyl14IgntTransSecondOutput "This parameter indicates the relative intensity of the secondary output voltage of the ignition transformer.";
CM_ SG_ 2633927166 EngCyl13IgntTransSecondOutput "This parameter indicates the relative intensity of the secondary output voltage of the ignition transformer.";
CM_ SG_ 2633927166 EngCyl12IgntTransSecondOutput "This parameter indicates the relative intensity of the secondary output voltage of the ignition transformer.";
CM_ SG_ 2633927166 EngCyl11IgntTransSecondOutput "This parameter indicates the relative intensity of the secondary output voltage of the ignition transformer.";
CM_ SG_ 2633927166 EngCyl10IgntTransSecondOutput "This parameter indicates the relative intensity of the secondary output voltage of the ignition transformer.";
CM_ SG_ 2633927166 EngCyl9IgntTransSecondOutput "This parameter indicates the relative intensity of the secondary output voltage of the ignition transformer.";
CM_ BO_ 2633926910 "Ignition Transformer Secondary Output 1";
CM_ SG_ 2633926910 EngCyl8IgntTransSecondOutput "This parameter indicates the relative intensity of the secondary output voltage of the ignition transformer.";
CM_ SG_ 2633926910 EngCyl7IgntTransSecondOutput "This parameter indicates the relative intensity of the secondary output voltage of the ignition transformer.";
CM_ SG_ 2633926910 EngCyl6IgntTransSecondOutput "This parameter indicates the relative intensity of the secondary output voltage of the ignition transformer.";
CM_ SG_ 2633926910 EngCyl5IgntTransSecondOutput "This parameter indicates the relative intensity of the secondary output voltage of the ignition transformer.";
CM_ SG_ 2633926910 EngCyl4IgntTransSecondOutput "This parameter indicates the relative intensity of the secondary output voltage of the ignition transformer.";
CM_ SG_ 2633926910 EngCyl3IgntTransSecondOutput "This parameter indicates the relative intensity of the secondary output voltage of the ignition transformer.";
CM_ SG_ 2633926910 EngCyl2IgntTransSecondOutput "This parameter indicates the relative intensity of the secondary output voltage of the ignition transformer.";
CM_ SG_ 2633926910 EngCyl1IgntTransSecondOutput "This parameter indicates the relative intensity of the secondary output voltage of the ignition transformer.";
CM_ BO_ 2566768894 "Operator Primary Intermediate Speed Control state";
CM_ SG_ 2566768894 EngOprtrPrmryIntrmdtSpdSlctStte "13 preprogrammed intermediate speed control settings are available for the controlling ECM to select.";
CM_ BO_ 2566769406 "Intermediate Speed Control";
CM_ SG_ 2566769406 EngOprtrPrmryIntrmdtSpeedSelect "Allows the operator to select one of 13 preprogrammed Intermediate Speed Control settings.";
CM_ BO_ 2566839550 "Idle Operation";
CM_ SG_ 2566839550 EngTotalIdleHours "Accumulated time of operation of the engine while under idle conditions.";
CM_ SG_ 2566839550 EngTotalIdleFuelUsed "Accumulated amount of fuel used during vehicle operation while under idle conditions.";
CM_ BO_ 2633934334 "Intake Manifold Information 2";
CM_ SG_ 2633934334 EngIntakeManifold6Temp "Temperature of pre-combustion air found in intake manifold number 6 of engine air supply system.";
CM_ SG_ 2633934334 EngIntakeManifold5Temp "Temperature of pre-combustion air found in intake manifold number 5 of engine air supply system.";
CM_ SG_ 2633934334 EngIntakeManifold4Temp "Temperature of pre-combustion air found in intake manifold of engine air supply system.";
CM_ SG_ 2633934334 EngIntakeManifold3Temp "Temperature of pre-combustion air found in intake manifold of engine air supply system.";
CM_ SG_ 2633934334 EngIntakeManifold2Temp "Temperature of pre-combustion air found in intake manifold of engine air supply system.";
CM_ BO_ 2566825726 "Intake Manifold Information 1";
CM_ SG_ 2566825726 EngTurbo4BoostPress "Gage pressure of air measured downstream of the compressor discharge side of the turbocharger.";
CM_ SG_ 2566825726 EngTurbo3BoostPress "Gage pressure of air measured downstream of the compressor discharge side of the turbocharger.";
CM_ SG_ 2566825726 EngTurbo2BoostPress "Gage pressure of air measured downstream of the compressor discharge side of the turbocharger.";
CM_ SG_ 2566825726 EngTurbo1BoostPress "Gage pressure of air measured downstream of the compressor discharge side of the turbocharger.";
CM_ BO_ 2566770688 "Intake/Exhaust Conditions 2";
CM_ SG_ 2566770688 EngAirFilter4DiffPress "Change in engine air system pressure, measured across the fourth air filter, due to the filter and any accumulation of solid";
CM_ SG_ 2566770688 EngAirFilter3DiffPress "Change in engine air system pressure, measured across the third air filter, due to the filter and any accumulation of solid";
CM_ SG_ 2566770688 EngAirFilter2DiffPress "Change in engine air system pressure, measured across the second air filter, due to the filter and any accumulation of";
CM_ SG_ 2566770688 EngIntakeManifold1AbsPress "The absolute pressure measurement of the air intake manifold.The absolute pressure measurement of the air intake manifold.";
CM_ SG_ 2566770688 EngIntakeManifold2AbsPress "The absolute pressure measurement of the air intake manifold for bank 2 or the second air intake manifold.";
CM_ SG_ 2566770688 EngIntakeManifold2Press "The gage pressure measurement of the air intake manifold for bank #2 or the second air intake manifold.";
CM_ SG_ 2566770688 EngIntakeManifold1AbsPressHiRes "The absolute pressure measurement of the air intake manifold.The absolute pressure measurement of the air intake manifold.";
CM_ BO_ 2566845952 "Intake/Exhaust Conditions 1";
CM_ SG_ 2566845952 EngCoolantFilterDiffPress "Change in coolant pressure, measured across the filter, due to the filter and any accumulation of solid or semisolid matter";
CM_ SG_ 2566845952 EngExhaustGasTemp "Temperature of combustion byproducts leaving the engine.";
CM_ SG_ 2566845952 EngAirFilter1DiffPress "Change in engine air system pressure, measured across the filter, due to the filter and any accumulation of solid foreign";
CM_ SG_ 2566845952 EngIntakeManifold1Temp "Temperature of pre-combustion air found in intake manifold of engine air supply system.";
CM_ SG_ 2566845952 EngIntakeManifold1Press "The gage pressure measurement of the air intake manifold.";
CM_ SG_ 2566845952 EngDslPrtclateFilterIntakePress "Exhaust back pressure as a result of particle accumulation on filter media placed in the exhaust stream.";
CM_ SG_ 2566845952 EngAirIntakePress "Absolute air pressure at input port to intake manifold or air box.";
CM_ BO_ 2566811134 "Heater Information";
CM_ SG_ 2566811134 CabHeatingZone "Parameter indicating whether the cab zone is being heated.";
CM_ SG_ 2566811134 EngHeatingZone "Parameter indicating whether the engine zone is being heated.";
CM_ SG_ 2566811134 CabVentilation "Indicates whether the cab is being ventilated or not.";
CM_ SG_ 2566811134 AuxHeaterMode "State of the auxiliary heater";
CM_ SG_ 2566811134 AuxHeaterOutputPowerPercent "Current auxiliary heater output power, relative to the auxiliary heater maximum output power.";
CM_ SG_ 2566811134 AuxHeaterInputAirTemp "Temperature of the input air in an auxiliary heater system.";
CM_ SG_ 2566811134 AuxHeaterOutputCoolantTemp "Temperature of the auxiliary heater output coolant (I.";
CM_ SG_ 2566811134 AuxHeaterWaterPumpStatus "Parameter indicating whether the auxiliary heater water pump is running";
CM_ BO_ 2298375934 "High Resolution Wheel Speed";
CM_ SG_ 2298375934 RearAxleRightWheelSpeed "High resolution measurement of the speed of the right wheel on the rear axle.";
CM_ SG_ 2298375934 RearAxleLeftWheelSpeed "High resolution measurement of the speed of the left wheel on the rear axle.";
CM_ SG_ 2298375934 FrontAxleRightWheelSpeed "High resolution measurement of the speed of the right wheel on the front axle.";
CM_ SG_ 2298375934 FrontAxleLeftWheelSpeed "High resolution measurement of the speed of the left wheel on the front axle.";
CM_ BO_ 2565867774 "Hydraulic Pressure Governor Info";
CM_ SG_ 2565867774 FireApparatusPumpEngagement "The measured status of the pump used to provide water in fire fighting apparatus for distribution of water through water";
CM_ SG_ 2565867774 EngHydPressGovernorSwitch "Switch that sets the mode of hydraulic governor";
CM_ SG_ 2565867774 EngHydPrssGovernorModeIndicator "Mode for governor operation is hydraulic pressure control.";
CM_ SG_ 2565867774 HydPress "Hydraulic pressure measured at the output of the hydraulic pump.";
CM_ BO_ 2566841854 "Engine Hours, Revolutions";
CM_ SG_ 2566841854 EngTotalRevolutions "Accumulated number of revolutions of engine crankshaft during its operation.";
CM_ SG_ 2566841854 EngTotalHoursOfOperation "Accumulated time of operation of engine.";
CM_ BO_ 2365449982 "Hydraulic Braking System";
CM_ SG_ 2365449982 HydBrakeFluidLevelSwitch "Signal which indicates whether the hydraulic fluid level in the reservoir(s) is sufficient.";
CM_ SG_ 2365449982 HydBrakeSystemAudibleWarningCmd "Signal which commands an audible warning by the hydraulic braking system.";
CM_ SG_ 2365449982 HydBrkePressSupplyStateCircuit2 "Signal which indicates whether the hydraulic brake pressure supply of circuit 2 is reliable; that is, able to support";
CM_ SG_ 2365449982 HydBrkePressSupplyStateCircuit1 "Signal which indicates whether the hydraulic brake pressure supply of circuit 1 is reliable; that is, able to support";
CM_ SG_ 2365449982 HydBrkPressWarningStateCircuit2 "Signal which indicates whether the hydraulic brake pressure of circuit 2 is below the warning level";
CM_ SG_ 2365449982 HydBrkPressWarningStateCircuit1 "Signal which indicates whether the hydraulic brake pressure of circuit 1 is below the warning level";
CM_ SG_ 2365449982 HydBrakePressCircuit2 "Gage hydraulic pressure in circuit 2 of the hydraulic brake system";
CM_ SG_ 2365449982 HydBrakePressCircuit1 "Gage hydraulic pressure in circuit 1 of the hydraulic brake system";
CM_ BO_ 2633939198 "Trip Fuel Information (Gaseous)";
CM_ SG_ 2633939198 TripDriveFuelEconomy "Trip drive fuel economy is equal to the distance traveled by vehicle in the drive state (engine speed greater than zero,";
CM_ SG_ 2633939198 TrpPTOGovernorNonmovingFuelUsed "Total fuel consumed while the PTO or remote PTO governors are in the hold state, the engine speed is greater than zero,";
CM_ SG_ 2633939198 TripVehicleIdleFuelUsed "Total fuel consumed while neither the PTO or remote PTO governors are active, the engine speed is greater than zero,";
CM_ SG_ 2633939198 TripCruiseFuelUsed "Total fuel consumed while the engine is in the cruise hold state since the last trip reset.";
CM_ SG_ 2633939198 TripDriveFuelUsed "Total fuel consumed while the engine speed is greater than zero, vehicle speed is greater than or equal to 2 km/h, and";
CM_ SG_ 2633939198 TripPTOGovernorMovingFuelUsed "Total fuel consumed while either the PTO or remote PTO governors are in the hold state, the engine speed is greater";
CM_ BO_ 2633927678 "Gaseous Fuel Pressure";
CM_ SG_ 2633927678 EngFuelValve1OutletAbsPress "Absolute Pressure of gas on outlet side of the first or only fuel system control valve.";
CM_ SG_ 2633927678 EngAirToFuelDiffPress "The differential pressure between the gaseous fuel and the air intake manifold.";
CM_ SG_ 2633927678 EngFuelValveDiffPress "The differential pressure between the intake and the outlet of a gaseous fuel valve.";
CM_ SG_ 2633927678 EngFuelValve1IntakeAbsPress "The absolute pressure of gas on the intake side of the first system control valve.";
CM_ BO_ 2633925118 "Fuel Information 2 (Gaseous)";
CM_ SG_ 2633925118 EngFuelFlowRate2 "The rate at which the fuel is flowing through a fuel valve.";
CM_ SG_ 2633925118 EngFuelFlowRate1 "The rate at which the fuel is flowing through a fuel valve.";
CM_ SG_ 2633925118 EngRqedFuelValve2Pos "The requested position of a gaseous fuel valve 2 that is metering the fuel flow to the engine, as requested by the Engine";
CM_ SG_ 2633925118 EngRqedFuelValve1Pos "The requested position of a gaseous fuel valve 1 that is metering the fuel flow to the engine.";
CM_ SG_ 2633925118 EngFuelValve2Pos "The position of a gaseous fuel valve that is metering the fuel flow to the engine.";
CM_ SG_ 2633925118 EngFuelValve1Pos "The position of a gaseous fuel valve that is metering the fuel flow to the engine.";
CM_ BO_ 2633937662 "Fuel Information 1 (Gaseous)";
CM_ SG_ 2633937662 TotalEngPTOGovernorFuelUsed "Total fuel used while the PTO or remote PTO governors are in the hold state and engine speed is above zero, over the";
CM_ SG_ 2633937662 TripAverageFuelRate "Average fuel rate, equal to trip fuel divided by trip time while the engine speed is above zero, since the last trip reset.";
CM_ SG_ 2633937662 EngFuelSpecificGravity "This parameter conveys the specific gravity of the gaseous fuel being used by the engine.";
CM_ BO_ 2566804990 "Gaseous Fuel Properties";
CM_ SG_ 2566804990 SpecificHeatRatio "The specific heat ratio of the fuel.";
CM_ BO_ 2633936894 "Fuel Consumption (Gaseous)";
CM_ SG_ 2633936894 TotalFuelUsed "Total fuel consumed (trip drive fuel + trip PTO moving fuel + trip PTO non-moving fuel + trip idle fuel) over the life of the engine.";
CM_ SG_ 2633936894 TripFuel "Total fuel consumed (trip drive fuel + trip PTO moving fuel + trip PTO non-moving fuel + trip idle fuel) since the last trip reset.";
CM_ BO_ 2566757630 "Sensor Electrical Power #2";
CM_ SG_ 2566757630 SensorSupplyVoltage6 "Sensor ECU supply voltage 6";
CM_ SG_ 2566757630 SensorSupplyVoltage5 "Sensor ECU supply voltage 5";
CM_ SG_ 2566757630 SensorSupplyVoltage8 "Sensor ECU supply voltage 8";
CM_ SG_ 2566757630 SensorSupplyVoltage7 "Sensor ECU supply voltage 7";
CM_ BO_ 2566757886 "Sensor Electrical Power #1";
CM_ SG_ 2566757886 SensorSupplyVoltage4 "Sensor ECU supply voltage 4";
CM_ SG_ 2566757886 SensorSupplyVoltage3 "Sensor ECU supply voltage 3";
CM_ SG_ 2566757886 SensorSupplyVoltage2 "Sensor ECU supply voltage 2";
CM_ SG_ 2566757886 SensorSupplyVoltage1 "Sensor ECU supply voltage 1";
CM_ BO_ 2566759678 "PTO Drive Engagement";
CM_ SG_ 2566759678 EnggmntSttusTransInputShaftPTO1 "Reports if this specific PTO drive is engaged.";
CM_ SG_ 2566759678 EnggmntSttusTransInputShaftPTO2 "Reports if this specific PTO drive is engaged.";
CM_ SG_ 2566759678 EnggmntSttusTransOutputShaftPTO "Reports if this specific PTO drive is engaged.";
CM_ SG_ 2566759678 EnggmntSttsTrnsfrCsOtptShaftPTO "Reports if this specific PTO drive is engaged.";
CM_ SG_ 2566759678 EnggmntCnsntTransInputShaftPTO1 "Status of the transmission controller’s consent to engage the first or sole PTO drive mounted on the transmission case.";
CM_ SG_ 2566759678 EnggmntCnsntTransInputShaftPTO2 "Status of the transmission controller’s consent to engage the second PTO drive mounted on the transmission case.";
CM_ SG_ 2566759678 EnggmntCnsntTransOutputShaftPTO "Status of the transmission controller’s consent to engage the PTO drive connected to the transmission output shaft.";
CM_ SG_ 2566759678 EnggmntCnsntTrnsfrCsOtptShftPTO "Status of the transmission controller’s consent to engage the PTO drive connected to the transfer case output shaft.";
CM_ SG_ 2566759678 EnableSwitchTransInputShaftPTO1 "Status of the operator’s switch or other input which indicates the desire for engaging the first PTO drive mounted on the";
CM_ SG_ 2566759678 EnableSwitchTransInputShaftPTO2 "Status of the operator’s switch or other input which indicates the desire for engaging the second PTO drive mounted on";
CM_ SG_ 2566759678 EnableSwitchTransOutputShaftPTO "Status of the operator’s switch or other input which indicates the desire for engaging the PTO drive mounted on the";
CM_ SG_ 2566759678 EnblSwtchTrnsfrCsOutputShaftPTO "Status of the operator’s switch or other input which indicates the desire for engaging the PTO drive mounted on the output";
CM_ SG_ 2566759678 EnggmntSttsPTOEngAccssoryDrive2 "Engagement status of the PTO engine accessory drive 2";
CM_ SG_ 2566759678 EnggmntSttsPTOEngAccssoryDrive1 "Engagement status of the PTO engine accessory drive 1";
CM_ SG_ 2566759678 EnggmntCnsntPTOEngAccssryDrive2 "Engagement Consent status for the PTO engine accessory drive 2";
CM_ SG_ 2566759678 EnggmntCnsntPTOEngAccssryDrive1 "Engagement consent status for the PTO engine accessory drive 1";
CM_ SG_ 2566759678 EngagementStatusPTOEngFlywheel "Engagement status of the PTO Engine Flywheel";
CM_ SG_ 2566759678 EngagementConsentPTOEngFlywheel "Engagement Consent status for the PTO Engine Flywheel";
CM_ SG_ 2566759678 EnblSwitchPTOEngAccessoryDrive2 "Status of the PTO engine accessory drive 2 enable switch";
CM_ SG_ 2566759678 EnblSwitchPTOEngAccessoryDrive1 "Status of the PTO engine accessory drive 1 enable switch";
CM_ SG_ 2566759678 EnableSwitchPTOEngFlywheel "Status of the PTO Engine Flywheel enable switch";
CM_ SG_ 2566759678 AtLeastOnePTOEngaged "Indicates that at least one PTO is engaged";
CM_ BO_ 2432541438 "Fuel Information 3 (Gaseous)";
CM_ SG_ 2432541438 EngFuelValve2OutletAbsPress "Absolute pressure of gas on outlet side of the second fuel system control valve.";
CM_ SG_ 2432541438 EngFuelTemp2 "Temperature 2 of fuel (or gas).";
CM_ SG_ 2432541438 EngGas2MassFlowRate "Gas mass flow rate delivered to an engine through its second fuel control system, using standard convention for";
CM_ SG_ 2432541438 EngFuelValve2IntakeAbsPress "Absolute pressure of gas on intake side of the second fuel system control valve, using standard convention for";
CM_ BO_ 2566760960 "Engine Fluid Level/Pressure 4";
CM_ SG_ 2566760960 EngCentrifugalOilFilterSpeed "The speed of a rotating (centrifugal) engine oil filter.";
CM_ SG_ 2566760960 EngCoolantPumpDiffPress "The differential pressure measured across the input and output of the engine coolant pump.";
CM_ SG_ 2566760960 EngChargeAirCooler2IntakePress "Pressure of air at intake to 2nd charge air cooler, from multiple first stage turbochargers being cooled and feeding multiple";
CM_ SG_ 2566760960 EngChargeAirCooler1IntakePress "Pressure of air at intake to 1st or only charge air cooler, from multiple first stage turbochargers being cooled and feeding";
CM_ SG_ 2566760960 EngIntercoolerCoolantLevel "Ratio of volume of liquid found in an engine intercooler cooling system to total engine intercooler cooling system volume.";
CM_ SG_ 2566760960 EngChargeAirCoolerOutletPress "Measures pressure of air at outlet from charge air cooler";
CM_ SG_ 2566760960 EngAftercoolerCoolantLevel "Ratio of aftercooler coolant system volume of liquid to total cooling system volume.";
CM_ BO_ 2432541440 "Electronic Engine Controller 6";
CM_ SG_ 2432541440 EngVrableGeometryTurboActuator1 "Actuator that controls the variable geometry turbocharger geometry.";
CM_ SG_ 2432541440 EngTrbCmprssrBypssActtr1TmpStts "Used to identify the status of the Engine Turbocharger Compresssor Bypass Actuator 1 drive circuitry temperature.";
CM_ SG_ 2432541440 EngTrbCmprssrBypssActtr1PrlmnryF "Used to identify the appplicable J1939-73 FMI detected in the Engine Turbocharger Compressor Bypass Actuator 1 by";
CM_ SG_ 2432541440 EngTrbCmprssrBypassActuator2Cmd "The command to a compressor bypass actuator 2, normalized to percent, where 0% nominally represents fully closed and";
CM_ SG_ 2432541440 EngTrbCmprssrBypassActuator1Pos "Measures the position of the turbocharger compressor bypass actuator, where 0% represents bypass fully closed and";
CM_ SG_ 2432541440 EngTrbCmprssrBypassActuator1Cmd "The command to a compressor bypass actuator, normalized to percent, where 0% nominally represents fully closed and";
CM_ SG_ 2432541440 EngDsrdTrbCmprssrBypssActtr1Pos "The requested position of the Engine Turbocharger Compressor Bypass actuator by the engine ECM, where 0%";
BA_DEF_ SG_  "SigType" ENUM  "Default","Range","RangeSigned","ASCII","Discrete","Control","ReferencePGN","DTC","StringDelimiter","StringLength","StringLengthControl";
BA_DEF_ SG_  "GenSigStartValue" INT 0 10000;
BA_DEF_ SG_  "GenSigSendType" ENUM  "Cyclic","OnWrite","reserved","OnChange","reserved","reserved","reserved","NoSigSendType";
BA_DEF_ SG_  "GenSigILSupport" ENUM  "Yes","No";
BA_DEF_ SG_  "GenSigEVName" STRING ;
BA_DEF_ SG_  "SPN" INT 0 524287;
BA_DEF_ BO_  "GenMsgStartDelayTime" INT 0 100000;
BA_DEF_ BO_  "GenMsgILSupport" ENUM  "Yes","No";
BA_DEF_ BO_  "GenMsgRequestable" INT 0 1;
BA_DEF_ BO_  "GenMsgSendType" ENUM  "cyclic","reserved","cyclicIfActive","reserved","reserved","reserved","reserved","reserved","noMsgSendType";
BA_DEF_ BO_  "VFrameFormat" ENUM  "StandardCAN","ExtendedCAN","reserved";
BA_DEF_ BO_  "GenMsgCycleTime" INT 0 3600000;
BA_DEF_ SG_  "SystemSignalLongSymbol" STRING ;
BA_DEF_DEF_  "SigType" "Default";
BA_DEF_DEF_  "GenSigStartValue" 0;
BA_DEF_DEF_  "GenSigSendType" "NoSigSendType";
BA_DEF_DEF_  "GenSigILSupport" "Yes";
BA_DEF_DEF_  "GenSigEVName" "Env@Nodename_@Signame";
BA_DEF_DEF_  "SPN" 0;
BA_DEF_DEF_  "GenMsgStartDelayTime" 0;
BA_DEF_DEF_  "GenMsgILSupport" "Yes";
BA_DEF_DEF_  "GenMsgRequestable" 1;
BA_DEF_DEF_  "GenMsgSendType" "noMsgSendType";
BA_DEF_DEF_  "VFrameFormat" "";
BA_DEF_DEF_  "GenMsgCycleTime" 0;
BA_DEF_DEF_  "SystemSignalLongSymbol" "";
BA_ "GenMsgSendType" BO_ 2432498944 0;
BA_ "GenMsgCycleTime" BO_ 2432498944 100;
BA_ "VFrameFormat" BO_ 2432498944 3;
BA_ "VFrameFormat" BO_ 2633825022 3;
BA_ "VFrameFormat" BO_ 2633826046 3;
BA_ "VFrameFormat" BO_ 2566711040 3;
BA_ "VFrameFormat" BO_ 2566749184 3;
BA_ "GenMsgSendType" BO_ 2566715646 0;
BA_ "GenMsgCycleTime" BO_ 2566715646 1000;
BA_ "VFrameFormat" BO_ 2566715646 3;
BA_ "GenMsgSendType" BO_ 2566724606 0;
BA_ "GenMsgCycleTime" BO_ 2566724606 1000;
BA_ "VFrameFormat" BO_ 2566724606 3;
BA_ "GenMsgSendType" BO_ 2566715902 0;
BA_ "GenMsgCycleTime" BO_ 2566715902 1000;
BA_ "VFrameFormat" BO_ 2566715902 3;
BA_ "GenMsgSendType" BO_ 2566724862 0;
BA_ "GenMsgCycleTime" BO_ 2566724862 1000;
BA_ "VFrameFormat" BO_ 2566724862 3;
BA_ "GenMsgSendType" BO_ 2566718464 0;
BA_ "GenMsgCycleTime" BO_ 2566718464 1000;
BA_ "VFrameFormat" BO_ 2566718464 3;
BA_ "GenMsgSendType" BO_ 2566718720 0;
BA_ "GenMsgCycleTime" BO_ 2566718720 1000;
BA_ "VFrameFormat" BO_ 2566718720 3;
BA_ "VFrameFormat" BO_ 2566718976 3;
BA_ "VFrameFormat" BO_ 2560818942 3;
BA_ "VFrameFormat" BO_ 2561212158 3;
BA_ "GenMsgCycleTime" BO_ 2566746366 1000;
BA_ "VFrameFormat" BO_ 2566746366 3;
BA_ "VFrameFormat" BO_ 2566749952 3;
BA_ "GenMsgSendType" BO_ 2566755328 0;
BA_ "GenMsgCycleTime" BO_ 2566755328 100;
BA_ "VFrameFormat" BO_ 2566755328 3;
BA_ "VFrameFormat" BO_ 2566745856 3;
BA_ "GenMsgSendType" BO_ 2566752510 0;
BA_ "GenMsgCycleTime" BO_ 2566752510 500;
BA_ "VFrameFormat" BO_ 2566752510 3;
BA_ "GenMsgSendType" BO_ 2566752254 0;
BA_ "GenMsgCycleTime" BO_ 2566752254 500;
BA_ "VFrameFormat" BO_ 2566752254 3;
BA_ "GenMsgSendType" BO_ 2566751998 0;
BA_ "GenMsgCycleTime" BO_ 2566751998 500;
BA_ "VFrameFormat" BO_ 2566751998 3;
BA_ "GenMsgSendType" BO_ 2566751742 0;
BA_ "GenMsgCycleTime" BO_ 2566751742 500;
BA_ "VFrameFormat" BO_ 2566751742 3;
BA_ "GenMsgSendType" BO_ 2566751486 0;
BA_ "GenMsgCycleTime" BO_ 2566751486 500;
BA_ "VFrameFormat" BO_ 2566751486 3;
BA_ "GenMsgSendType" BO_ 2499641854 0;
BA_ "GenMsgCycleTime" BO_ 2499641854 500;
BA_ "VFrameFormat" BO_ 2499641854 3;
BA_ "VFrameFormat" BO_ 2566748158 3;
BA_ "VFrameFormat" BO_ 2566747902 3;
BA_ "VFrameFormat" BO_ 2566747646 3;
BA_ "VFrameFormat" BO_ 2566747390 3;
BA_ "VFrameFormat" BO_ 2566747134 3;
BA_ "VFrameFormat" BO_ 2566746878 3;
BA_ "VFrameFormat" BO_ 2561277694 3;
BA_ "VFrameFormat" BO_ 2633861886 3;
BA_ "GenMsgSendType" BO_ 2565873150 0;
BA_ "GenMsgCycleTime" BO_ 2565873150 10;
BA_ "VFrameFormat" BO_ 2565873150 3;
BA_ "VFrameFormat" BO_ 2566745854 3;
BA_ "GenMsgSendType" BO_ 2566751230 0;
BA_ "GenMsgCycleTime" BO_ 2566751230 1000;
BA_ "VFrameFormat" BO_ 2566751230 3;
BA_ "GenMsgSendType" BO_ 2566755838 0;
BA_ "GenMsgCycleTime" BO_ 2566755838 1000;
BA_ "VFrameFormat" BO_ 2566755838 3;
BA_ "VFrameFormat" BO_ 2566752766 3;
BA_ "VFrameFormat" BO_ 2633938942 3;
BA_ "VFrameFormat" BO_ 2566799614 3;
BA_ "VFrameFormat" BO_ 2365473278 3;
BA_ "GenMsgSendType" BO_ 2365485822 0;
BA_ "GenMsgCycleTime" BO_ 2365485822 50;
BA_ "VFrameFormat" BO_ 2365485822 3;
BA_ "VFrameFormat" BO_ 2633926654 3;
BA_ "VFrameFormat" BO_ 2633926398 3;
BA_ "VFrameFormat" BO_ 2633926142 3;
BA_ "VFrameFormat" BO_ 2633925886 3;
BA_ "VFrameFormat" BO_ 2633925630 3;
BA_ "VFrameFormat" BO_ 2633925374 3;
BA_ "VFrameFormat" BO_ 2633927422 3;
BA_ "VFrameFormat" BO_ 2633927166 3;
BA_ "VFrameFormat" BO_ 2633926910 3;
BA_ "GenMsgSendType" BO_ 2566768894 0;
BA_ "GenMsgCycleTime" BO_ 2566768894 1000;
BA_ "VFrameFormat" BO_ 2566768894 3;
BA_ "GenMsgSendType" BO_ 2566769406 0;
BA_ "GenMsgCycleTime" BO_ 2566769406 1000;
BA_ "VFrameFormat" BO_ 2566769406 3;
BA_ "VFrameFormat" BO_ 2566839550 3;
BA_ "GenMsgSendType" BO_ 2633934334 0;
BA_ "GenMsgCycleTime" BO_ 2633934334 1000;
BA_ "VFrameFormat" BO_ 2633934334 3;
BA_ "GenMsgSendType" BO_ 2566825726 0;
BA_ "GenMsgCycleTime" BO_ 2566825726 500;
BA_ "VFrameFormat" BO_ 2566825726 3;
BA_ "GenMsgSendType" BO_ 2566770688 0;
BA_ "GenMsgCycleTime" BO_ 2566770688 500;
BA_ "VFrameFormat" BO_ 2566770688 3;
BA_ "GenMsgSendType" BO_ 2566845952 0;
BA_ "GenMsgCycleTime" BO_ 2566845952 500;
BA_ "VFrameFormat" BO_ 2566845952 3;
BA_ "GenMsgSendType" BO_ 2566811134 0;
BA_ "GenMsgCycleTime" BO_ 2566811134 1000;
BA_ "VFrameFormat" BO_ 2566811134 3;
BA_ "GenMsgSendType" BO_ 2298375934 0;
BA_ "GenMsgCycleTime" BO_ 2298375934 20;
BA_ "VFrameFormat" BO_ 2298375934 3;
BA_ "GenMsgSendType" BO_ 2565867774 0;
BA_ "GenMsgCycleTime" BO_ 2565867774 50;
BA_ "VFrameFormat" BO_ 2565867774 3;
BA_ "VFrameFormat" BO_ 2566841854 3;
BA_ "GenMsgSendType" BO_ 2365449982 0;
BA_ "GenMsgCycleTime" BO_ 2365449982 100;
BA_ "VFrameFormat" BO_ 2365449982 3;
BA_ "VFrameFormat" BO_ 2633939198 3;
BA_ "VFrameFormat" BO_ 2633927678 3;
BA_ "VFrameFormat" BO_ 2633925118 3;
BA_ "VFrameFormat" BO_ 2633937662 3;
BA_ "VFrameFormat" BO_ 2566804990 3;
BA_ "VFrameFormat" BO_ 2633936894 3;
BA_ "GenMsgSendType" BO_ 2566757630 0;
BA_ "GenMsgCycleTime" BO_ 2566757630 1000;
BA_ "VFrameFormat" BO_ 2566757630 3;
BA_ "GenMsgSendType" BO_ 2566757886 0;
BA_ "GenMsgCycleTime" BO_ 2566757886 1000;
BA_ "VFrameFormat" BO_ 2566757886 3;
BA_ "GenMsgSendType" BO_ 2566759678 0;
BA_ "GenMsgCycleTime" BO_ 2566759678 100;
BA_ "VFrameFormat" BO_ 2566759678 3;
BA_ "GenMsgSendType" BO_ 2432541438 0;
BA_ "GenMsgCycleTime" BO_ 2432541438 500;
BA_ "VFrameFormat" BO_ 2432541438 3;
BA_ "GenMsgSendType" BO_ 2566760960 0;
BA_ "GenMsgCycleTime" BO_ 2566760960 500;
BA_ "VFrameFormat" BO_ 2566760960 3;
BA_ "GenMsgSendType" BO_ 2432541440 0;
BA_ "GenMsgCycleTime" BO_ 2432541440 100;
BA_ "VFrameFormat" BO_ 2432541440 3;
BA_ "SigType" SG_ 2432498944 CmdedEngFuelInjectionCtrlPress 1;
BA_ "SPN" SG_ 2432498944 CmdedEngFuelInjectionCtrlPress 5314;
BA_ "SigType" SG_ 2432498944 CmdedEngFuelRailPress 1;
BA_ "SPN" SG_ 2432498944 CmdedEngFuelRailPress 5313;
BA_ "SigType" SG_ 2432498944 EngExhstGsRcrculation2Valve2Pos 1;
BA_ "SPN" SG_ 2432498944 EngExhstGsRcrculation2Valve2Pos 5263;
BA_ "SigType" SG_ 2432498944 EngExhstGsRcirculation2ValvePos 1;
BA_ "SPN" SG_ 2432498944 EngExhstGsRcirculation2ValvePos 5262;
BA_ "SigType" SG_ 2633825022 EngExhstGsRcrclation2Valve2Ctrl 1;
BA_ "SPN" SG_ 2633825022 EngExhstGsRcrclation2Valve2Ctrl 5265;
BA_ "SigType" SG_ 2633825022 EngExhstGsRcrculation2ValveCtrl 1;
BA_ "SPN" SG_ 2633825022 EngExhstGsRcrculation2ValveCtrl 5264;
BA_ "SigType" SG_ 2633826046 EGR2CoolerBypassActuatorPos 1;
BA_ "SPN" SG_ 2633826046 EGR2CoolerBypassActuatorPos 5261;
BA_ "SigType" SG_ 2633826046 EngExhstGsRcrcltn2ClrEfficiency 1;
BA_ "SPN" SG_ 2633826046 EngExhstGsRcrcltn2ClrEfficiency 5260;
BA_ "SigType" SG_ 2633826046 EngExhstGsRcrcltn2ClrIntkGsAbsPr 1;
BA_ "SPN" SG_ 2633826046 EngExhstGsRcrcltn2ClrIntkGsAbsPr 5259;
BA_ "SystemSignalLongSymbol" SG_ 2633826046 EngExhstGsRcrcltn2ClrIntkGsAbsPr "EngExhstGsRcrcltn2ClrIntkGsAbsPrss";
BA_ "SigType" SG_ 2633826046 EngExhstGsRcrcltn2ClrIntakeTemp 1;
BA_ "SPN" SG_ 2633826046 EngExhstGsRcrcltn2ClrIntakeTemp 5258;
BA_ "SigType" SG_ 2566711040 EngFrctnPrcntTorqueAtIdlePoint7 1;
BA_ "SPN" SG_ 2566711040 EngFrctnPrcntTorqueAtIdlePoint7 5477;
BA_ "SigType" SG_ 2566711040 EngFrctnPrcntTorqueAtIdlePoint6 1;
BA_ "SPN" SG_ 2566711040 EngFrctnPrcntTorqueAtIdlePoint6 5476;
BA_ "SigType" SG_ 2566711040 EngFrctnPrcntTorqueAtIdlePoint5 1;
BA_ "SPN" SG_ 2566711040 EngFrctnPrcntTorqueAtIdlePoint5 5475;
BA_ "SigType" SG_ 2566711040 EngFrctnPrcntTorqueAtIdlePoint4 1;
BA_ "SPN" SG_ 2566711040 EngFrctnPrcntTorqueAtIdlePoint4 5474;
BA_ "SigType" SG_ 2566711040 EngFrctnPrcntTorqueAtIdlePoint3 1;
BA_ "SPN" SG_ 2566711040 EngFrctnPrcntTorqueAtIdlePoint3 5473;
BA_ "SigType" SG_ 2566711040 EngFrctnPrcntTorqueAtIdlePoint2 1;
BA_ "SPN" SG_ 2566711040 EngFrctnPrcntTorqueAtIdlePoint2 5472;
BA_ "SigType" SG_ 2566711040 EngFrctnPrcntTorqueAtIdlePoint1 1;
BA_ "SPN" SG_ 2566711040 EngFrctnPrcntTorqueAtIdlePoint1 5471;
BA_ "SigType" SG_ 2566749184 DslPrtcltFltrActvRgnrtnFrcdStts 4;
BA_ "SPN" SG_ 2566749184 DslPrtcltFltrActvRgnrtnFrcdStts 4175;
BA_ "SigType" SG_ 2566749184 ExhaustSystemHighTempLampCmd 4;
BA_ "SPN" SG_ 2566749184 ExhaustSystemHighTempLampCmd 3698;
BA_ "SigType" SG_ 2566749184 DslPrtcltFltrAtmtcActvRgnrtnIntt 4;
BA_ "SPN" SG_ 2566749184 DslPrtcltFltrAtmtcActvRgnrtnIntt 3718;
BA_ "SystemSignalLongSymbol" SG_ 2566749184 DslPrtcltFltrAtmtcActvRgnrtnIntt "DslPrtcltFltrAtmtcActvRgnrtnInttnCnfg";
BA_ "SigType" SG_ 2566749184 DslPrtcltFltrActvRgnrtnInhbtdDTV 4;
BA_ "SPN" SG_ 2566749184 DslPrtcltFltrActvRgnrtnInhbtdDTV 3717;
BA_ "SystemSignalLongSymbol" SG_ 2566749184 DslPrtcltFltrActvRgnrtnInhbtdDTV "DslPrtcltFltrActvRgnrtnInhbtdDTVhclSpdBlwAllwd";
BA_ "SigType" SG_ 2566749184 DslPrtcltFltrActvRgnrtnInhbtdDTE 4;
BA_ "SPN" SG_ 2566749184 DslPrtcltFltrActvRgnrtnInhbtdDTE 3716;
BA_ "SystemSignalLongSymbol" SG_ 2566749184 DslPrtcltFltrActvRgnrtnInhbtdDTE "DslPrtcltFltrActvRgnrtnInhbtdDTEngNtWrmdUp";
BA_ "SigType" SG_ 2566749184 DslPrtcltFltrActvRgnrtnInhbtdDTP 4;
BA_ "SPN" SG_ 2566749184 DslPrtcltFltrActvRgnrtnInhbtdDTP 3715;
BA_ "SystemSignalLongSymbol" SG_ 2566749184 DslPrtcltFltrActvRgnrtnInhbtdDTP "DslPrtcltFltrActvRgnrtnInhbtdDTPrmnntSystmLckt";
BA_ "SigType" SG_ 2566749184 DslPrtcltFltrActvRgnrtnInhbtdDTT 4;
BA_ "SPN" SG_ 2566749184 DslPrtcltFltrActvRgnrtnInhbtdDTT 3714;
BA_ "SystemSignalLongSymbol" SG_ 2566749184 DslPrtcltFltrActvRgnrtnInhbtdDTT "DslPrtcltFltrActvRgnrtnInhbtdDTTmprrySystmLckt";
BA_ "SigType" SG_ 2566749184 DslPrtcltFltrActvRgnrtnInhbtdDTS 4;
BA_ "SPN" SG_ 2566749184 DslPrtcltFltrActvRgnrtnInhbtdDTS 3713;
BA_ "SystemSignalLongSymbol" SG_ 2566749184 DslPrtcltFltrActvRgnrtnInhbtdDTS "DslPrtcltFltrActvRgnrtnInhbtdDTSystmTmt";
BA_ "SigType" SG_ 2566749184 DslPrtcltFltrActvRgnrtnInhb_0000 4;
BA_ "SPN" SG_ 2566749184 DslPrtcltFltrActvRgnrtnInhb_0000 3712;
BA_ "SystemSignalLongSymbol" SG_ 2566749184 DslPrtcltFltrActvRgnrtnInhb_0000 "DslPrtcltFltrActvRgnrtnInhbtdDTSystmFltActv";
BA_ "SigType" SG_ 2566749184 DslPrtcltFltrActvRgnrtnInhbtdDTL 4;
BA_ "SPN" SG_ 2566749184 DslPrtcltFltrActvRgnrtnInhbtdDTL 3711;
BA_ "SystemSignalLongSymbol" SG_ 2566749184 DslPrtcltFltrActvRgnrtnInhbtdDTL "DslPrtcltFltrActvRgnrtnInhbtdDTLwExhstGsTmp";
BA_ "SigType" SG_ 2566749184 DslPrtcltFltrActvRgnrtnInhb_0001 4;
BA_ "SPN" SG_ 2566749184 DslPrtcltFltrActvRgnrtnInhb_0001 3710;
BA_ "SystemSignalLongSymbol" SG_ 2566749184 DslPrtcltFltrActvRgnrtnInhb_0001 "DslPrtcltFltrActvRgnrtnInhbtdDTPrkngBrkNtSt";
BA_ "SigType" SG_ 2566749184 DslPrtcltFltrActvRgnrtnInhb_0002 4;
BA_ "SPN" SG_ 2566749184 DslPrtcltFltrActvRgnrtnInhb_0002 3709;
BA_ "SystemSignalLongSymbol" SG_ 2566749184 DslPrtcltFltrActvRgnrtnInhb_0002 "DslPrtcltFltrActvRgnrtnInhbtdDTVhclSpdAbvAllwd";
BA_ "SigType" SG_ 2566749184 DslPrtcltFltrActvRgnrtnInhbtdDTO 4;
BA_ "SPN" SG_ 2566749184 DslPrtcltFltrActvRgnrtnInhbtdDTO 3708;
BA_ "SystemSignalLongSymbol" SG_ 2566749184 DslPrtcltFltrActvRgnrtnInhbtdDTO "DslPrtcltFltrActvRgnrtnInhbtdDTOtOfNtrl";
BA_ "SigType" SG_ 2566749184 DslPrtcltFltrActvRgnrtnInhbtdDTA 4;
BA_ "SPN" SG_ 2566749184 DslPrtcltFltrActvRgnrtnInhbtdDTA 3707;
BA_ "SystemSignalLongSymbol" SG_ 2566749184 DslPrtcltFltrActvRgnrtnInhbtdDTA "DslPrtcltFltrActvRgnrtnInhbtdDTAcclPdlOffIdl";
BA_ "SigType" SG_ 2566749184 DslPrtcltFltrActvRgnrtnInhb_0003 4;
BA_ "SPN" SG_ 2566749184 DslPrtcltFltrActvRgnrtnInhb_0003 3706;
BA_ "SystemSignalLongSymbol" SG_ 2566749184 DslPrtcltFltrActvRgnrtnInhb_0003 "DslPrtcltFltrActvRgnrtnInhbtdDTPTOActv";
BA_ "SigType" SG_ 2566749184 DslPrtcltFltrActvRgnrtnInhb_0004 4;
BA_ "SPN" SG_ 2566749184 DslPrtcltFltrActvRgnrtnInhb_0004 3705;
BA_ "SystemSignalLongSymbol" SG_ 2566749184 DslPrtcltFltrActvRgnrtnInhb_0004 "DslPrtcltFltrActvRgnrtnInhbtdDTSrvcBrkActv";
BA_ "SigType" SG_ 2566749184 DslPrtcltFltrActvRgnrtnInhbtdDTC 4;
BA_ "SPN" SG_ 2566749184 DslPrtcltFltrActvRgnrtnInhbtdDTC 3704;
BA_ "SystemSignalLongSymbol" SG_ 2566749184 DslPrtcltFltrActvRgnrtnInhbtdDTC "DslPrtcltFltrActvRgnrtnInhbtdDTCltchDsnggd";
BA_ "SigType" SG_ 2566749184 DslPrtcltFltrActvRgnrtnInhbtdDTI 4;
BA_ "SPN" SG_ 2566749184 DslPrtcltFltrActvRgnrtnInhbtdDTI 3703;
BA_ "SystemSignalLongSymbol" SG_ 2566749184 DslPrtcltFltrActvRgnrtnInhbtdDTI "DslPrtcltFltrActvRgnrtnInhbtdDTInhbtSwtch";
BA_ "SigType" SG_ 2566749184 DslPrtcltFltrActvRgnrtnInhbtdStt 4;
BA_ "SPN" SG_ 2566749184 DslPrtcltFltrActvRgnrtnInhbtdStt 3702;
BA_ "SystemSignalLongSymbol" SG_ 2566749184 DslPrtcltFltrActvRgnrtnInhbtdStt "DslPrtcltFltrActvRgnrtnInhbtdStts";
BA_ "SigType" SG_ 2566749184 DieselParticulateFilterStatus 4;
BA_ "SPN" SG_ 2566749184 DieselParticulateFilterStatus 3701;
BA_ "SigType" SG_ 2566749184 DslPrtcltFltrActvRgnrtionStatus 4;
BA_ "SPN" SG_ 2566749184 DslPrtcltFltrActvRgnrtionStatus 3700;
BA_ "SigType" SG_ 2566749184 DslPrtcltFltrPssvRgnrtionStatus 4;
BA_ "SPN" SG_ 2566749184 DslPrtcltFltrPssvRgnrtionStatus 3699;
BA_ "SigType" SG_ 2566749184 DieselParticulateFilterLampCmd 4;
BA_ "SPN" SG_ 2566749184 DieselParticulateFilterLampCmd 3697;
BA_ "SigType" SG_ 2566715646 DslPrtclateFilter2SootSignalMin 1;
BA_ "SPN" SG_ 2566715646 DslPrtclateFilter2SootSignalMin 5271;
BA_ "SigType" SG_ 2566715646 DslPrtclateFilter2SootSignalMax 1;
BA_ "SPN" SG_ 2566715646 DslPrtclateFilter2SootSignalMax 5270;
BA_ "SigType" SG_ 2566715646 DslPrtcltFltr2StSgnlStndrdDvton 1;
BA_ "SPN" SG_ 2566715646 DslPrtcltFltr2StSgnlStndrdDvton 5269;
BA_ "SigType" SG_ 2566724606 DslPrtcltFltr2StSnsrPrlmnaryFMI 1;
BA_ "SPN" SG_ 2566724606 DslPrtcltFltr2StSnsrPrlmnaryFMI 4790;
BA_ "SigType" SG_ 2566724606 DslPrtcltFlter2MedianSootSignal 1;
BA_ "SPN" SG_ 2566724606 DslPrtcltFlter2MedianSootSignal 4789;
BA_ "SigType" SG_ 2566724606 DslPrtclteFilter2MeanSootSignal 1;
BA_ "SPN" SG_ 2566724606 DslPrtclteFilter2MeanSootSignal 4788;
BA_ "SigType" SG_ 2566724606 DslPrticulateFilter2SootDensity 1;
BA_ "SPN" SG_ 2566724606 DslPrticulateFilter2SootDensity 4787;
BA_ "SigType" SG_ 2566724606 DeselParticulateFilter2SootMass 1;
BA_ "SPN" SG_ 2566724606 DeselParticulateFilter2SootMass 4786;
BA_ "SigType" SG_ 2566715902 DslPrtclateFilter1SootSignalMin 1;
BA_ "SPN" SG_ 2566715902 DslPrtclateFilter1SootSignalMin 5268;
BA_ "SigType" SG_ 2566715902 DslPrtclateFilter1SootSignalMax 1;
BA_ "SPN" SG_ 2566715902 DslPrtclateFilter1SootSignalMax 5267;
BA_ "SigType" SG_ 2566715902 DslPrtcltFltr1StSgnlStndrdDvton 1;
BA_ "SPN" SG_ 2566715902 DslPrtcltFltr1StSgnlStndrdDvton 5266;
BA_ "SigType" SG_ 2566724862 DslPrtcltFltr1StSnsrPrlmnaryFMI 1;
BA_ "SPN" SG_ 2566724862 DslPrtcltFltr1StSnsrPrlmnaryFMI 4785;
BA_ "SigType" SG_ 2566724862 DslPrtcltFlter1MedianSootSignal 1;
BA_ "SPN" SG_ 2566724862 DslPrtcltFlter1MedianSootSignal 4784;
BA_ "SigType" SG_ 2566724862 DslPrtclteFilter1MeanSootSignal 1;
BA_ "SPN" SG_ 2566724862 DslPrtclteFilter1MeanSootSignal 4783;
BA_ "SigType" SG_ 2566724862 DslPrticulateFilter1SootDensity 1;
BA_ "SPN" SG_ 2566724862 DslPrticulateFilter1SootDensity 4782;
BA_ "SigType" SG_ 2566724862 DeselParticulateFilter1SootMass 1;
BA_ "SPN" SG_ 2566724862 DeselParticulateFilter1SootMass 4781;
BA_ "SigType" SG_ 2566718464 VehicleBatteryChargingLampData 4;
BA_ "SPN" SG_ 2566718464 VehicleBatteryChargingLampData 5108;
BA_ "SigType" SG_ 2566718464 VhicleHVACRecirculationLampData 4;
BA_ "SPN" SG_ 2566718464 VhicleHVACRecirculationLampData 5107;
BA_ "SigType" SG_ 2566718464 VehicleAirPressLowLampData 4;
BA_ "SPN" SG_ 2566718464 VehicleAirPressLowLampData 5106;
BA_ "SigType" SG_ 2566718464 VehicleFuelLevelLowLampData 4;
BA_ "SPN" SG_ 2566718464 VehicleFuelLevelLowLampData 5105;
BA_ "SigType" SG_ 2566718464 VhicleBatteryVoltageLowLampData 4;
BA_ "SPN" SG_ 2566718464 VhicleBatteryVoltageLowLampData 5104;
BA_ "SigType" SG_ 2566718720 EngWaitToStartLampData 4;
BA_ "SPN" SG_ 2566718720 EngWaitToStartLampData 5416;
BA_ "SigType" SG_ 2566718720 EngFuelFilterRestrictedLampData 4;
BA_ "SPN" SG_ 2566718720 EngFuelFilterRestrictedLampData 5470;
BA_ "SigType" SG_ 2566718720 EngAirFilterRestrictionLampData 4;
BA_ "SPN" SG_ 2566718720 EngAirFilterRestrictionLampData 5103;
BA_ "SigType" SG_ 2566718720 EngIdleManagementActiveLampData 4;
BA_ "SPN" SG_ 2566718720 EngIdleManagementActiveLampData 5102;
BA_ "SigType" SG_ 2566718720 EngCoolantLevelLowLampData 4;
BA_ "SPN" SG_ 2566718720 EngCoolantLevelLowLampData 5101;
BA_ "SigType" SG_ 2566718720 EngCoolantTempHighLampData 4;
BA_ "SPN" SG_ 2566718720 EngCoolantTempHighLampData 5100;
BA_ "SigType" SG_ 2566718720 EngOilPressLowLampData 4;
BA_ "SPN" SG_ 2566718720 EngOilPressLowLampData 5099;
BA_ "SigType" SG_ 2566718720 CmprssnBrkEnblSwtchIndctrLmpDta 4;
BA_ "SPN" SG_ 2566718720 CmprssnBrkEnblSwtchIndctrLmpDta 5098;
BA_ "SigType" SG_ 2566718720 EngBrakeActiveLampData 4;
BA_ "SPN" SG_ 2566718720 EngBrakeActiveLampData 5097;
BA_ "SigType" SG_ 2566718720 OBDMalfunctionIndicatorLampData 4;
BA_ "SPN" SG_ 2566718720 OBDMalfunctionIndicatorLampData 5096;
BA_ "SigType" SG_ 2566718720 EngRedStopLampData 4;
BA_ "SPN" SG_ 2566718720 EngRedStopLampData 5095;
BA_ "SigType" SG_ 2566718720 EngAmberWarningLampData 4;
BA_ "SPN" SG_ 2566718720 EngAmberWarningLampData 5094;
BA_ "SigType" SG_ 2566718720 EngProtectLampData 4;
BA_ "SPN" SG_ 2566718720 EngProtectLampData 5093;
BA_ "SigType" SG_ 2566718976 VehicleBatteryChargingLampCmd 4;
BA_ "SPN" SG_ 2566718976 VehicleBatteryChargingLampCmd 5091;
BA_ "SigType" SG_ 2566718976 VehicleHVACRecirculationLampCmd 4;
BA_ "SPN" SG_ 2566718976 VehicleHVACRecirculationLampCmd 5090;
BA_ "SigType" SG_ 2566718976 VehicleAirPressLowLampCmd 4;
BA_ "SPN" SG_ 2566718976 VehicleAirPressLowLampCmd 5089;
BA_ "SigType" SG_ 2566718976 VehicleFuelLevelLowLampCmd 4;
BA_ "SPN" SG_ 2566718976 VehicleFuelLevelLowLampCmd 5088;
BA_ "SigType" SG_ 2566718976 VehicleBatteryVoltageLowLampCmd 4;
BA_ "SPN" SG_ 2566718976 VehicleBatteryVoltageLowLampCmd 5087;
BA_ "SigType" SG_ 2560818942 DTCTimeUntilDerate 1;
BA_ "SPN" SG_ 2560818942 DTCTimeUntilDerate 4123;
BA_ "SigType" SG_ 2560818942 DTCTotalPreviouslyActiveTime 1;
BA_ "SPN" SG_ 2560818942 DTCTotalPreviouslyActiveTime 4122;
BA_ "SigType" SG_ 2560818942 DTCTotalActiveTime 1;
BA_ "SPN" SG_ 2560818942 DTCTotalActiveTime 4121;
BA_ "SPN" SG_ 2560818942 FailureModeIdentifier1 1215;
BA_ "SPN" SG_ 2560818942 SPN1High 1214;
BA_ "SPN" SG_ 2560818942 SPN1 1214;
BA_ "SigType" SG_ 2561212158 TextDisplayIndex 1;
BA_ "SPN" SG_ 2561212158 TextDisplayIndex 3614;
BA_ "SigType" SG_ 2561212158 TextDisplayInstructions 4;
BA_ "SPN" SG_ 2561212158 TextDisplayInstructions 3613;
BA_ "SigType" SG_ 2566746366 RetractStatusOfRamp5 4;
BA_ "SPN" SG_ 2566746366 RetractStatusOfRamp5 4457;
BA_ "SigType" SG_ 2566746366 RetractStatusOfRamp4 4;
BA_ "SPN" SG_ 2566746366 RetractStatusOfRamp4 4454;
BA_ "SigType" SG_ 2566746366 MovementStatusOfRamp5 4;
BA_ "SPN" SG_ 2566746366 MovementStatusOfRamp5 4459;
BA_ "SigType" SG_ 2566746366 MovementStatusOfRamp4 4;
BA_ "SPN" SG_ 2566746366 MovementStatusOfRamp4 4456;
BA_ "SigType" SG_ 2566746366 EnableStatusOfRamp5 4;
BA_ "SPN" SG_ 2566746366 EnableStatusOfRamp5 4458;
BA_ "SigType" SG_ 2566746366 EnableStatusOfRamp4 4;
BA_ "SPN" SG_ 2566746366 EnableStatusOfRamp4 4455;
BA_ "SigType" SG_ 2566746366 MovementStatusOfRamp3 4;
BA_ "SPN" SG_ 2566746366 MovementStatusOfRamp3 3818;
BA_ "SigType" SG_ 2566746366 EnableStatusOfRamp3 4;
BA_ "SPN" SG_ 2566746366 EnableStatusOfRamp3 3817;
BA_ "SigType" SG_ 2566746366 RetractStatusOfRamp3 4;
BA_ "SPN" SG_ 2566746366 RetractStatusOfRamp3 3816;
BA_ "SigType" SG_ 2566746366 MovementStatusOfRamp2 4;
BA_ "SPN" SG_ 2566746366 MovementStatusOfRamp2 3815;
BA_ "SigType" SG_ 2566746366 EnableStatusOfRamp2 4;
BA_ "SPN" SG_ 2566746366 EnableStatusOfRamp2 3814;
BA_ "SigType" SG_ 2566746366 RetractStatusOfRamp2 4;
BA_ "SPN" SG_ 2566746366 RetractStatusOfRamp2 3813;
BA_ "SigType" SG_ 2566746366 MovementStatusOfRamp1 4;
BA_ "SPN" SG_ 2566746366 MovementStatusOfRamp1 3812;
BA_ "SigType" SG_ 2566746366 EnableStatusOfRamp1 4;
BA_ "SPN" SG_ 2566746366 EnableStatusOfRamp1 3811;
BA_ "SigType" SG_ 2566746366 RetractStatusOfRamp1 4;
BA_ "SPN" SG_ 2566746366 RetractStatusOfRamp1 3810;
BA_ "SigType" SG_ 2566749952 MaxCrankAttemptsPerStartAttempt 1;
BA_ "SPN" SG_ 2566749952 MaxCrankAttemptsPerStartAttempt 3670;
BA_ "SigType" SG_ 2566755328 EngExhstGsRcrculation1Valve2Pos 1;
BA_ "SPN" SG_ 2566755328 EngExhstGsRcrculation1Valve2Pos 3822;
BA_ "SigType" SG_ 2566755328 EngExhstGsRcirculation1ValvePos 1;
BA_ "SPN" SG_ 2566755328 EngExhstGsRcirculation1ValvePos 27;
BA_ "SigType" SG_ 2566755328 EngCrnkcsBrthrOilSeparatorSpeed 1;
BA_ "SPN" SG_ 2566755328 EngCrnkcsBrthrOilSeparatorSpeed 5444;
BA_ "SigType" SG_ 2566755328 CmdedEngIntakeManifoldPress 1;
BA_ "SPN" SG_ 2566755328 CmdedEngIntakeManifoldPress 5312;
BA_ "SigType" SG_ 2566745856 EngExhstGsRcrcltn1ClrIntkGsAbsPr 1;
BA_ "SPN" SG_ 2566745856 EngExhstGsRcrcltn1ClrIntkGsAbsPr 4751;
BA_ "SystemSignalLongSymbol" SG_ 2566745856 EngExhstGsRcrcltn1ClrIntkGsAbsPr "EngExhstGsRcrcltn1ClrIntkGsAbsPrss";
BA_ "SigType" SG_ 2566745856 EngExhstGsRcrcltn1ClrIntakeTemp 1;
BA_ "SPN" SG_ 2566745856 EngExhstGsRcrcltn1ClrIntakeTemp 4750;
BA_ "SigType" SG_ 2566745856 EngExhstGsRcrcltn1ClrEfficiency 1;
BA_ "SPN" SG_ 2566745856 EngExhstGsRcrcltn1ClrEfficiency 4752;
BA_ "SigType" SG_ 2566745856 EngExhstGsRcrclation1Valve2Ctrl 1;
BA_ "SPN" SG_ 2566745856 EngExhstGsRcrclation1Valve2Ctrl 3821;
BA_ "SigType" SG_ 2566752510 EngIntkVlvActtonOilPressForCyl4 1;
BA_ "SPN" SG_ 2566752510 EngIntkVlvActtonOilPressForCyl4 3627;
BA_ "SigType" SG_ 2566752510 EngIntkVlvActtonOilPressForCyl3 1;
BA_ "SPN" SG_ 2566752510 EngIntkVlvActtonOilPressForCyl3 3626;
BA_ "SigType" SG_ 2566752510 EngIntkVlvActtonOilPressForCyl2 1;
BA_ "SPN" SG_ 2566752510 EngIntkVlvActtonOilPressForCyl2 3625;
BA_ "SigType" SG_ 2566752510 EngIntkVlvActtonOilPressForCyl1 1;
BA_ "SPN" SG_ 2566752510 EngIntkVlvActtonOilPressForCyl1 3624;
BA_ "SigType" SG_ 2566752254 EngIntkVlvActtonOilPressForCyl8 1;
BA_ "SPN" SG_ 2566752254 EngIntkVlvActtonOilPressForCyl8 3631;
BA_ "SigType" SG_ 2566752254 EngIntkVlvActtonOilPressForCyl7 1;
BA_ "SPN" SG_ 2566752254 EngIntkVlvActtonOilPressForCyl7 3630;
BA_ "SigType" SG_ 2566752254 EngIntkVlvActtonOilPressForCyl6 1;
BA_ "SPN" SG_ 2566752254 EngIntkVlvActtonOilPressForCyl6 3629;
BA_ "SigType" SG_ 2566752254 EngIntkVlvActtonOilPressForCyl5 1;
BA_ "SPN" SG_ 2566752254 EngIntkVlvActtonOilPressForCyl5 3628;
BA_ "SigType" SG_ 2566751998 EngIntkVlvActtnOilPressForCyl12 1;
BA_ "SPN" SG_ 2566751998 EngIntkVlvActtnOilPressForCyl12 3635;
BA_ "SigType" SG_ 2566751998 EngIntkVlvActtnOilPressForCyl11 1;
BA_ "SPN" SG_ 2566751998 EngIntkVlvActtnOilPressForCyl11 3634;
BA_ "SigType" SG_ 2566751998 EngIntkVlvActtnOilPressForCyl10 1;
BA_ "SPN" SG_ 2566751998 EngIntkVlvActtnOilPressForCyl10 3633;
BA_ "SigType" SG_ 2566751998 EngIntkVlvActtonOilPressForCyl9 1;
BA_ "SPN" SG_ 2566751998 EngIntkVlvActtonOilPressForCyl9 3632;
BA_ "SigType" SG_ 2566751742 EngIntkVlvActtnOilPressForCyl16 1;
BA_ "SPN" SG_ 2566751742 EngIntkVlvActtnOilPressForCyl16 3639;
BA_ "SigType" SG_ 2566751742 EngIntkVlvActtnOilPressForCyl15 1;
BA_ "SPN" SG_ 2566751742 EngIntkVlvActtnOilPressForCyl15 3638;
BA_ "SigType" SG_ 2566751742 EngIntkVlvActtnOilPressForCyl14 1;
BA_ "SPN" SG_ 2566751742 EngIntkVlvActtnOilPressForCyl14 3637;
BA_ "SigType" SG_ 2566751742 EngIntkVlvActtnOilPressForCyl13 1;
BA_ "SPN" SG_ 2566751742 EngIntkVlvActtnOilPressForCyl13 3636;
BA_ "SigType" SG_ 2566751486 EngIntkVlvActtnOilPressForCyl20 1;
BA_ "SPN" SG_ 2566751486 EngIntkVlvActtnOilPressForCyl20 3643;
BA_ "SigType" SG_ 2566751486 EngIntkVlvActtnOilPressForCyl19 1;
BA_ "SPN" SG_ 2566751486 EngIntkVlvActtnOilPressForCyl19 3642;
BA_ "SigType" SG_ 2566751486 EngIntkVlvActtnOilPressForCyl18 1;
BA_ "SPN" SG_ 2566751486 EngIntkVlvActtnOilPressForCyl18 3641;
BA_ "SigType" SG_ 2566751486 EngIntkVlvActtnOilPressForCyl17 1;
BA_ "SPN" SG_ 2566751486 EngIntkVlvActtnOilPressForCyl17 3640;
BA_ "SigType" SG_ 2499641854 EGR1CoolerBypassActuatorPostion 1;
BA_ "SPN" SG_ 2499641854 EGR1CoolerBypassActuatorPostion 3672;
BA_ "SigType" SG_ 2566748158 EngSparkPlug4 1;
BA_ "SPN" SG_ 2566748158 EngSparkPlug4 1297;
BA_ "SigType" SG_ 2566748158 EngSparkPlug3 1;
BA_ "SPN" SG_ 2566748158 EngSparkPlug3 1296;
BA_ "SigType" SG_ 2566748158 EngSparkPlug2 1;
BA_ "SPN" SG_ 2566748158 EngSparkPlug2 1295;
BA_ "SigType" SG_ 2566748158 EngSparkPlug1 1;
BA_ "SPN" SG_ 2566748158 EngSparkPlug1 1294;
BA_ "SigType" SG_ 2566747902 EngSparkPlug8 1;
BA_ "SPN" SG_ 2566747902 EngSparkPlug8 1301;
BA_ "SigType" SG_ 2566747902 EngSparkPlug7 1;
BA_ "SPN" SG_ 2566747902 EngSparkPlug7 1300;
BA_ "SigType" SG_ 2566747902 EngSparkPlug6 1;
BA_ "SPN" SG_ 2566747902 EngSparkPlug6 1299;
BA_ "SigType" SG_ 2566747902 EngSparkPlug5 1;
BA_ "SPN" SG_ 2566747902 EngSparkPlug5 1298;
BA_ "SigType" SG_ 2566747646 EngSparkPlug12 1;
BA_ "SPN" SG_ 2566747646 EngSparkPlug12 1305;
BA_ "SigType" SG_ 2566747646 EngSparkPlug11 1;
BA_ "SPN" SG_ 2566747646 EngSparkPlug11 1304;
BA_ "SigType" SG_ 2566747646 EngSparkPlug10 1;
BA_ "SPN" SG_ 2566747646 EngSparkPlug10 1303;
BA_ "SigType" SG_ 2566747646 EngSparkPlug9 1;
BA_ "SPN" SG_ 2566747646 EngSparkPlug9 1302;
BA_ "SigType" SG_ 2566747390 EngSparkPlug16 1;
BA_ "SPN" SG_ 2566747390 EngSparkPlug16 1309;
BA_ "SigType" SG_ 2566747390 EngSparkPlug15 1;
BA_ "SPN" SG_ 2566747390 EngSparkPlug15 1308;
BA_ "SigType" SG_ 2566747390 EngSparkPlug14 1;
BA_ "SPN" SG_ 2566747390 EngSparkPlug14 1307;
BA_ "SigType" SG_ 2566747390 EngSparkPlug13 1;
BA_ "SPN" SG_ 2566747390 EngSparkPlug13 1306;
BA_ "SigType" SG_ 2566747134 EngSparkPlug20 1;
BA_ "SPN" SG_ 2566747134 EngSparkPlug20 1313;
BA_ "SigType" SG_ 2566747134 EngSparkPlug19 1;
BA_ "SPN" SG_ 2566747134 EngSparkPlug19 1312;
BA_ "SigType" SG_ 2566747134 EngSparkPlug18 1;
BA_ "SPN" SG_ 2566747134 EngSparkPlug18 1311;
BA_ "SigType" SG_ 2566747134 EngSparkPlug17 1;
BA_ "SPN" SG_ 2566747134 EngSparkPlug17 1310;
BA_ "SigType" SG_ 2566746878 EngSparkPlug24 1;
BA_ "SPN" SG_ 2566746878 EngSparkPlug24 1317;
BA_ "SigType" SG_ 2566746878 EngSparkPlug23 1;
BA_ "SPN" SG_ 2566746878 EngSparkPlug23 1316;
BA_ "SigType" SG_ 2566746878 EngSparkPlug22 1;
BA_ "SPN" SG_ 2566746878 EngSparkPlug22 1315;
BA_ "SigType" SG_ 2566746878 EngSparkPlug21 1;
BA_ "SPN" SG_ 2566746878 EngSparkPlug21 1314;
BA_ "SigType" SG_ 2561277694 LaneDepartureWarningEnableCmd 4;
BA_ "SPN" SG_ 2561277694 LaneDepartureWarningEnableCmd 3564;
BA_ "SPN" SG_ 2633861886 J2012DTCOccurrenceCount 3622;
BA_ "SPN" SG_ 2633861886 J2012DTCStatus 3621;
BA_ "SigType" SG_ 2633861886 NumberOfJ2012DTCs 1;
BA_ "SPN" SG_ 2633861886 NumberOfJ2012DTCs 3619;
BA_ "SigType" SG_ 2565873150 MessageChecksum 4;
BA_ "SPN" SG_ 2565873150 MessageChecksum 3690;
BA_ "SigType" SG_ 2565873150 MessageCounter 4;
BA_ "SPN" SG_ 2565873150 MessageCounter 3689;
BA_ "SigType" SG_ 2565873150 SteerAngleSensorCalibrated 4;
BA_ "SPN" SG_ 2565873150 SteerAngleSensorCalibrated 3688;
BA_ "SigType" SG_ 2565873150 SteerAngleSensorActiveMode 4;
BA_ "SPN" SG_ 2565873150 SteerAngleSensorActiveMode 3687;
BA_ "SigType" SG_ 2565873150 SteerWheelAngleRange 1;
BA_ "SPN" SG_ 2565873150 SteerWheelAngleRange 3686;
BA_ "SigType" SG_ 2565873150 SteerWheelAngleRangeCounterType 4;
BA_ "SPN" SG_ 2565873150 SteerWheelAngleRangeCounterType 3685;
BA_ "SPN" SG_ 2565873150 SteerWheelAngleRangeCounter 3684;
BA_ "SigType" SG_ 2565873150 SteerWheelAngle 1;
BA_ "SPN" SG_ 2565873150 SteerWheelAngle 3683;
BA_ "SigType" SG_ 2566745854 Aftrtrtmnt1SCRCtlystCnvrsnEffcnc 1;
BA_ "SPN" SG_ 2566745854 Aftrtrtmnt1SCRCtlystCnvrsnEffcnc 4364;
BA_ "SystemSignalLongSymbol" SG_ 2566745854 Aftrtrtmnt1SCRCtlystCnvrsnEffcnc "Aftrtrtmnt1SCRCtlystCnvrsnEffcncy";
BA_ "SigType" SG_ 2566745854 Aftrtrtmnt1SCRCmddCtlystRgntCnsm 1;
BA_ "SPN" SG_ 2566745854 Aftrtrtmnt1SCRCmddCtlystRgntCnsm 3828;
BA_ "SystemSignalLongSymbol" SG_ 2566745854 Aftrtrtmnt1SCRCmddCtlystRgntCnsm "Aftrtrtmnt1SCRCmddCtlystRgntCnsmptn";
BA_ "SigType" SG_ 2566745854 Aftrtrtmnt1SCRAvrgCtlystRgntCnsm 1;
BA_ "SPN" SG_ 2566745854 Aftrtrtmnt1SCRAvrgCtlystRgntCnsm 3826;
BA_ "SystemSignalLongSymbol" SG_ 2566745854 Aftrtrtmnt1SCRAvrgCtlystRgntCnsm "Aftrtrtmnt1SCRAvrgCtlystRgntCnsmptn";
BA_ "SigType" SG_ 2566745854 Aftrtrtmnt1DslExhstFldTnkLwLvlIn 1;
BA_ "SPN" SG_ 2566745854 Aftrtrtmnt1DslExhstFldTnkLwLvlIn 5463;
BA_ "SystemSignalLongSymbol" SG_ 2566745854 Aftrtrtmnt1DslExhstFldTnkLwLvlIn "Aftrtrtmnt1DslExhstFldTnkLwLvlIndctrTrvldDstnc";
BA_ "SPN" SG_ 2566751230 TransferCaseStatus 3645;
BA_ "SigType" SG_ 2566755838 TrnsTrqueConverterOilOutletTemp 1;
BA_ "SPN" SG_ 2566755838 TrnsTrqueConverterOilOutletTemp 3823;
BA_ "SigType" SG_ 2566755838 TransOverheatIndicator 4;
BA_ "SPN" SG_ 2566755838 TransOverheatIndicator 5345;
BA_ "SigType" SG_ 2566755838 TransOilLifeRemaining 1;
BA_ "SPN" SG_ 2566755838 TransOilLifeRemaining 4177;
BA_ "SigType" SG_ 2566755838 TransOilLevelSwitch 4;
BA_ "SPN" SG_ 2566755838 TransOilLevelSwitch 3533;
BA_ "SigType" SG_ 2566755838 TransOilFilterRestrictionSwitch 4;
BA_ "SPN" SG_ 2566755838 TransOilFilterRestrictionSwitch 3359;
BA_ "SigType" SG_ 2566752766 VehicleRoll 1;
BA_ "SPN" SG_ 2566752766 VehicleRoll 3623;
BA_ "SigType" SG_ 2633938942 TotalEngCruiseTime 1;
BA_ "SPN" SG_ 2633938942 TotalEngCruiseTime 1017;
BA_ "SigType" SG_ 2633938942 TotalDriveAverageLoadFactor 1;
BA_ "SPN" SG_ 2633938942 TotalDriveAverageLoadFactor 1016;
BA_ "SigType" SG_ 2633938942 TripDriveAverageLoadFactor 1;
BA_ "SPN" SG_ 2633938942 TripDriveAverageLoadFactor 1015;
BA_ "SigType" SG_ 2633938942 TripAverageEngSpeed 1;
BA_ "SPN" SG_ 2633938942 TripAverageEngSpeed 1014;
BA_ "SigType" SG_ 2633938942 TripMaxEngSpeed 1;
BA_ "SPN" SG_ 2633938942 TripMaxEngSpeed 1013;
BA_ "SigType" SG_ 2566799614 ImplementRearWorkLight 4;
BA_ "SPN" SG_ 2566799614 ImplementRearWorkLight 2394;
BA_ "SigType" SG_ 2566799614 ImplementLeftForwardWorkLight 4;
BA_ "SPN" SG_ 2566799614 ImplementLeftForwardWorkLight 2400;
BA_ "SigType" SG_ 2566799614 ImplementRightForwardWorkLight 4;
BA_ "SPN" SG_ 2566799614 ImplementRightForwardWorkLight 2402;
BA_ "SigType" SG_ 2566799614 ImplementLeftFacingWorkLight 4;
BA_ "SPN" SG_ 2566799614 ImplementLeftFacingWorkLight 2598;
BA_ "SigType" SG_ 2566799614 ImplementRightFacingWorkLight 4;
BA_ "SPN" SG_ 2566799614 ImplementRightFacingWorkLight 2407;
BA_ "SigType" SG_ 2566799614 ImplementOEMOption1Light 4;
BA_ "SPN" SG_ 2566799614 ImplementOEMOption1Light 2396;
BA_ "SigType" SG_ 2566799614 ImplementOEMOption2Light 4;
BA_ "SPN" SG_ 2566799614 ImplementOEMOption2Light 2398;
BA_ "SigType" SG_ 2566799614 TrctrFrontHighMountedWorkLights 4;
BA_ "SPN" SG_ 2566799614 TrctrFrontHighMountedWorkLights 2356;
BA_ "SigType" SG_ 2566799614 TrctorFrontLowMountedWorkLights 4;
BA_ "SPN" SG_ 2566799614 TrctorFrontLowMountedWorkLights 2354;
BA_ "SigType" SG_ 2566799614 TrctorSideHighMountedWorkLights 4;
BA_ "SPN" SG_ 2566799614 TrctorSideHighMountedWorkLights 2366;
BA_ "SigType" SG_ 2566799614 TractorSideLowMountedWorkLights 4;
BA_ "SPN" SG_ 2566799614 TractorSideLowMountedWorkLights 2364;
BA_ "SigType" SG_ 2566799614 TrctorRearHighMountedWorkLights 4;
BA_ "SPN" SG_ 2566799614 TrctorRearHighMountedWorkLights 2362;
BA_ "SigType" SG_ 2566799614 TractorRearLowMountedWorkLights 4;
BA_ "SPN" SG_ 2566799614 TractorRearLowMountedWorkLights 2360;
BA_ "SigType" SG_ 2566799614 TrctrUndersideMountedWorkLights 4;
BA_ "SPN" SG_ 2566799614 TrctrUndersideMountedWorkLights 2358;
BA_ "SigType" SG_ 2566799614 RearFogLights 4;
BA_ "SPN" SG_ 2566799614 RearFogLights 2390;
BA_ "SigType" SG_ 2566799614 TractorMarkerLight 4;
BA_ "SPN" SG_ 2566799614 TractorMarkerLight 2378;
BA_ "SigType" SG_ 2566799614 ImplementMarkerLight 4;
BA_ "SPN" SG_ 2566799614 ImplementMarkerLight 2380;
BA_ "SigType" SG_ 2566799614 TractorClearanceLight 4;
BA_ "SPN" SG_ 2566799614 TractorClearanceLight 2382;
BA_ "SigType" SG_ 2566799614 ImplementClearanceLight 4;
BA_ "SPN" SG_ 2566799614 ImplementClearanceLight 2384;
BA_ "SigType" SG_ 2566799614 LeftStopLight 4;
BA_ "SPN" SG_ 2566799614 LeftStopLight 2372;
BA_ "SigType" SG_ 2566799614 RightStopLight 4;
BA_ "SPN" SG_ 2566799614 RightStopLight 2374;
BA_ "SigType" SG_ 2566799614 CenterStopLight 4;
BA_ "SPN" SG_ 2566799614 CenterStopLight 2376;
BA_ "SigType" SG_ 2566799614 BackUpLightAndAlarmHorn 4;
BA_ "SPN" SG_ 2566799614 BackUpLightAndAlarmHorn 2392;
BA_ "SigType" SG_ 2566799614 LeftTurnSignalLights 4;
BA_ "SPN" SG_ 2566799614 LeftTurnSignalLights 2368;
BA_ "SigType" SG_ 2566799614 RightTurnSignalLights 4;
BA_ "SPN" SG_ 2566799614 RightTurnSignalLights 2370;
BA_ "SigType" SG_ 2566799614 RotatingBeaconLight 4;
BA_ "SPN" SG_ 2566799614 RotatingBeaconLight 2386;
BA_ "SigType" SG_ 2566799614 TractorFrontFogLights 4;
BA_ "SPN" SG_ 2566799614 TractorFrontFogLights 2388;
BA_ "SigType" SG_ 2566799614 HighBeamHeadLightData 4;
BA_ "SPN" SG_ 2566799614 HighBeamHeadLightData 2348;
BA_ "SigType" SG_ 2566799614 LowBeamHeadLightData 4;
BA_ "SPN" SG_ 2566799614 LowBeamHeadLightData 2350;
BA_ "SigType" SG_ 2566799614 AltBeamHeadLightData 4;
BA_ "SPN" SG_ 2566799614 AltBeamHeadLightData 2352;
BA_ "SigType" SG_ 2566799614 RunningLight 4;
BA_ "SPN" SG_ 2566799614 RunningLight 2404;
BA_ "SigType" SG_ 2365473278 ImplementRearWorkLightCmd 4;
BA_ "SPN" SG_ 2365473278 ImplementRearWorkLightCmd 2405;
BA_ "SigType" SG_ 2365473278 ImplmentLeftForwardWorkLightCmd 4;
BA_ "SPN" SG_ 2365473278 ImplmentLeftForwardWorkLightCmd 2399;
BA_ "SigType" SG_ 2365473278 ImplmntRightForwardWorkLightCmd 4;
BA_ "SPN" SG_ 2365473278 ImplmntRightForwardWorkLightCmd 2401;
BA_ "SigType" SG_ 2365473278 LightingDataRqCmd 4;
BA_ "SPN" SG_ 2365473278 LightingDataRqCmd 2393;
BA_ "SigType" SG_ 2365473278 ImplementLeftFacingWorkLightCmd 4;
BA_ "SPN" SG_ 2365473278 ImplementLeftFacingWorkLightCmd 2597;
BA_ "SigType" SG_ 2365473278 ImplmentRightFacingWorkLightCmd 4;
BA_ "SPN" SG_ 2365473278 ImplmentRightFacingWorkLightCmd 2406;
BA_ "SigType" SG_ 2365473278 ImplementOEMOption1LightCmd 4;
BA_ "SPN" SG_ 2365473278 ImplementOEMOption1LightCmd 2395;
BA_ "SigType" SG_ 2365473278 ImplementOEMOption2LightCmd 4;
BA_ "SPN" SG_ 2365473278 ImplementOEMOption2LightCmd 2397;
BA_ "SigType" SG_ 2365473278 TrctrFrntHghMuntedWorkLightsCmd 4;
BA_ "SPN" SG_ 2365473278 TrctrFrntHghMuntedWorkLightsCmd 2355;
BA_ "SigType" SG_ 2365473278 TrctrFrntLwMountedWorkLightsCmd 4;
BA_ "SPN" SG_ 2365473278 TrctrFrntLwMountedWorkLightsCmd 2353;
BA_ "SigType" SG_ 2365473278 TrctrSdHighMountedWorkLightsCmd 4;
BA_ "SPN" SG_ 2365473278 TrctrSdHighMountedWorkLightsCmd 2365;
BA_ "SigType" SG_ 2365473278 TrctrSdeLowMountedWorkLightsCmd 4;
BA_ "SPN" SG_ 2365473278 TrctrSdeLowMountedWorkLightsCmd 2363;
BA_ "SigType" SG_ 2365473278 TrctrRrHighMountedWorkLightsCmd 4;
BA_ "SPN" SG_ 2365473278 TrctrRrHighMountedWorkLightsCmd 2361;
BA_ "SigType" SG_ 2365473278 TrctrRarLowMountedWorkLightsCmd 4;
BA_ "SPN" SG_ 2365473278 TrctrRarLowMountedWorkLightsCmd 2359;
BA_ "SigType" SG_ 2365473278 TrctrUndrsdMountedWorkLightsCmd 4;
BA_ "SPN" SG_ 2365473278 TrctrUndrsdMountedWorkLightsCmd 2357;
BA_ "SigType" SG_ 2365473278 RearFogLightCmd 4;
BA_ "SPN" SG_ 2365473278 RearFogLightCmd 2389;
BA_ "SigType" SG_ 2365473278 TractorMarkerLightCmd 4;
BA_ "SPN" SG_ 2365473278 TractorMarkerLightCmd 2377;
BA_ "SigType" SG_ 2365473278 ImplementMarkerLightCmd 4;
BA_ "SPN" SG_ 2365473278 ImplementMarkerLightCmd 2379;
BA_ "SigType" SG_ 2365473278 TractorClearanceLightCmd 4;
BA_ "SPN" SG_ 2365473278 TractorClearanceLightCmd 2381;
BA_ "SigType" SG_ 2365473278 ImplementClearanceLightCmd 4;
BA_ "SPN" SG_ 2365473278 ImplementClearanceLightCmd 2383;
BA_ "SigType" SG_ 2365473278 LeftStopLightCmd 4;
BA_ "SPN" SG_ 2365473278 LeftStopLightCmd 2371;
BA_ "SigType" SG_ 2365473278 RightStopLightCmd 4;
BA_ "SPN" SG_ 2365473278 RightStopLightCmd 2373;
BA_ "SigType" SG_ 2365473278 CenterStopLightCmd 4;
BA_ "SPN" SG_ 2365473278 CenterStopLightCmd 2375;
BA_ "SigType" SG_ 2365473278 BackUpLightAndAlarmHornCmd 4;
BA_ "SPN" SG_ 2365473278 BackUpLightAndAlarmHornCmd 2391;
BA_ "SigType" SG_ 2365473278 LeftTurnSignalLightsCmd 4;
BA_ "SPN" SG_ 2365473278 LeftTurnSignalLightsCmd 2367;
BA_ "SigType" SG_ 2365473278 RightTurnSignalLightsCmd 4;
BA_ "SPN" SG_ 2365473278 RightTurnSignalLightsCmd 2369;
BA_ "SigType" SG_ 2365473278 RotatingBeaconLightCmd 4;
BA_ "SPN" SG_ 2365473278 RotatingBeaconLightCmd 2385;
BA_ "SigType" SG_ 2365473278 TractorFrontFogLightsCmd 4;
BA_ "SPN" SG_ 2365473278 TractorFrontFogLightsCmd 2387;
BA_ "SigType" SG_ 2365473278 HighBeamHeadLightCmd 4;
BA_ "SPN" SG_ 2365473278 HighBeamHeadLightCmd 2347;
BA_ "SigType" SG_ 2365473278 LowBeamHeadLightCmd 4;
BA_ "SPN" SG_ 2365473278 LowBeamHeadLightCmd 2349;
BA_ "SigType" SG_ 2365473278 AltBeamHeadLightCmd 4;
BA_ "SPN" SG_ 2365473278 AltBeamHeadLightCmd 2351;
BA_ "SigType" SG_ 2365473278 RunningLightCmd 4;
BA_ "SPN" SG_ 2365473278 RunningLightCmd 2403;
BA_ "SigType" SG_ 2365485822 BladeCtrlMode 1;
BA_ "SPN" SG_ 2365485822 BladeCtrlMode 1578;
BA_ "SigType" SG_ 2365485822 BladeDurationAndDirection 1;
BA_ "SPN" SG_ 2365485822 BladeDurationAndDirection 1577;
BA_ "SigType" SG_ 2365485822 LandLevelingSystemEnableStatus 4;
BA_ "SPN" SG_ 2365485822 LandLevelingSystemEnableStatus 5409;
BA_ "SigType" SG_ 2365485822 BladeCtrlModeRight 4;
BA_ "SPN" SG_ 2365485822 BladeCtrlModeRight 5408;
BA_ "SigType" SG_ 2365485822 BladeCtrlModeLeft 4;
BA_ "SPN" SG_ 2365485822 BladeCtrlModeLeft 5407;
BA_ "SigType" SG_ 2633926654 EngActualIgntTiming 1;
BA_ "SPN" SG_ 2633926654 EngActualIgntTiming 1436;
BA_ "SigType" SG_ 2633926654 EngDesiredIgntTiming3 1;
BA_ "SPN" SG_ 2633926654 EngDesiredIgntTiming3 1435;
BA_ "SigType" SG_ 2633926654 EngDesiredIgntTiming2 1;
BA_ "SPN" SG_ 2633926654 EngDesiredIgntTiming2 1434;
BA_ "SigType" SG_ 2633926654 EngDesiredIgntTiming1 1;
BA_ "SPN" SG_ 2633926654 EngDesiredIgntTiming1 1433;
BA_ "SigType" SG_ 2633926398 EngCyl20IgntTiming 1;
BA_ "SPN" SG_ 2633926398 EngCyl20IgntTiming 1432;
BA_ "SigType" SG_ 2633926398 EngCyl19IgntTiming 1;
BA_ "SPN" SG_ 2633926398 EngCyl19IgntTiming 1431;
BA_ "SigType" SG_ 2633926398 EngCyl18IgntTiming 1;
BA_ "SPN" SG_ 2633926398 EngCyl18IgntTiming 1430;
BA_ "SigType" SG_ 2633926398 EngCyl17IgntTiming 1;
BA_ "SPN" SG_ 2633926398 EngCyl17IgntTiming 1429;
BA_ "SigType" SG_ 2633926142 EngCyl16IgntTiming 1;
BA_ "SPN" SG_ 2633926142 EngCyl16IgntTiming 1428;
BA_ "SigType" SG_ 2633926142 EngCyl15IgntTiming 1;
BA_ "SPN" SG_ 2633926142 EngCyl15IgntTiming 1427;
BA_ "SigType" SG_ 2633926142 EngCyl14IgntTiming 1;
BA_ "SPN" SG_ 2633926142 EngCyl14IgntTiming 1426;
BA_ "SigType" SG_ 2633926142 EngCyl13IgntTiming 1;
BA_ "SPN" SG_ 2633926142 EngCyl13IgntTiming 1425;
BA_ "SigType" SG_ 2633925886 EngCyl12IgntTiming 1;
BA_ "SPN" SG_ 2633925886 EngCyl12IgntTiming 1424;
BA_ "SigType" SG_ 2633925886 EngCyl11IgntTiming 1;
BA_ "SPN" SG_ 2633925886 EngCyl11IgntTiming 1423;
BA_ "SigType" SG_ 2633925886 EngCyl10IgntTiming 1;
BA_ "SPN" SG_ 2633925886 EngCyl10IgntTiming 1422;
BA_ "SigType" SG_ 2633925886 EngCyl9IgntTiming 1;
BA_ "SPN" SG_ 2633925886 EngCyl9IgntTiming 1421;
BA_ "SigType" SG_ 2633925630 EngCyl8IgntTiming 1;
BA_ "SPN" SG_ 2633925630 EngCyl8IgntTiming 1420;
BA_ "SigType" SG_ 2633925630 EngCyl7IgntTiming 1;
BA_ "SPN" SG_ 2633925630 EngCyl7IgntTiming 1419;
BA_ "SigType" SG_ 2633925630 EngCyl6IgntTiming 1;
BA_ "SPN" SG_ 2633925630 EngCyl6IgntTiming 1418;
BA_ "SigType" SG_ 2633925630 EngCyl5IgntTiming 1;
BA_ "SPN" SG_ 2633925630 EngCyl5IgntTiming 1417;
BA_ "SigType" SG_ 2633925374 EngCyl4IgntTiming 1;
BA_ "SPN" SG_ 2633925374 EngCyl4IgntTiming 1416;
BA_ "SigType" SG_ 2633925374 EngCyl3IgntTiming 1;
BA_ "SPN" SG_ 2633925374 EngCyl3IgntTiming 1415;
BA_ "SigType" SG_ 2633925374 EngCyl2IgntTiming 1;
BA_ "SPN" SG_ 2633925374 EngCyl2IgntTiming 1414;
BA_ "SigType" SG_ 2633925374 EngCyl1IgntTiming 1;
BA_ "SPN" SG_ 2633925374 EngCyl1IgntTiming 1413;
BA_ "SigType" SG_ 2633927422 EngCyl20IgntTransSecondOutput 1;
BA_ "SPN" SG_ 2633927422 EngCyl20IgntTransSecondOutput 1412;
BA_ "SigType" SG_ 2633927422 EngCyl19IgntTransSecondOutput 1;
BA_ "SPN" SG_ 2633927422 EngCyl19IgntTransSecondOutput 1411;
BA_ "SigType" SG_ 2633927422 EngCyl18IgntTransSecondOutput 1;
BA_ "SPN" SG_ 2633927422 EngCyl18IgntTransSecondOutput 1410;
BA_ "SigType" SG_ 2633927422 EngCyl17IgntTransSecondOutput 1;
BA_ "SPN" SG_ 2633927422 EngCyl17IgntTransSecondOutput 1409;
BA_ "SigType" SG_ 2633927166 EngCyl16IgntTransSecondOutput 1;
BA_ "SPN" SG_ 2633927166 EngCyl16IgntTransSecondOutput 1408;
BA_ "SigType" SG_ 2633927166 EngCyl15IgntTransSecondOutput 1;
BA_ "SPN" SG_ 2633927166 EngCyl15IgntTransSecondOutput 1407;
BA_ "SigType" SG_ 2633927166 EngCyl14IgntTransSecondOutput 1;
BA_ "SPN" SG_ 2633927166 EngCyl14IgntTransSecondOutput 1406;
BA_ "SigType" SG_ 2633927166 EngCyl13IgntTransSecondOutput 1;
BA_ "SPN" SG_ 2633927166 EngCyl13IgntTransSecondOutput 1405;
BA_ "SigType" SG_ 2633927166 EngCyl12IgntTransSecondOutput 1;
BA_ "SPN" SG_ 2633927166 EngCyl12IgntTransSecondOutput 1404;
BA_ "SigType" SG_ 2633927166 EngCyl11IgntTransSecondOutput 1;
BA_ "SPN" SG_ 2633927166 EngCyl11IgntTransSecondOutput 1403;
BA_ "SigType" SG_ 2633927166 EngCyl10IgntTransSecondOutput 1;
BA_ "SPN" SG_ 2633927166 EngCyl10IgntTransSecondOutput 1402;
BA_ "SigType" SG_ 2633927166 EngCyl9IgntTransSecondOutput 1;
BA_ "SPN" SG_ 2633927166 EngCyl9IgntTransSecondOutput 1401;
BA_ "SigType" SG_ 2633926910 EngCyl8IgntTransSecondOutput 1;
BA_ "SPN" SG_ 2633926910 EngCyl8IgntTransSecondOutput 1400;
BA_ "SigType" SG_ 2633926910 EngCyl7IgntTransSecondOutput 1;
BA_ "SPN" SG_ 2633926910 EngCyl7IgntTransSecondOutput 1399;
BA_ "SigType" SG_ 2633926910 EngCyl6IgntTransSecondOutput 1;
BA_ "SPN" SG_ 2633926910 EngCyl6IgntTransSecondOutput 1398;
BA_ "SigType" SG_ 2633926910 EngCyl5IgntTransSecondOutput 1;
BA_ "SPN" SG_ 2633926910 EngCyl5IgntTransSecondOutput 1397;
BA_ "SigType" SG_ 2633926910 EngCyl4IgntTransSecondOutput 1;
BA_ "SPN" SG_ 2633926910 EngCyl4IgntTransSecondOutput 1396;
BA_ "SigType" SG_ 2633926910 EngCyl3IgntTransSecondOutput 1;
BA_ "SPN" SG_ 2633926910 EngCyl3IgntTransSecondOutput 1395;
BA_ "SigType" SG_ 2633926910 EngCyl2IgntTransSecondOutput 1;
BA_ "SPN" SG_ 2633926910 EngCyl2IgntTransSecondOutput 1394;
BA_ "SigType" SG_ 2633926910 EngCyl1IgntTransSecondOutput 1;
BA_ "SPN" SG_ 2633926910 EngCyl1IgntTransSecondOutput 1393;
BA_ "SigType" SG_ 2566768894 EngOprtrPrmryIntrmdtSpdSlctStte 4;
BA_ "SPN" SG_ 2566768894 EngOprtrPrmryIntrmdtSpdSlctStte 2892;
BA_ "SigType" SG_ 2566769406 EngOprtrPrmryIntrmdtSpeedSelect 4;
BA_ "SPN" SG_ 2566769406 EngOprtrPrmryIntrmdtSpeedSelect 2880;
BA_ "SigType" SG_ 2566839550 EngTotalIdleHours 1;
BA_ "SPN" SG_ 2566839550 EngTotalIdleHours 235;
BA_ "SigType" SG_ 2566839550 EngTotalIdleFuelUsed 1;
BA_ "SPN" SG_ 2566839550 EngTotalIdleFuelUsed 236;
BA_ "SigType" SG_ 2633934334 EngIntakeManifold6Temp 1;
BA_ "SPN" SG_ 2633934334 EngIntakeManifold6Temp 1803;
BA_ "SigType" SG_ 2633934334 EngIntakeManifold5Temp 1;
BA_ "SPN" SG_ 2633934334 EngIntakeManifold5Temp 1802;
BA_ "SigType" SG_ 2633934334 EngIntakeManifold4Temp 1;
BA_ "SPN" SG_ 2633934334 EngIntakeManifold4Temp 1133;
BA_ "SigType" SG_ 2633934334 EngIntakeManifold3Temp 1;
BA_ "SPN" SG_ 2633934334 EngIntakeManifold3Temp 1132;
BA_ "SigType" SG_ 2633934334 EngIntakeManifold2Temp 1;
BA_ "SPN" SG_ 2633934334 EngIntakeManifold2Temp 1131;
BA_ "SigType" SG_ 2566825726 EngTurbo4BoostPress 1;
BA_ "SPN" SG_ 2566825726 EngTurbo4BoostPress 1130;
BA_ "SigType" SG_ 2566825726 EngTurbo3BoostPress 1;
BA_ "SPN" SG_ 2566825726 EngTurbo3BoostPress 1129;
BA_ "SigType" SG_ 2566825726 EngTurbo2BoostPress 1;
BA_ "SPN" SG_ 2566825726 EngTurbo2BoostPress 1128;
BA_ "SigType" SG_ 2566825726 EngTurbo1BoostPress 1;
BA_ "SPN" SG_ 2566825726 EngTurbo1BoostPress 1127;
BA_ "SigType" SG_ 2566770688 EngAirFilter4DiffPress 1;
BA_ "SPN" SG_ 2566770688 EngAirFilter4DiffPress 2811;
BA_ "SigType" SG_ 2566770688 EngAirFilter3DiffPress 1;
BA_ "SPN" SG_ 2566770688 EngAirFilter3DiffPress 2810;
BA_ "SigType" SG_ 2566770688 EngAirFilter2DiffPress 1;
BA_ "SPN" SG_ 2566770688 EngAirFilter2DiffPress 2809;
BA_ "SigType" SG_ 2566770688 EngIntakeManifold1AbsPress 1;
BA_ "SPN" SG_ 2566770688 EngIntakeManifold1AbsPress 4817;
BA_ "SigType" SG_ 2566770688 EngIntakeManifold2AbsPress 1;
BA_ "SPN" SG_ 2566770688 EngIntakeManifold2AbsPress 5422;
BA_ "SigType" SG_ 2566770688 EngIntakeManifold2Press 1;
BA_ "SPN" SG_ 2566770688 EngIntakeManifold2Press 3562;
BA_ "SigType" SG_ 2566770688 EngIntakeManifold1AbsPressHiRes 1;
BA_ "SPN" SG_ 2566770688 EngIntakeManifold1AbsPressHiRes 4817;
BA_ "SigType" SG_ 2566845952 EngCoolantFilterDiffPress 1;
BA_ "SPN" SG_ 2566845952 EngCoolantFilterDiffPress 112;
BA_ "SigType" SG_ 2566845952 EngExhaustGasTemp 1;
BA_ "SPN" SG_ 2566845952 EngExhaustGasTemp 173;
BA_ "SigType" SG_ 2566845952 EngAirFilter1DiffPress 1;
BA_ "SPN" SG_ 2566845952 EngAirFilter1DiffPress 107;
BA_ "SigType" SG_ 2566845952 EngIntakeManifold1Temp 1;
BA_ "SPN" SG_ 2566845952 EngIntakeManifold1Temp 105;
BA_ "SigType" SG_ 2566845952 EngIntakeManifold1Press 1;
BA_ "SPN" SG_ 2566845952 EngIntakeManifold1Press 102;
BA_ "SigType" SG_ 2566845952 EngDslPrtclateFilterIntakePress 1;
BA_ "SPN" SG_ 2566845952 EngDslPrtclateFilterIntakePress 81;
BA_ "SigType" SG_ 2566845952 EngAirIntakePress 1;
BA_ "SPN" SG_ 2566845952 EngAirIntakePress 106;
BA_ "SigType" SG_ 2566811134 CabHeatingZone 4;
BA_ "SPN" SG_ 2566811134 CabHeatingZone 1680;
BA_ "SigType" SG_ 2566811134 EngHeatingZone 4;
BA_ "SPN" SG_ 2566811134 EngHeatingZone 1679;
BA_ "SigType" SG_ 2566811134 CabVentilation 4;
BA_ "SPN" SG_ 2566811134 CabVentilation 1678;
BA_ "SigType" SG_ 2566811134 AuxHeaterMode 4;
BA_ "SPN" SG_ 2566811134 AuxHeaterMode 1677;
BA_ "SigType" SG_ 2566811134 AuxHeaterOutputPowerPercent 1;
BA_ "SPN" SG_ 2566811134 AuxHeaterOutputPowerPercent 1689;
BA_ "SigType" SG_ 2566811134 AuxHeaterInputAirTemp 1;
BA_ "SPN" SG_ 2566811134 AuxHeaterInputAirTemp 1688;
BA_ "SigType" SG_ 2566811134 AuxHeaterOutputCoolantTemp 1;
BA_ "SPN" SG_ 2566811134 AuxHeaterOutputCoolantTemp 1687;
BA_ "SigType" SG_ 2566811134 AuxHeaterWaterPumpStatus 4;
BA_ "SPN" SG_ 2566811134 AuxHeaterWaterPumpStatus 1676;
BA_ "SigType" SG_ 2298375934 RearAxleRightWheelSpeed 1;
BA_ "SPN" SG_ 2298375934 RearAxleRightWheelSpeed 1595;
BA_ "SigType" SG_ 2298375934 RearAxleLeftWheelSpeed 1;
BA_ "SPN" SG_ 2298375934 RearAxleLeftWheelSpeed 1594;
BA_ "SigType" SG_ 2298375934 FrontAxleRightWheelSpeed 1;
BA_ "SPN" SG_ 2298375934 FrontAxleRightWheelSpeed 1593;
BA_ "SigType" SG_ 2298375934 FrontAxleLeftWheelSpeed 1;
BA_ "SPN" SG_ 2298375934 FrontAxleLeftWheelSpeed 1592;
BA_ "SigType" SG_ 2565867774 FireApparatusPumpEngagement 4;
BA_ "SPN" SG_ 2565867774 FireApparatusPumpEngagement 2599;
BA_ "SigType" SG_ 2565867774 EngHydPressGovernorSwitch 4;
BA_ "SPN" SG_ 2565867774 EngHydPressGovernorSwitch 1764;
BA_ "SigType" SG_ 2565867774 EngHydPrssGovernorModeIndicator 4;
BA_ "SPN" SG_ 2565867774 EngHydPrssGovernorModeIndicator 1763;
BA_ "SigType" SG_ 2565867774 HydPress 1;
BA_ "SPN" SG_ 2565867774 HydPress 1762;
BA_ "SigType" SG_ 2566841854 EngTotalRevolutions 1;
BA_ "SPN" SG_ 2566841854 EngTotalRevolutions 249;
BA_ "SigType" SG_ 2566841854 EngTotalHoursOfOperation 1;
BA_ "SPN" SG_ 2566841854 EngTotalHoursOfOperation 247;
BA_ "SigType" SG_ 2365449982 HydBrakeFluidLevelSwitch 4;
BA_ "SPN" SG_ 2365449982 HydBrakeFluidLevelSwitch 2931;
BA_ "SigType" SG_ 2365449982 HydBrakeSystemAudibleWarningCmd 4;
BA_ "SPN" SG_ 2365449982 HydBrakeSystemAudibleWarningCmd 2930;
BA_ "SigType" SG_ 2365449982 HydBrkePressSupplyStateCircuit2 4;
BA_ "SPN" SG_ 2365449982 HydBrkePressSupplyStateCircuit2 2583;
BA_ "SigType" SG_ 2365449982 HydBrkePressSupplyStateCircuit1 4;
BA_ "SPN" SG_ 2365449982 HydBrkePressSupplyStateCircuit1 2582;
BA_ "SigType" SG_ 2365449982 HydBrkPressWarningStateCircuit2 4;
BA_ "SPN" SG_ 2365449982 HydBrkPressWarningStateCircuit2 2585;
BA_ "SigType" SG_ 2365449982 HydBrkPressWarningStateCircuit1 4;
BA_ "SPN" SG_ 2365449982 HydBrkPressWarningStateCircuit1 2584;
BA_ "SigType" SG_ 2365449982 HydBrakePressCircuit2 1;
BA_ "SPN" SG_ 2365449982 HydBrakePressCircuit2 2581;
BA_ "SigType" SG_ 2365449982 HydBrakePressCircuit1 1;
BA_ "SPN" SG_ 2365449982 HydBrakePressCircuit1 2580;
BA_ "SigType" SG_ 2633939198 TripDriveFuelEconomy 1;
BA_ "SPN" SG_ 2633939198 TripDriveFuelEconomy 1012;
BA_ "SigType" SG_ 2633939198 TrpPTOGovernorNonmovingFuelUsed 1;
BA_ "SPN" SG_ 2633939198 TrpPTOGovernorNonmovingFuelUsed 1009;
BA_ "SigType" SG_ 2633939198 TripVehicleIdleFuelUsed 1;
BA_ "SPN" SG_ 2633939198 TripVehicleIdleFuelUsed 1010;
BA_ "SigType" SG_ 2633939198 TripCruiseFuelUsed 1;
BA_ "SPN" SG_ 2633939198 TripCruiseFuelUsed 1011;
BA_ "SigType" SG_ 2633939198 TripDriveFuelUsed 1;
BA_ "SPN" SG_ 2633939198 TripDriveFuelUsed 1007;
BA_ "SigType" SG_ 2633939198 TripPTOGovernorMovingFuelUsed 1;
BA_ "SPN" SG_ 2633939198 TripPTOGovernorMovingFuelUsed 1008;
BA_ "SigType" SG_ 2633927678 EngFuelValve1OutletAbsPress 1;
BA_ "SPN" SG_ 2633927678 EngFuelValve1OutletAbsPress 2980;
BA_ "SigType" SG_ 2633927678 EngAirToFuelDiffPress 1;
BA_ "SPN" SG_ 2633927678 EngAirToFuelDiffPress 1392;
BA_ "SigType" SG_ 2633927678 EngFuelValveDiffPress 1;
BA_ "SPN" SG_ 2633927678 EngFuelValveDiffPress 1391;
BA_ "SigType" SG_ 2633927678 EngFuelValve1IntakeAbsPress 1;
BA_ "SPN" SG_ 2633927678 EngFuelValve1IntakeAbsPress 1390;
BA_ "SigType" SG_ 2633925118 EngFuelFlowRate2 1;
BA_ "SPN" SG_ 2633925118 EngFuelFlowRate2 1441;
BA_ "SigType" SG_ 2633925118 EngFuelFlowRate1 1;
BA_ "SPN" SG_ 2633925118 EngFuelFlowRate1 1440;
BA_ "SigType" SG_ 2633925118 EngRqedFuelValve2Pos 1;
BA_ "SPN" SG_ 2633925118 EngRqedFuelValve2Pos 1766;
BA_ "SigType" SG_ 2633925118 EngRqedFuelValve1Pos 1;
BA_ "SPN" SG_ 2633925118 EngRqedFuelValve1Pos 1765;
BA_ "SigType" SG_ 2633925118 EngFuelValve2Pos 1;
BA_ "SPN" SG_ 2633925118 EngFuelValve2Pos 1443;
BA_ "SigType" SG_ 2633925118 EngFuelValve1Pos 1;
BA_ "SPN" SG_ 2633925118 EngFuelValve1Pos 1442;
BA_ "SigType" SG_ 2633937662 TotalEngPTOGovernorFuelUsed 1;
BA_ "SPN" SG_ 2633937662 TotalEngPTOGovernorFuelUsed 1030;
BA_ "SigType" SG_ 2633937662 TripAverageFuelRate 1;
BA_ "SPN" SG_ 2633937662 TripAverageFuelRate 1031;
BA_ "SigType" SG_ 2633937662 EngFuelSpecificGravity 1;
BA_ "SPN" SG_ 2633937662 EngFuelSpecificGravity 1389;
BA_ "SigType" SG_ 2566804990 SpecificHeatRatio 1;
BA_ "SPN" SG_ 2566804990 SpecificHeatRatio 1767;
BA_ "SigType" SG_ 2633936894 TotalFuelUsed 1;
BA_ "SPN" SG_ 2633936894 TotalFuelUsed 1040;
BA_ "SigType" SG_ 2633936894 TripFuel 1;
BA_ "SPN" SG_ 2633936894 TripFuel 1039;
BA_ "SigType" SG_ 2566757630 SensorSupplyVoltage6 1;
BA_ "SPN" SG_ 2566757630 SensorSupplyVoltage6 3514;
BA_ "SigType" SG_ 2566757630 SensorSupplyVoltage5 1;
BA_ "SPN" SG_ 2566757630 SensorSupplyVoltage5 3513;
BA_ "SigType" SG_ 2566757630 SensorSupplyVoltage8 1;
BA_ "SPN" SG_ 2566757630 SensorSupplyVoltage8 5126;
BA_ "SigType" SG_ 2566757630 SensorSupplyVoltage7 1;
BA_ "SPN" SG_ 2566757630 SensorSupplyVoltage7 5125;
BA_ "SigType" SG_ 2566757886 SensorSupplyVoltage4 1;
BA_ "SPN" SG_ 2566757886 SensorSupplyVoltage4 3512;
BA_ "SigType" SG_ 2566757886 SensorSupplyVoltage3 1;
BA_ "SPN" SG_ 2566757886 SensorSupplyVoltage3 3511;
BA_ "SigType" SG_ 2566757886 SensorSupplyVoltage2 1;
BA_ "SPN" SG_ 2566757886 SensorSupplyVoltage2 3510;
BA_ "SigType" SG_ 2566757886 SensorSupplyVoltage1 1;
BA_ "SPN" SG_ 2566757886 SensorSupplyVoltage1 3509;
BA_ "SigType" SG_ 2566759678 EnggmntSttusTransInputShaftPTO1 4;
BA_ "SPN" SG_ 2566759678 EnggmntSttusTransInputShaftPTO1 3460;
BA_ "SigType" SG_ 2566759678 EnggmntSttusTransInputShaftPTO2 4;
BA_ "SPN" SG_ 2566759678 EnggmntSttusTransInputShaftPTO2 3461;
BA_ "SigType" SG_ 2566759678 EnggmntSttusTransOutputShaftPTO 4;
BA_ "SPN" SG_ 2566759678 EnggmntSttusTransOutputShaftPTO 3462;
BA_ "SigType" SG_ 2566759678 EnggmntSttsTrnsfrCsOtptShaftPTO 4;
BA_ "SPN" SG_ 2566759678 EnggmntSttsTrnsfrCsOtptShaftPTO 3463;
BA_ "SigType" SG_ 2566759678 EnggmntCnsntTransInputShaftPTO1 4;
BA_ "SPN" SG_ 2566759678 EnggmntCnsntTransInputShaftPTO1 3456;
BA_ "SigType" SG_ 2566759678 EnggmntCnsntTransInputShaftPTO2 4;
BA_ "SPN" SG_ 2566759678 EnggmntCnsntTransInputShaftPTO2 3457;
BA_ "SigType" SG_ 2566759678 EnggmntCnsntTransOutputShaftPTO 4;
BA_ "SPN" SG_ 2566759678 EnggmntCnsntTransOutputShaftPTO 3458;
BA_ "SigType" SG_ 2566759678 EnggmntCnsntTrnsfrCsOtptShftPTO 4;
BA_ "SPN" SG_ 2566759678 EnggmntCnsntTrnsfrCsOtptShftPTO 3459;
BA_ "SigType" SG_ 2566759678 EnableSwitchTransInputShaftPTO1 4;
BA_ "SPN" SG_ 2566759678 EnableSwitchTransInputShaftPTO1 3452;
BA_ "SigType" SG_ 2566759678 EnableSwitchTransInputShaftPTO2 4;
BA_ "SPN" SG_ 2566759678 EnableSwitchTransInputShaftPTO2 3453;
BA_ "SigType" SG_ 2566759678 EnableSwitchTransOutputShaftPTO 4;
BA_ "SPN" SG_ 2566759678 EnableSwitchTransOutputShaftPTO 3454;
BA_ "SigType" SG_ 2566759678 EnblSwtchTrnsfrCsOutputShaftPTO 4;
BA_ "SPN" SG_ 2566759678 EnblSwtchTrnsfrCsOutputShaftPTO 3455;
BA_ "SigType" SG_ 2566759678 EnggmntSttsPTOEngAccssoryDrive2 4;
BA_ "SPN" SG_ 2566759678 EnggmntSttsPTOEngAccssoryDrive2 3947;
BA_ "SigType" SG_ 2566759678 EnggmntSttsPTOEngAccssoryDrive1 4;
BA_ "SPN" SG_ 2566759678 EnggmntSttsPTOEngAccssoryDrive1 3944;
BA_ "SigType" SG_ 2566759678 EnggmntCnsntPTOEngAccssryDrive2 4;
BA_ "SPN" SG_ 2566759678 EnggmntCnsntPTOEngAccssryDrive2 3946;
BA_ "SigType" SG_ 2566759678 EnggmntCnsntPTOEngAccssryDrive1 4;
BA_ "SPN" SG_ 2566759678 EnggmntCnsntPTOEngAccssryDrive1 3943;
BA_ "SigType" SG_ 2566759678 EngagementStatusPTOEngFlywheel 4;
BA_ "SPN" SG_ 2566759678 EngagementStatusPTOEngFlywheel 3941;
BA_ "SigType" SG_ 2566759678 EngagementConsentPTOEngFlywheel 4;
BA_ "SPN" SG_ 2566759678 EngagementConsentPTOEngFlywheel 3940;
BA_ "SigType" SG_ 2566759678 EnblSwitchPTOEngAccessoryDrive2 4;
BA_ "SPN" SG_ 2566759678 EnblSwitchPTOEngAccessoryDrive2 3945;
BA_ "SigType" SG_ 2566759678 EnblSwitchPTOEngAccessoryDrive1 4;
BA_ "SPN" SG_ 2566759678 EnblSwitchPTOEngAccessoryDrive1 3942;
BA_ "SigType" SG_ 2566759678 EnableSwitchPTOEngFlywheel 4;
BA_ "SPN" SG_ 2566759678 EnableSwitchPTOEngFlywheel 3939;
BA_ "SigType" SG_ 2566759678 AtLeastOnePTOEngaged 4;
BA_ "SPN" SG_ 2566759678 AtLeastOnePTOEngaged 3948;
BA_ "SigType" SG_ 2432541438 EngFuelValve2OutletAbsPress 1;
BA_ "SPN" SG_ 2432541438 EngFuelValve2OutletAbsPress 3469;
BA_ "SigType" SG_ 2432541438 EngFuelTemp2 1;
BA_ "SPN" SG_ 2432541438 EngFuelTemp2 3468;
BA_ "SigType" SG_ 2432541438 EngGas2MassFlowRate 1;
BA_ "SPN" SG_ 2432541438 EngGas2MassFlowRate 3467;
BA_ "SigType" SG_ 2432541438 EngFuelValve2IntakeAbsPress 1;
BA_ "SPN" SG_ 2432541438 EngFuelValve2IntakeAbsPress 3466;
BA_ "SigType" SG_ 2566760960 EngCentrifugalOilFilterSpeed 1;
BA_ "SPN" SG_ 2566760960 EngCentrifugalOilFilterSpeed 3343;
BA_ "SigType" SG_ 2566760960 EngCoolantPumpDiffPress 1;
BA_ "SPN" SG_ 2566760960 EngCoolantPumpDiffPress 3342;
BA_ "SigType" SG_ 2566760960 EngChargeAirCooler2IntakePress 1;
BA_ "SPN" SG_ 2566760960 EngChargeAirCooler2IntakePress 3341;
BA_ "SigType" SG_ 2566760960 EngChargeAirCooler1IntakePress 1;
BA_ "SPN" SG_ 2566760960 EngChargeAirCooler1IntakePress 3340;
BA_ "SigType" SG_ 2566760960 EngIntercoolerCoolantLevel 1;
BA_ "SPN" SG_ 2566760960 EngIntercoolerCoolantLevel 3668;
BA_ "SigType" SG_ 2566760960 EngChargeAirCoolerOutletPress 1;
BA_ "SPN" SG_ 2566760960 EngChargeAirCoolerOutletPress 2631;
BA_ "SigType" SG_ 2566760960 EngAftercoolerCoolantLevel 1;
BA_ "SPN" SG_ 2566760960 EngAftercoolerCoolantLevel 3676;
BA_ "SigType" SG_ 2432541440 EngVrableGeometryTurboActuator1 1;
BA_ "SPN" SG_ 2432541440 EngVrableGeometryTurboActuator1 641;
BA_ "SigType" SG_ 2432541440 EngTrbCmprssrBypssActtr1TmpStts 4;
BA_ "SPN" SG_ 2432541440 EngTrbCmprssrBypssActtr1TmpStts 5368;
BA_ "SigType" SG_ 2432541440 EngTrbCmprssrBypssActtr1PrlmnryF 1;
BA_ "SPN" SG_ 2432541440 EngTrbCmprssrBypssActtr1PrlmnryF 5367;
BA_ "SystemSignalLongSymbol" SG_ 2432541440 EngTrbCmprssrBypssActtr1PrlmnryF "EngTrbCmprssrBypssActtr1PrlmnryFMI";
BA_ "SigType" SG_ 2432541440 EngTrbCmprssrBypassActuator2Cmd 1;
BA_ "SPN" SG_ 2432541440 EngTrbCmprssrBypassActuator2Cmd 5369;
BA_ "SigType" SG_ 2432541440 EngTrbCmprssrBypassActuator1Pos 1;
BA_ "SPN" SG_ 2432541440 EngTrbCmprssrBypassActuator1Pos 3675;
BA_ "SigType" SG_ 2432541440 EngTrbCmprssrBypassActuator1Cmd 1;
BA_ "SPN" SG_ 2432541440 EngTrbCmprssrBypassActuator1Cmd 3470;
BA_ "SigType" SG_ 2432541440 EngDsrdTrbCmprssrBypssActtr1Pos 1;
BA_ "SPN" SG_ 2432541440 EngDsrdTrbCmprssrBypssActtr1Pos 5366;
VAL_ 2633825022 EngExhstGsRcrclation2Valve2Ctrl 4 "MeansMaxOpening" ;
VAL_ 2633825022 EngExhstGsRcrculation2ValveCtrl 4 "MeansMaxOpening" ;
VAL_ 2566749184 DslPrtcltFltrActvRgnrtnFrcdStts 7 "notAvailable" 6 "ReservedForSAEAssignment" 2 "ActiveForcedByServiceTool" 1 "ActiveForcedBySwitch" 0 "NotActive" ;
VAL_ 2566749184 ExhaustSystemHighTempLampCmd 7 "notAvailable" 6 "reservedForSAEAssignment" 1 "OnSolid" 0 "Off" ;
VAL_ 2566749184 DslPrtcltFltrAtmtcActvRgnrtnIntt 3 "notAvailable" 2 "reservedForSAEAssignment" 1 "enabled" 0 "notEnabled" ;
VAL_ 2566749184 DslPrtcltFltrActvRgnrtnInhbtdDTV 3 "notAvailable" 2 "reservedForSAEAssignment" 1 "inhibited" 0 "notInhibited" ;
VAL_ 2566749184 DslPrtcltFltrActvRgnrtnInhbtdDTE 3 "notAvailable" 2 "reservedForSAEAssignment" 1 "inhibited" 0 "notInhibited" ;
VAL_ 2566749184 DslPrtcltFltrActvRgnrtnInhbtdDTP 3 "notAvailable" 2 "reservedForSAEAssignment" 1 "inhibited" 0 "notInhibited" ;
VAL_ 2566749184 DslPrtcltFltrActvRgnrtnInhbtdDTT 3 "notAvailable" 2 "reservedForSAEAssignment" 1 "inhibited" 0 "notInhibited" ;
VAL_ 2566749184 DslPrtcltFltrActvRgnrtnInhbtdDTS 3 "notAvailable" 2 "reservedForSAEAssignment" 1 "inhibited" 0 "notInhibited" ;
VAL_ 2566749184 DslPrtcltFltrActvRgnrtnInhb_0000 3 "notAvailable" 2 "reservedForSAEAssignment" 1 "inhibited" 0 "notInhibited" ;
VAL_ 2566749184 DslPrtcltFltrActvRgnrtnInhbtdDTL 3 "notAvailable" 2 "reservedForSAEAssignment" 1 "inhibited" 0 "notInhibited" ;
VAL_ 2566749184 DslPrtcltFltrActvRgnrtnInhb_0001 3 "notAvailable" 2 "reservedForSAEAssignment" 1 "inhibited" 0 "notInhibited" ;
VAL_ 2566749184 DslPrtcltFltrActvRgnrtnInhb_0002 3 "notAvailable" 2 "reservedForSAEAssignment" 1 "inhibited" 0 "notInhibited" ;
VAL_ 2566749184 DslPrtcltFltrActvRgnrtnInhbtdDTO 3 "notAvailable" 2 "reservedForSAEAssignment" 1 "inhibited" 0 "notInhibited" ;
VAL_ 2566749184 DslPrtcltFltrActvRgnrtnInhbtdDTA 3 "notAvailable" 2 "reservedForSAEAssignment" 1 "inhibited" 0 "notInhibited" ;
VAL_ 2566749184 DslPrtcltFltrActvRgnrtnInhb_0003 3 "notAvailable" 2 "reservedForSAEAssignment" 1 "inhibited" 0 "notInhibited" ;
VAL_ 2566749184 DslPrtcltFltrActvRgnrtnInhb_0004 3 "notAvailable" 2 "reservedForSAEAssignment" 1 "inhibited" 0 "notInhibited" ;
VAL_ 2566749184 DslPrtcltFltrActvRgnrtnInhbtdDTC 3 "notAvailable" 2 "reservedForSAEAssignment" 1 "inhibited" 0 "notInhibited" ;
VAL_ 2566749184 DslPrtcltFltrActvRgnrtnInhbtdDTI 3 "notAvailable" 2 "reservedForSAEAssignment" 1 "inhibited" 0 "notInhibited" ;
VAL_ 2566749184 DslPrtcltFltrActvRgnrtnInhbtdStt 3 "notAvailable" 2 "reservedForSAEAssignment" 1 "inhibited" 0 "notInhibited" ;
VAL_ 2566749184 DieselParticulateFilterStatus 7 "notAvailable" 6 "reservedForSAEAssignment" 3 "RegenerationNeededHighestLevel" 2 "RegenerationNeededModerateLevel" 1 "RegenerationNeededLowestLevel" 0 "RegenerationNotNeeded" ;
VAL_ 2566749184 DslPrtcltFltrActvRgnrtionStatus 3 "notAvailable" 2 "rgnrtnNddAtmtcllyInttdActvRgnrt" 1 "active" 0 "notActive" ;
VAL_ 2566749184 DslPrtcltFltrPssvRgnrtionStatus 3 "notAvailable" 2 "reservedForSAEAssignment" 1 "active" 0 "notActive" ;
VAL_ 2566749184 DieselParticulateFilterLampCmd 7 "notAvailable" 4 "OnFastBlink" 6 "reservedForSAEAssignment" 1 "OnSolid" 0 "Off" ;
VAL_ 2566718464 VehicleBatteryChargingLampData 3 "NotAvailable" 2 "Error" 1 "LampActivated" 0 "LampDeactivated" ;
VAL_ 2566718464 VhicleHVACRecirculationLampData 3 "NotAvailable" 2 "Error" 1 "LampActivated" 0 "LampDeactivated" ;
VAL_ 2566718464 VehicleAirPressLowLampData 3 "NotAvailable" 2 "Error" 1 "LampActivated" 0 "LampDeactivated" ;
VAL_ 2566718464 VehicleFuelLevelLowLampData 3 "NotAvailable" 2 "Error" 1 "LampActivated" 0 "LampDeactivated" ;
VAL_ 2566718464 VhicleBatteryVoltageLowLampData 3 "NotAvailable" 2 "Error" 1 "LampActivated" 0 "LampDeactivated" ;
VAL_ 2566718720 EngWaitToStartLampData 3 "NotAvailable" 2 "Error" 1 "LampActive" 0 "LampDeactive" ;
VAL_ 2566718720 EngFuelFilterRestrictedLampData 3 "NotAvailable" 2 "Error" 1 "LampActivated" 0 "LampDeactivated" ;
VAL_ 2566718720 EngAirFilterRestrictionLampData 3 "NotAvailable" 2 "Error" 1 "LampActivated" 0 "LampDeactivated" ;
VAL_ 2566718720 EngIdleManagementActiveLampData 3 "NotAvailable" 2 "Error" 1 "LampActivated" 0 "LampDeactivated" ;
VAL_ 2566718720 EngCoolantLevelLowLampData 3 "NotAvailable" 2 "Error" 1 "LampActivated" 0 "LampDeactivated" ;
VAL_ 2566718720 EngCoolantTempHighLampData 3 "NotAvailable" 2 "Error" 1 "LampActivated" 0 "LampDeactivated" ;
VAL_ 2566718720 EngOilPressLowLampData 3 "NotAvailable" 2 "Error" 1 "LampActivated" 0 "LampDeactivated" ;
VAL_ 2566718720 CmprssnBrkEnblSwtchIndctrLmpDta 3 "NotAvailable" 2 "Error" 1 "LampActivated" 0 "LampDeactivated" ;
VAL_ 2566718720 EngBrakeActiveLampData 3 "NotAvailable" 2 "Error" 1 "LampActivated" 0 "LampDeactivated" ;
VAL_ 2566718720 OBDMalfunctionIndicatorLampData 3 "NotAvailable" 2 "Error" 1 "LampActivated" 0 "LampDeactivated" ;
VAL_ 2566718720 EngRedStopLampData 3 "NotAvailable" 2 "Error" 1 "LampActivated" 0 "LampDeactivated" ;
VAL_ 2566718720 EngAmberWarningLampData 3 "NotAvailable" 2 "Error" 1 "LampActivated" 0 "LampDeactivated" ;
VAL_ 2566718720 EngProtectLampData 3 "NotAvailable" 2 "Error" 1 "LampActivated" 0 "LampDeactivated" ;
VAL_ 2566718976 VehicleBatteryChargingLampCmd 3 "NotAvailable" 2 "Reserved" 1 "LampOn" 0 "LampOff" ;
VAL_ 2566718976 VehicleHVACRecirculationLampCmd 3 "NotAvailable" 2 "Reserved" 1 "LampOn" 0 "LampOff" ;
VAL_ 2566718976 VehicleAirPressLowLampCmd 3 "NotAvailable" 2 "Reserved" 1 "LampOn" 0 "LampOff" ;
VAL_ 2566718976 VehicleFuelLevelLowLampCmd 3 "NotAvailable" 2 "Reserved" 1 "LampOn" 0 "LampOff" ;
VAL_ 2566718976 VehicleBatteryVoltageLowLampCmd 3 "NotAvailable" 2 "Reserved" 1 "LampOn" 0 "LampOff" ;
VAL_ 2560818942 FailureModeIdentifier1 31 "Not available" 19 "Received network data in error" 18 "Below normal (moderatels severe)" 17 "Below normal (least severe)" 16 "Above normal (moderately severe)" 15 "Above normal (least severe)" 14 "Special intstructions" 13 "Out of calibration" 12 "Bad intelligent device" 11 "Root cause not known" 10 "Abnormal rate of change" 9 "Abnormal update rate" 8 "Abnormal frequency" 7 "Mechanical system not responding" 6 "Current above normal" 5 "Current below normal" 4 "Voltage below normal" 3 "Voltage above normal" 2 "Data erratic" 1 "Below normal (most severe)" 0 "Above normal (most severe)" ;
VAL_ 2561212158 TextDisplayInstructions 7 "1110Reserved" 6 "BlinkSubstring" 15 "NotApplicable" 1 "HldDsplyPrsntlyDsplydInfrmtnShl" 0 "ClrDsplyDsplydInfrmtnShldBDltdN" 5 "HighlightSubstring" 4 "OvrwrtSbstrngAPrtnOfPrsntlyDspl" 3 "OvrwrtDsplyPrsntlyDsplydInfrmtn" 2 "AppndAtEndOfDsplyTrnsmttdInfrmt" ;
VAL_ 2566746366 RetractStatusOfRamp5 2 "error" 1 "rampEx" 0 "rampRetracted" 3 "notAvailable" ;
VAL_ 2566746366 RetractStatusOfRamp4 3 "notAvailable" 2 "error" 1 "rampEx" 0 "rampRetracted" ;
VAL_ 2566746366 MovementStatusOfRamp5 3 "notAvailable" 2 "error" 1 "rampBeingMoved" 0 "rampNotBeingMoved" ;
VAL_ 2566746366 MovementStatusOfRamp4 3 "notAvailable" 2 "error" 1 "rampBeingMoved" 0 "rampNotBeingMoved" ;
VAL_ 2566746366 EnableStatusOfRamp5 3 "notAvailable" 2 "error" 1 "rampEnabled" 0 "rampDisabled" ;
VAL_ 2566746366 EnableStatusOfRamp4 3 "notAvailable" 2 "error" 1 "rampEnabled" 0 "rampDisabled" ;
VAL_ 2566746366 MovementStatusOfRamp3 3 "notAvailable" 2 "error" 1 "rampBeingMoved" 0 "rampNotBeingMoved" ;
VAL_ 2566746366 EnableStatusOfRamp3 3 "notAvailable" 2 "error" 1 "rampEnabled" 0 "rampDisabled" ;
VAL_ 2566746366 RetractStatusOfRamp3 3 "notAvailable" 2 "error" 1 "rampEx" 0 "rampRetracted" ;
VAL_ 2566746366 MovementStatusOfRamp2 3 "notAvailable" 2 "error" 1 "rampBeingMoved" 0 "rampNotBeingMoved" ;
VAL_ 2566746366 EnableStatusOfRamp2 3 "notAvailable" 2 "error" 1 "rampEnabled" 0 "rampDisabled" ;
VAL_ 2566746366 RetractStatusOfRamp2 3 "notAvailable" 2 "error" 1 "rampEx" 0 "rampRetracted" ;
VAL_ 2566746366 MovementStatusOfRamp1 3 "notAvailable" 2 "error" 1 "rampBeingMoved" 0 "rampNotBeingMoved" ;
VAL_ 2566746366 EnableStatusOfRamp1 3 "notAvailable" 2 "error" 1 "rampEnabled" 0 "rampDisabled" ;
VAL_ 2566746366 RetractStatusOfRamp1 3 "notAvailable" 2 "error" 1 "rampEx" 0 "rampRetracted" ;
VAL_ 2566745856 EngExhstGsRcrclation1Valve2Ctrl 4 "MeansMaxValveOpening" ;
VAL_ 2561277694 LaneDepartureWarningEnableCmd 3 "DonTCare" 2 "Reserved" 1 "EnableLaneDepartureWarning" 0 "DisableLaneDepartureWarning" ;
VAL_ 2633861886 J2012DTCStatus 1 "DTCIsActive" 0 "DTCIsPreviouslyActive" ;
VAL_ 2565873150 SteerAngleSensorCalibrated 3 "NotAvailable" 2 "Reserved" 1 "SASCalibrated" 0 "SASNotCalibrated" ;
VAL_ 2565873150 SteerAngleSensorActiveMode 3 "NotAvailable" 2 "Reserved" 1 "NormalModeActive" 0 "ProgrammingModeActive" ;
VAL_ 2565873150 SteerWheelAngleRangeCounterType 3 "SignalNotAvailable" 2 "NotDefined" 1 "AbsNumberOfCounts" 0 "RelativeNumberOfCounts" ;
VAL_ 2566751230 TransferCaseStatus 7 "notAvailable" 6 "error" 5 "TrnsfrCsShftInPrgrssGrNtCnfrmed" 4 "WheelLow" 2 "neutral" 1 "WheelHigh" ;
VAL_ 2566755838 TransOverheatIndicator 3 "NotAvailable" 2 "TrnsOverheatIndicatorIsFlashing" 1 "TrnsOvrhtIndctrIsOnContinuously" 0 "TransOverheatIndicatorIsOff" ;
VAL_ 2566755838 TransOilLevelSwitch 3 "NotAvailable" 2 "Error" 1 "FullNotEmpty" 0 "Empty" ;
VAL_ 2566755838 TransOilFilterRestrictionSwitch 3 "NotAvailable" 2 "Error" 1 "RestrictionExistsOnOilFilter" 0 "NoRestriction" ;
VAL_ 2566799614 ImplementRearWorkLight 3 "NotAvailable" 2 "FaultDetected" 1 "Activated" 0 "Deactivated" ;
VAL_ 2566799614 ImplementLeftForwardWorkLight 3 "NotAvailable" 2 "FaultDetected" 1 "Activated" 0 "Deactivated" ;
VAL_ 2566799614 ImplementRightForwardWorkLight 3 "NotAvailable" 2 "FaultDetected" 1 "Activated" 0 "Deactivated" ;
VAL_ 2566799614 ImplementLeftFacingWorkLight 3 "NotAvailable" 2 "FaultDetected" 1 "Activate" 0 "Deactivate" ;
VAL_ 2566799614 ImplementRightFacingWorkLight 3 "NotAvailable" 2 "FaultDetected" 1 "Activated" 0 "Deactivated" ;
VAL_ 2566799614 ImplementOEMOption1Light 3 "NotAvailable" 2 "FaultDetected" 1 "Activated" 0 "Deactivated" ;
VAL_ 2566799614 ImplementOEMOption2Light 3 "NotAvailable" 2 "FaultDetected" 1 "Activated" 0 "Deactivated" ;
VAL_ 2566799614 TrctrFrontHighMountedWorkLights 3 "NotAvailable" 2 "FaultDetected" 1 "Activated" 0 "Deactivated" ;
VAL_ 2566799614 TrctorFrontLowMountedWorkLights 3 "NotAvailable" 2 "FaultDetected" 1 "Activated" 0 "Deactivated" ;
VAL_ 2566799614 TrctorSideHighMountedWorkLights 3 "NotAvailable" 2 "FaultDetected" 1 "Activated" 0 "Deactivated" ;
VAL_ 2566799614 TractorSideLowMountedWorkLights 3 "NotAvailable" 2 "FaultDetected" 1 "Activated" 0 "Deactivated" ;
VAL_ 2566799614 TrctorRearHighMountedWorkLights 3 "NotAvailable" 2 "FaultDetected" 1 "Activated" 0 "Deactivated" ;
VAL_ 2566799614 TractorRearLowMountedWorkLights 3 "NotAvailable" 2 "FaultDetected" 1 "Activated" 0 "Deactivated" ;
VAL_ 2566799614 TrctrUndersideMountedWorkLights 3 "NotAvailable" 2 "FaultDetected" 1 "Activated" 0 "Deactivated" ;
VAL_ 2566799614 RearFogLights 3 "NotAvailable" 2 "FaultDetected" 1 "Activated" 0 "Deactivated" ;
VAL_ 2566799614 TractorMarkerLight 3 "NotAvailable" 2 "FaultDetected" 1 "Activated" 0 "Deactivated" ;
VAL_ 2566799614 ImplementMarkerLight 3 "NotAvailable" 2 "FaultDetected" 1 "Activated" 0 "Deactivated" ;
VAL_ 2566799614 TractorClearanceLight 3 "NotAvailable" 2 "FaultDetected" 1 "Activated" 0 "Deactivated" ;
VAL_ 2566799614 ImplementClearanceLight 3 "NotAvailable" 2 "FaultDetected" 1 "Activated" 0 "Deactivated" ;
VAL_ 2566799614 LeftStopLight 3 "NotAvailable" 2 "FaultDetected" 1 "Activated" 0 "Deactivated" ;
VAL_ 2566799614 RightStopLight 3 "NotAvailable" 2 "FaultDetected" 1 "Activated" 0 "Deactivated" ;
VAL_ 2566799614 CenterStopLight 3 "NotAvailable" 2 "FaultDetected" 1 "Activated" 0 "Deactivated" ;
VAL_ 2566799614 BackUpLightAndAlarmHorn 3 "NotAvailable" 2 "FaultDetected" 1 "Activated" 0 "Deactivated" ;
VAL_ 2566799614 LeftTurnSignalLights 3 "NotAvailable" 2 "FaultDetected" 1 "Activated" 0 "Deactivated" ;
VAL_ 2566799614 RightTurnSignalLights 3 "NotAvailable" 2 "FaultDetected" 1 "Activated" 0 "Deactivated" ;
VAL_ 2566799614 RotatingBeaconLight 3 "NotAvailable" 2 "FaultDetected" 1 "Activated" 0 "Deactivated" ;
VAL_ 2566799614 TractorFrontFogLights 3 "NotAvailable" 2 "FaultDetected" 1 "Activated" 0 "Deactivated" ;
VAL_ 2566799614 HighBeamHeadLightData 3 "NotAvailable" 2 "FaultDetected" 1 "Activated" 0 "Deactivated" ;
VAL_ 2566799614 LowBeamHeadLightData 3 "NotAvailable" 2 "FaultDetected" 1 "Activated" 0 "Deactivated" ;
VAL_ 2566799614 AltBeamHeadLightData 3 "NotAvailable" 2 "FaultDetected" 1 "Activated" 0 "Deactivated" ;
VAL_ 2566799614 RunningLight 3 "NotAvailable" 2 "FaultDetected" 1 "Activated" 0 "Deactivated" ;
VAL_ 2365473278 ImplementRearWorkLightCmd 3 "DonTCare" 2 "Reserved" 1 "Activate" 0 "Deactivate" ;
VAL_ 2365473278 ImplmentLeftForwardWorkLightCmd 3 "DonTCare" 2 "Reserved" 1 "Activate" 0 "Deactivate" ;
VAL_ 2365473278 ImplmntRightForwardWorkLightCmd 3 "DonTCare" 2 "Reserved" 1 "Activate" 0 "Deactivate" ;
VAL_ 2365473278 LightingDataRqCmd 3 "DonTCare" 2 "Reserved" 1 "Activate" 0 "Deactivate" ;
VAL_ 2365473278 ImplementLeftFacingWorkLightCmd 3 "DonTCare" 2 "Reserved" 1 "Activate" 0 "Deactivate" ;
VAL_ 2365473278 ImplmentRightFacingWorkLightCmd 3 "DonTCare" 2 "Reserved" 1 "Activate" 0 "Deactivate" ;
VAL_ 2365473278 ImplementOEMOption1LightCmd 3 "DonTCare" 2 "Reserved" 1 "Activate" 0 "Deactivate" ;
VAL_ 2365473278 ImplementOEMOption2LightCmd 3 "DonTCare" 2 "Reserved" 1 "Activate" 0 "Deactivate" ;
VAL_ 2365473278 TrctrFrntHghMuntedWorkLightsCmd 3 "DonTCare" 2 "Reserved" 1 "Activate" 0 "Deactivate" ;
VAL_ 2365473278 TrctrFrntLwMountedWorkLightsCmd 3 "DonTCare" 2 "Reserved" 1 "Activate" 0 "Deactivate" ;
VAL_ 2365473278 TrctrSdHighMountedWorkLightsCmd 3 "DonTCare" 2 "Reserved" 1 "Activate" 0 "Deactivate" ;
VAL_ 2365473278 TrctrSdeLowMountedWorkLightsCmd 3 "DonTCare" 2 "Reserved" 1 "Activate" 0 "Deactivate" ;
VAL_ 2365473278 TrctrRrHighMountedWorkLightsCmd 3 "DonTCare" 2 "Reserved" 1 "Activate" 0 "Deactivate" ;
VAL_ 2365473278 TrctrRarLowMountedWorkLightsCmd 3 "DonTCare" 2 "Reserved" 1 "Activate" 0 "Deactivate" ;
VAL_ 2365473278 TrctrUndrsdMountedWorkLightsCmd 3 "DonTCare" 2 "Reserved" 1 "Activate" 0 "Deactivate" ;
VAL_ 2365473278 RearFogLightCmd 3 "DonTCare" 2 "Reserved" 1 "Activate" 0 "Deactivate" ;
VAL_ 2365473278 TractorMarkerLightCmd 3 "DonTCare" 2 "Reserved" 1 "Activate" 0 "Deactivate" ;
VAL_ 2365473278 ImplementMarkerLightCmd 3 "DonTCare" 2 "Reserved" 1 "Activate" 0 "Deactivate" ;
VAL_ 2365473278 TractorClearanceLightCmd 3 "DonTCare" 2 "Reserved" 1 "Activate" 0 "Deactivate" ;
VAL_ 2365473278 ImplementClearanceLightCmd 3 "DonTCare" 2 "Reserved" 1 "Activate" 0 "Deactivate" ;
VAL_ 2365473278 LeftStopLightCmd 3 "DonTCare" 2 "Reserved" 1 "Activate" 0 "Deactivate" ;
VAL_ 2365473278 RightStopLightCmd 3 "DonTCare" 2 "Reserved" 1 "Activate" 0 "Deactivate" ;
VAL_ 2365473278 CenterStopLightCmd 3 "DonTCare" 2 "Reserved" 1 "Activate" 0 "Deactivate" ;
VAL_ 2365473278 BackUpLightAndAlarmHornCmd 3 "DonTCare" 2 "Reserved" 1 "Activate" 0 "Deactivate" ;
VAL_ 2365473278 LeftTurnSignalLightsCmd 3 "DonTCare" 2 "Reserved" 1 "Activate" 0 "Deactivate" ;
VAL_ 2365473278 RightTurnSignalLightsCmd 3 "DonTCare" 2 "Reserved" 1 "Activate" 0 "Deactivate" ;
VAL_ 2365473278 RotatingBeaconLightCmd 3 "DonTCare" 2 "Reserved" 1 "Activate" 0 "Deactivate" ;
VAL_ 2365473278 TractorFrontFogLightsCmd 3 "DonTCare" 2 "Reserved" 1 "Activate" 0 "Deactivate" ;
VAL_ 2365473278 HighBeamHeadLightCmd 3 "DonTCare" 2 "Reserved" 1 "Activate" 0 "Deactivate" ;
VAL_ 2365473278 LowBeamHeadLightCmd 3 "DonTCare" 2 "Reserved" 1 "Activate" 0 "Deactivate" ;
VAL_ 2365473278 AltBeamHeadLightCmd 3 "DonTCare" 2 "Reserved" 1 "Activate" 0 "Deactivate" ;
VAL_ 2365473278 RunningLightCmd 3 "DonTCare" 2 "Reserved" 1 "Activate" 0 "Deactivate" ;
VAL_ 2365485822 BladeCtrlMode 2 "InactiveAutomaticMode" 1 "AutomaticMode" 0 "ManualMode" ;
VAL_ 2365485822 LandLevelingSystemEnableStatus 3 "NotAvailable_NotInstalled" 2 "Error" 1 "Enabled" 0 "Disabled" ;
VAL_ 2365485822 BladeCtrlModeRight 15 "NotAvailable" 14 "Error" 3 "1101Reserved" 2 "InactiveAuto" 1 "Auto" 0 "Manual" ;
VAL_ 2365485822 BladeCtrlModeLeft 15 "NotAvailable" 14 "Error" 3 "1101Reserved" 2 "InactiveAuto" 1 "Auto" 0 "Manual" ;
VAL_ 2566768894 EngOprtrPrmryIntrmdtSpdSlctStte 15 "NotAvailable" 14 "SAEReserved" 1 "thr1101CtrlSttIsISCSttng1Thru13" 0 "CtrlSttIsISCFnctnltyIsNtRqdEngO" ;
VAL_ 2566769406 EngOprtrPrmryIntrmdtSpeedSelect 15 "NotAvailable" 14 "ErrorCondition" 1 "thr1101IndctsThtISCSttng1Thr13I" 0 "IndctsThtISCFnctnltyIsNtRqdEngO" ;
VAL_ 2566811134 CabHeatingZone 3 "NotAvailable" 2 "Reserved" 1 "CabHeatingZoneOn" 0 "CabHeatingZoneOff" ;
VAL_ 2566811134 EngHeatingZone 3 "NotAvailable" 2 "Reserved" 1 "EngHeatingZoneOn" 0 "EngHeatingZoneOff" ;
VAL_ 2566811134 CabVentilation 3 "NotAvailable" 2 "Reserved" 1 "CabIsVentilated" 0 "CabNotVentilated" ;
VAL_ 2566811134 AuxHeaterMode 15 "NotAvailable" 14 "Error" 4 "1101NotDefined" 3 "NormalMode" 2 "EconomyMode" 1 "OffDTADRPrErpnRgltnsFrTrnsprtOf" 0 "HeaterNotActive" ;
VAL_ 2566811134 AuxHeaterWaterPumpStatus 3 "NotAvailable" 2 "Reserved" 1 "WaterPumpIsRunning" 0 "WaterPumpIsNotRunning" ;
VAL_ 2565867774 FireApparatusPumpEngagement 3 "NotAvailableNotInstalled" 2 "Error" 1 "PumpEngaged" 0 "PumpNotEngaged" ;
VAL_ 2565867774 EngHydPressGovernorSwitch 3 "NotAvailable" 2 "ErrorIndicator" 1 "PressModeActive" 0 "PressModeInactive" ;
VAL_ 2565867774 EngHydPrssGovernorModeIndicator 3 "NotAvailable" 2 "ErrorIndicator" 1 "Enabled" 0 "Disabled" ;
VAL_ 2365449982 HydBrakeFluidLevelSwitch 3 "NotAvailable" 2 "ErrorIndicator" 1 "FluidLevelIsSufficient" 0 "FluidLevelIsNotSufficient" ;
VAL_ 2365449982 HydBrakeSystemAudibleWarningCmd 3 "DontCare" 2 "Reserved" 1 "AudibleWarningOn" 0 "AudibleWarningOff" ;
VAL_ 2365449982 HydBrkePressSupplyStateCircuit2 3 "NotAvailable" 2 "ErrorIndicator" 1 "SupplyIsReliable" 0 "SupplyIsNotReliable" ;
VAL_ 2365449982 HydBrkePressSupplyStateCircuit1 3 "NotAvailable" 2 "ErrorIndicator" 1 "SupplyIsReliable" 0 "SupplyIsNotReliable" ;
VAL_ 2365449982 HydBrkPressWarningStateCircuit2 3 "NotAvailable" 2 "ErrorIndicator" 1 "PressLevelBelowWarningLevel" 0 "PressLevelSufficient" ;
VAL_ 2365449982 HydBrkPressWarningStateCircuit1 3 "NotAvailable" 2 "ErrorIndicator" 1 "PressLevelBelowWarningLevel" 0 "PressLevelSufficient" ;
VAL_ 2566759678 EnggmntSttusTransInputShaftPTO1 3 "NotAvailable" 2 "Error" 1 "DriveIsEngaged" 0 "DriveNotEngaged" ;
VAL_ 2566759678 EnggmntSttusTransInputShaftPTO2 3 "NotAvailable" 2 "Error" 1 "DriveIsEngaged" 0 "DriveNotEngaged" ;
VAL_ 2566759678 EnggmntSttusTransOutputShaftPTO 3 "NotAvailable" 2 "Error" 1 "DriveIsEngaged" 0 "DriveNotEngaged" ;
VAL_ 2566759678 EnggmntSttsTrnsfrCsOtptShaftPTO 3 "NotAvailable" 2 "Error" 1 "DriveIsEngaged" 0 "DriveNotEngaged" ;
VAL_ 2566759678 EnggmntCnsntTransInputShaftPTO1 3 "NotAvailable" 2 "Error" 1 "CnsentGivenPTODriveMayBeEngaged" 0 "CnsntNtGvnPTODrvShldNtBeEngaged" ;
VAL_ 2566759678 EnggmntCnsntTransInputShaftPTO2 3 "NotAvailable" 2 "Error" 1 "CnsentGivenPTODriveMayBeEngaged" 0 "CnsntNtGvnPTODrvShldNtBeEngaged" ;
VAL_ 2566759678 EnggmntCnsntTransOutputShaftPTO 3 "NotAvailable" 2 "Error" 1 "CnsentGivenPTODriveMayBeEngaged" 0 "CnsntNtGvnPTODrvShldNtBeEngaged" ;
VAL_ 2566759678 EnggmntCnsntTrnsfrCsOtptShftPTO 3 "NotAvailable" 2 "Error" 1 "CnsentGivenPTODriveMayBeEngaged" 0 "CnsntNtGvnPTODrvShldNtBeEngaged" ;
VAL_ 2566759678 EnableSwitchTransInputShaftPTO1 3 "NotAvailable" 2 "Error" 1 "EnblSwtchOffPTOOperationDesired" 0 "EnblSwtchOffPTOOprtonNotDesired" ;
VAL_ 2566759678 EnableSwitchTransInputShaftPTO2 3 "NotAvailable" 2 "Error" 1 "EnblSwtchOffPTOOperationDesired" 0 "EnblSwtchOffPTOOprtonNotDesired" ;
VAL_ 2566759678 EnableSwitchTransOutputShaftPTO 3 "NotAvailable" 2 "Error" 1 "EnblSwtchOffPTOOperationDesired" 0 "EnblSwtchOffPTOOprtonNotDesired" ;
VAL_ 2566759678 EnblSwtchTrnsfrCsOutputShaftPTO 3 "NotAvailable" 2 "Error" 1 "EnblSwtchOffPTOOperationDesired" 0 "EnblSwtchOffPTOOprtonNotDesired" ;
VAL_ 2566759678 EnggmntSttsPTOEngAccssoryDrive2 3 "NotAvailable" 2 "Error" 1 "DriveEngaged" 0 "DriveNotEngaged" ;
VAL_ 2566759678 EnggmntSttsPTOEngAccssoryDrive1 3 "NotAvailable" 2 "Error" 1 "DriveEngaged" 0 "DriveNotEngaged" ;
VAL_ 2566759678 EnggmntCnsntPTOEngAccssryDrive2 3 "NotAvailable" 2 "Error" 1 "CnsentGivenPTODriveMayBeEngaged" 0 "CnsntNtGvnPTODrvMayNotBeEngaged" ;
VAL_ 2566759678 EnggmntCnsntPTOEngAccssryDrive1 3 "NotAvailable" 2 "Error" 1 "CnsentGivenPTODriveMayBeEngaged" 0 "CnsntNtGvnPTODrvMayNotBeEngaged" ;
VAL_ 2566759678 EngagementStatusPTOEngFlywheel 3 "NotAvailable" 2 "Error" 1 "DriveEngaged" 0 "DriveNotEngaged" ;
VAL_ 2566759678 EngagementConsentPTOEngFlywheel 3 "NotAvailable" 2 "Error" 1 "CnsentGivenPTODriveMayBeEngaged" 0 "CnsntNtGvnPTODrvMayNotBeEngaged" ;
VAL_ 2566759678 EnblSwitchPTOEngAccessoryDrive2 3 "NotAvailable" 2 "Error" 1 "EnblSwitchOnPTOOperationDesired" 0 "EnblSwtchOffPTOOprtonNotDesired" ;
VAL_ 2566759678 EnblSwitchPTOEngAccessoryDrive1 3 "NotAvailable" 2 "Error" 1 "EnblSwitchOnPTOOperationDesired" 0 "EnblSwtchOffPTOOprtonNotDesired" ;
VAL_ 2566759678 EnableSwitchPTOEngFlywheel 3 "NotAvailable" 2 "Error" 1 "EnblSwitchOnPTOOperationDesired" 0 "EnblSwtchOffPTOOprtonNotDesired" ;
VAL_ 2566759678 AtLeastOnePTOEngaged 3 "NotAvailable" 2 "Error" 1 "AtLeastOnePTODriveIsEngaged" 0 "NoPTODriveIsEngaged" ;
VAL_ 2432541440 EngTrbCmprssrBypssActtr1TmpStts 7 "NotAvailable" 6 "Error" 5 "NotDefined" 4 "LowMostSevere" 3 "LowLeastSevere" 2 "InRange" 1 "HighLeastSevere" 0 "HighMostSevere" ;
VAL_ 2432541440 EngTrbCmprssrBypassActuator2Cmd 4 "RprsntsFllyOpnTypcllyTrbCmprssr" ;
VAL_ 2432541440 EngTrbCmprssrBypassActuator1Pos 4 "RprsntsBypssFllyOpnTypcllyCmprs" ;
VAL_ 2432541440 EngTrbCmprssrBypassActuator1Cmd 4 "RprsntsFllyOpnTypcllyTrbCmprssr" ;
